VERSION ""

NS_ :

BS_:

BU_: IHU

BO_ 3221225472 VECTOR__INDEPENDENT_SIG_MSG: 0 Vector__XXX
 SG_ Diag_ICM_REQ : 0|64@0+ (1,0) [0|0] "" Vector__XXX
 SG_ Diag_ICM_RES : 0|64@0+ (1,0) [0|0] "" Vector__XXX

BO_ 2015 DIAG_OBD_REQ_Broadcast: 8 Vector__XXX
 SG_ DIAG_OBD_REQ_Broadcast : 7|64@0+ (1,0) [0|0] ""  IHU

BO_ 0 New_Message_75: 8 Vector__XXX
 SG_ New_Signal_498 : 20|8@1+ (1,0) [0|0] "" Vector__XXX

BO_ 1536 NMm_Others: 8 Vector__XXX
 SG_ Nwmcommand : 0|1@0+ (1,0) [0|1] ""  IHU

BO_ 1928 Diag_DMC_REQ: 8 Vector__XXX
 SG_ Diag_DMC_REQ : 7|64@0+ (1,0) [0|0] ""  IHU

BO_ 1764 Calibration_Signals_REQ_ICM_7: 8 Vector__XXX
 SG_ Calibration_Signals_REQ_ICM_7 : 7|64@0+ (1,0) [0|0] ""  IHU

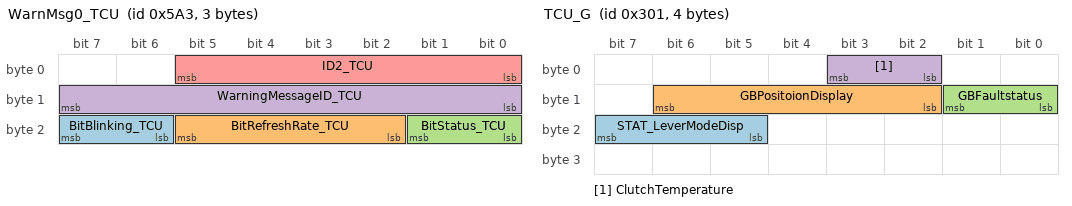
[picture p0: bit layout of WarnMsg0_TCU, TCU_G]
BO_ 1443 WarnMsg0_TCU: 3 Vector__XXX
 SG_ BitBlinking_TCU : 23|2@0+ (1,0) [0|3] ""  IHU
 SG_ BitRefreshRate_TCU : 21|4@0+ (1,0) [0|14] "second"  IHU
 SG_ BitStatus_TCU : 17|2@0+ (1,0) [0|3] ""  IHU
 SG_ WarningMessageID_TCU : 15|8@0+ (1,0) [0|255] ""  IHU
 SG_ ID2_TCU : 5|6@0+ (1,0) [0|63] ""  IHU

BO_ 769 TCU_G: 4 Vector__XXX
 SG_ STAT_LeverModeDisp : 23|3@0+ (1,0) [0|7] ""  IHU
 SG_ GBPositoionDisplay : 14|5@0+ (1,0) [0|31] ""  IHU
 SG_ GBFaultstatus : 9|2@0+ (1,0) [0|3] ""  IHU
 SG_ ClutchTemperature : 3|2@0+ (1,0) [0|3] ""  IHU

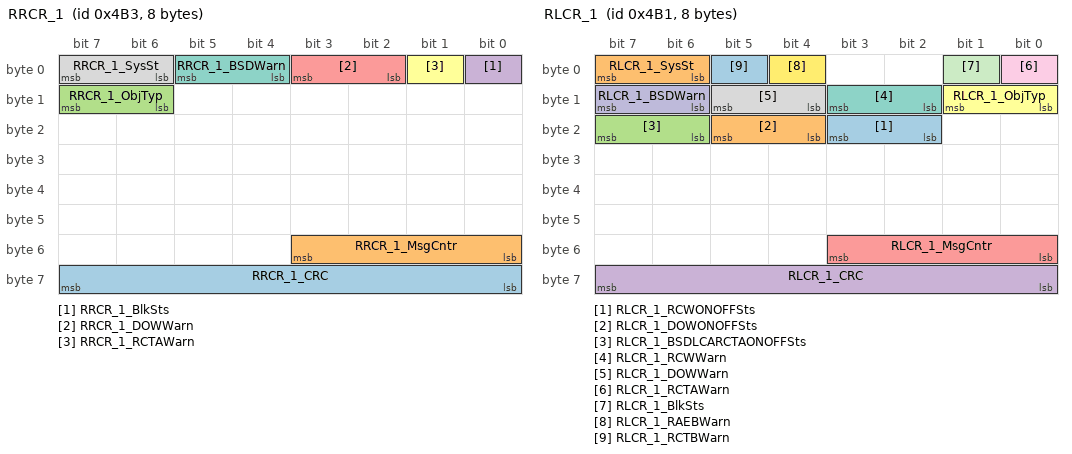
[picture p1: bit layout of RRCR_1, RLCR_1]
BO_ 1203 RRCR_1: 8 Vector__XXX
 SG_ RRCR_1_CRC : 63|8@0+ (1,0) [0|255] ""  IHU
 SG_ RRCR_1_MsgCntr : 51|4@0+ (1,0) [0|15] ""  IHU
 SG_ RRCR_1_ObjTyp : 15|2@0+ (1,0) [0|3] ""  IHU
 SG_ RRCR_1_BlkSts : 0|1@0+ (1,0) [0|1] ""  IHU
 SG_ RRCR_1_DOWWarn : 3|2@0+ (1,0) [0|3] ""  IHU
 SG_ RRCR_1_RCTAWarn : 1|1@0+ (1,0) [0|1] ""  IHU
 SG_ RRCR_1_BSDWarn : 5|2@0+ (1,0) [0|3] ""  IHU
 SG_ RRCR_1_SysSt : 7|2@0+ (1,0) [0|3] ""  IHU

BO_ 1201 RLCR_1: 8 Vector__XXX
 SG_ RLCR_1_RCWONOFFSts : 19|2@0+ (1,0) [0|3] ""  IHU
 SG_ RLCR_1_DOWONOFFSts : 21|2@0+ (1,0) [0|3] ""  IHU
 SG_ RLCR_1_BSDLCARCTAONOFFSts : 23|2@0+ (1,0) [0|3] ""  IHU
 SG_ RLCR_1_CRC : 63|8@0+ (1,0) [0|255] ""  IHU
 SG_ RLCR_1_MsgCntr : 51|4@0+ (1,0) [0|15] ""  IHU
 SG_ RLCR_1_ObjTyp : 9|2@0+ (1,0) [0|3] ""  IHU
 SG_ RLCR_1_RCWWarn : 11|2@0+ (1,0) [0|3] ""  IHU
 SG_ RLCR_1_DOWWarn : 13|2@0+ (1,0) [0|3] ""  IHU
 SG_ RLCR_1_RCTAWarn : 0|1@0+ (1,0) [0|1] ""  IHU
 SG_ RLCR_1_BSDWarn : 15|2@0+ (1,0) [0|3] ""  IHU
 SG_ RLCR_1_BlkSts : 1|1@0+ (1,0) [0|1] ""  IHU
 SG_ RLCR_1_RAEBWarn : 4|1@0+ (1,0) [0|1] ""  IHU
 SG_ RLCR_1_RCTBWarn : 5|1@0+ (1,0) [0|1] ""  IHU
 SG_ RLCR_1_SysSt : 7|2@0+ (1,0) [0|3] ""  IHU

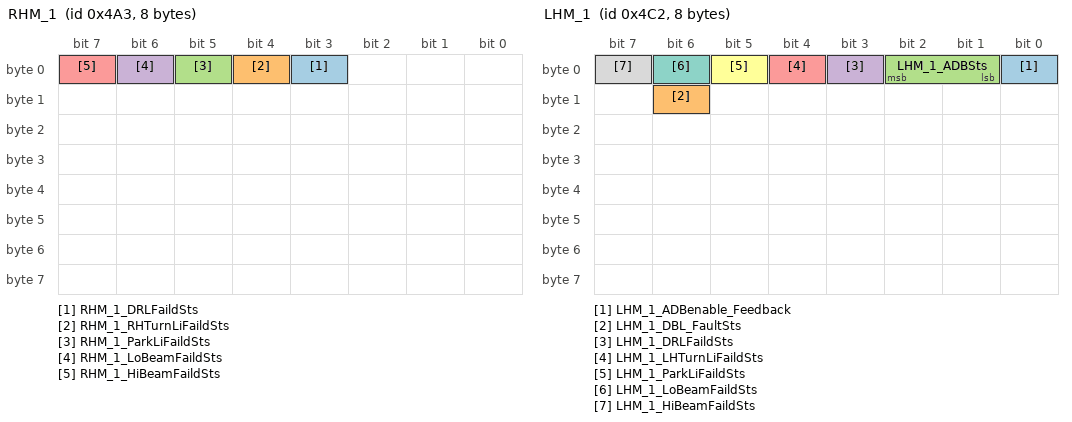
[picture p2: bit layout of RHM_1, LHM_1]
BO_ 1187 RHM_1: 8 Vector__XXX
 SG_ RHM_1_DRLFaildSts : 3|1@0+ (1,0) [0|1] ""  IHU
 SG_ RHM_1_RHTurnLiFaildSts : 4|1@0+ (1,0) [0|1] ""  IHU
 SG_ RHM_1_ParkLiFaildSts : 5|1@0+ (1,0) [0|1] ""  IHU
 SG_ RHM_1_LoBeamFaildSts : 6|1@0+ (1,0) [0|1] ""  IHU
 SG_ RHM_1_HiBeamFaildSts : 7|1@0+ (1,0) [0|1] ""  IHU

BO_ 1208 PPMI_1: 8 Vector__XXX
 SG_ PPMISt : 15|3@0+ (1,0) [0|7] ""  IHU
 SG_ PPMICounter : 6|1@0+ (1,0) [0|1] ""  IHU

BO_ 1218 LHM_1: 8 Vector__XXX
 SG_ LHM_1_ADBenable_Feedback : 0|1@0+ (1,0) [0|1] ""  IHU
 SG_ LHM_1_DBL_FaultSts : 14|1@0+ (1,0) [0|1] ""  IHU
 SG_ LHM_1_ADBSts : 2|2@0+ (1,0) [0|3] ""  IHU
 SG_ LHM_1_DRLFaildSts : 3|1@0+ (1,0) [0|1] ""  IHU
 SG_ LHM_1_LHTurnLiFaildSts : 4|1@0+ (1,0) [0|1] ""  IHU
 SG_ LHM_1_ParkLiFaildSts : 5|1@0+ (1,0) [0|1] ""  IHU
 SG_ LHM_1_LoBeamFaildSts : 6|1@0+ (1,0) [0|1] ""  IHU
 SG_ LHM_1_HiBeamFaildSts : 7|1@0+ (1,0) [0|1] ""  IHU

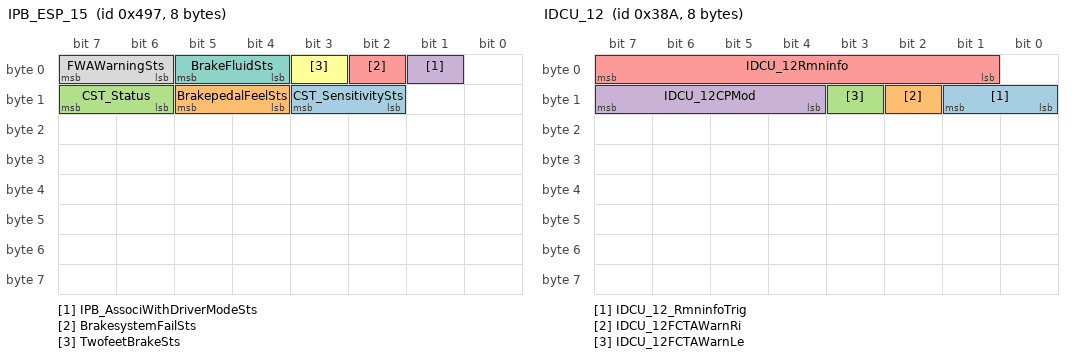
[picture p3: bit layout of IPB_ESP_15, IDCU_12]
BO_ 1175 IPB_ESP_15: 8 Vector__XXX
 SG_ CST_SensitivitySts : 11|2@0+ (1,0) [0|3] ""  IHU
 SG_ BrakepedalFeelSts : 13|2@0+ (1,0) [0|3] ""  IHU
 SG_ CST_Status : 15|2@0+ (1,0) [0|3] ""  IHU
 SG_ IPB_AssociWithDriverModeSts : 1|1@0+ (1,0) [0|1] ""  IHU
 SG_ BrakesystemFailSts : 2|1@0+ (1,0) [0|1] ""  IHU
 SG_ TwofeetBrakeSts : 3|1@0+ (1,0) [0|1] ""  IHU
 SG_ BrakeFluidSts : 5|2@0+ (1,0) [0|3] ""  IHU
 SG_ FWAWarningSts : 7|2@0+ (1,0) [0|3] ""  IHU

BO_ 1506 IHU_ICM_Interaction: 8 Vector__XXX
 SG_ IHU_ICM_InteractiveDisplayInfo : 7|64@0+ (1,0) [0|0] ""  IHU

BO_ 906 IDCU_12: 8 Vector__XXX
 SG_ IDCU_12_RmninfoTrig : 9|2@0+ (1,0) [0|3] ""  IHU
 SG_ IDCU_12FCTAWarnRi : 10|1@0+ (1,0) [0|1] ""  IHU
 SG_ IDCU_12FCTAWarnLe : 11|1@0+ (1,0) [0|1] ""  IHU
 SG_ IDCU_12CPMod : 15|4@0+ (1,0) [0|15] ""  IHU
 SG_ IDCU_12Rmninfo : 7|7@0+ (1,0) [0|127] ""  IHU

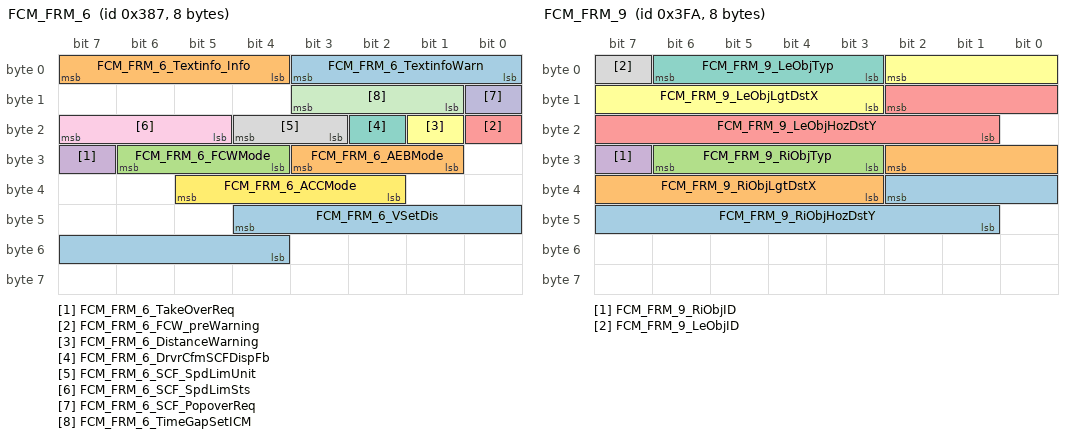
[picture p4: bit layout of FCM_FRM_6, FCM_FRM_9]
BO_ 903 FCM_FRM_6: 8 Vector__XXX
 SG_ FCM_FRM_6_VSetDis : 44|9@0+ (0.5,0) [0|255.5] "KPH"  IHU
 SG_ FCM_FRM_6_AEBMode : 27|3@0+ (1,0) [0|4] ""  IHU
 SG_ FCM_FRM_6_FCWMode : 30|3@0+ (1,0) [0|4] ""  IHU
 SG_ FCM_FRM_6_TakeOverReq : 31|1@0+ (1,0) [0|1] ""  IHU
 SG_ FCM_FRM_6_FCW_preWarning : 16|1@0+ (1,0) [0|1] ""  IHU
 SG_ FCM_FRM_6_DistanceWarning : 17|1@0+ (1,0) [0|1] ""  IHU
 SG_ FCM_FRM_6_DrvrCfmSCFDispFb : 18|1@0+ (1,0) [0|1] ""  IHU
 SG_ FCM_FRM_6_SCF_SpdLimUnit : 20|2@0+ (1,0) [0|3] ""  IHU
 SG_ FCM_FRM_6_SCF_SpdLimSts : 23|3@0+ (1,0) [0|7] ""  IHU
 SG_ FCM_FRM_6_SCF_PopoverReq : 8|1@0+ (1,0) [0|1] ""  IHU
 SG_ FCM_FRM_6_TimeGapSetICM : 11|3@0+ (1,0) [0|7] ""  IHU
 SG_ FCM_FRM_6_ACCMode : 37|4@0+ (1,0) [0|15] ""  IHU
 SG_ FCM_FRM_6_TextinfoWarn : 3|4@0+ (1,0) [0|15] ""  IHU
 SG_ FCM_FRM_6_Textinfo_Info : 7|4@0+ (1,0) [0|15] ""  IHU

BO_ 1020 FCM_10: 8 Vector__XXX
 SG_ FCM_10_EgoLeftLineHeatgAg : 44|9@0+ (0.004,-1.02) [-1.02|1.02] "Rad"  IHU
 SG_ FCM_10_ELKIntvMod : 47|3@0+ (1,0) [0|7] ""  IHU
 SG_ FCM_10_WarnModSts : 33|2@0+ (1,0) [0|3] ""  IHU
 SG_ FCM_10_SLAONOFFSts : 35|2@0+ (1,0) [0|3] ""  IHU
 SG_ FCM_10_TJAICAExitTextInfoSts : 37|2@0+ (1,0) [0|3] ""  IHU
 SG_ FCM_10_LDPTJAELKTakeoverReq : 39|2@0+ (1,0) [0|3] ""  IHU
 SG_ FCM_10_TJAICAEnaRcmend : 24|1@0+ (1,0) [0|1] ""  IHU
 SG_ FCM_10_TJAICATextinfo : 27|3@0+ (1,0) [0|7] ""  IHU
 SG_ FCM_10_TSINoParkWarn : 28|1@0+ (1,0) [0|1] ""  IHU
 SG_ FCM_10_ELKSysSts : 31|3@0+ (1,0) [0|7] ""  IHU
 SG_ FCM_10_LDWSysSts : 18|3@0+ (1,0) [0|7] ""  IHU
 SG_ FCM_10_LDPSysSts : 21|3@0+ (1,0) [0|7] ""  IHU
 SG_ FCM_10_TLITrfcLi : 23|2@0+ (1,0) [0|3] ""  IHU
 SG_ FCM_10_TSISgnLongStayDisp : 11|4@0+ (1,0) [0|15] ""  IHU
 SG_ FCM_10_TSISgnForb : 15|4@0+ (1,0) [0|15] ""  IHU
 SG_ FCM_10_TSISgnGiWay : 3|4@0+ (1,0) [0|15] ""  IHU
 SG_ FCM_10_TLISysSts : 5|2@0+ (1,0) [0|3] ""  IHU
 SG_ FCM_10_TSISysSts : 7|2@0+ (1,0) [0|3] ""  IHU

BO_ 1018 FCM_FRM_9: 8 Vector__XXX
 SG_ FCM_FRM_9_RiObjHozDstY : 34|10@0+ (0.1,-50) [-50|50] "m"  IHU
 SG_ FCM_FRM_9_RiObjLgtDstX : 26|8@0+ (0.5,0) [0|127] "m"  IHU
 SG_ FCM_FRM_9_RiObjTyp : 30|4@0+ (1,0) [0|15] ""  IHU
 SG_ FCM_FRM_9_RiObjID : 31|1@0+ (1,0) [0|1] ""  IHU
 SG_ FCM_FRM_9_LeObjHozDstY : 10|10@0+ (0.1,-50) [-50|50] "m"  IHU
 SG_ FCM_FRM_9_LeObjLgtDstX : 2|8@0+ (0.5,0) [0|127] "m"  IHU
 SG_ FCM_FRM_9_LeObjTyp : 6|4@0+ (1,0) [0|15] ""  IHU
 SG_ FCM_FRM_9_LeObjID : 7|1@0+ (1,0) [0|1] ""  IHU

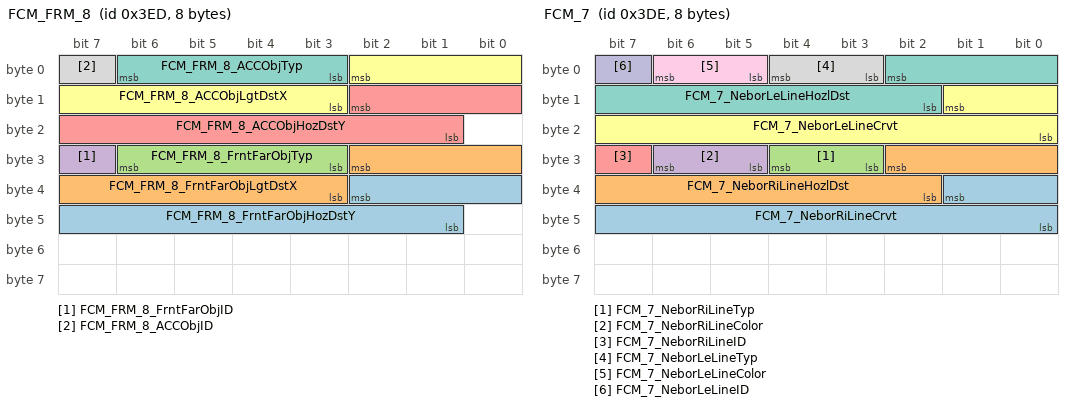
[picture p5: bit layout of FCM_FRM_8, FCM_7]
BO_ 1005 FCM_FRM_8: 8 Vector__XXX
 SG_ FCM_FRM_8_FrntFarObjHozDstY : 34|10@0+ (0.1,-50) [-50|50] "m"  IHU
 SG_ FCM_FRM_8_FrntFarObjLgtDstX : 26|8@0+ (0.5,0) [0|127] "m"  IHU
 SG_ FCM_FRM_8_FrntFarObjTyp : 30|4@0+ (1,0) [0|15] ""  IHU
 SG_ FCM_FRM_8_FrntFarObjID : 31|1@0+ (1,0) [0|1] ""  IHU
 SG_ FCM_FRM_8_ACCObjHozDstY : 10|10@0+ (0.1,-50) [-50|50] "m"  IHU
 SG_ FCM_FRM_8_ACCObjLgtDstX : 2|8@0+ (0.5,0) [0|127] "m"  IHU
 SG_ FCM_FRM_8_ACCObjTyp : 6|4@0+ (1,0) [0|15] ""  IHU
 SG_ FCM_FRM_8_ACCObjID : 7|1@0+ (1,0) [0|1] ""  IHU

BO_ 990 FCM_7: 8 Vector__XXX
 SG_ FCM_7_NeborRiLineCrvt : 33|10@0+ (6E-005,-0.0156) [-0.0156|0.0156] "1/m"  IHU
 SG_ FCM_7_NeborRiLineHozlDst : 26|9@0+ (0.1,-25) [-25|25] "m"  IHU
 SG_ FCM_7_NeborRiLineTyp : 28|2@0+ (1,0) [0|3] ""  IHU
 SG_ FCM_7_NeborRiLineColor : 30|2@0+ (1,0) [0|3] ""  IHU
 SG_ FCM_7_NeborRiLineID : 31|1@0+ (1,0) [0|1] ""  IHU
 SG_ FCM_7_NeborLeLineCrvt : 9|10@0+ (6E-005,-0.0156) [-0.0156|0.0156] "1/m"  IHU
 SG_ FCM_7_NeborLeLineHozlDst : 2|9@0+ (0.1,-25) [-25|25] "m"  IHU
 SG_ FCM_7_NeborLeLineTyp : 4|2@0+ (1,0) [0|3] ""  IHU
 SG_ FCM_7_NeborLeLineColor : 6|2@0+ (1,0) [0|3] ""  IHU
 SG_ FCM_7_NeborLeLineID : 7|1@0+ (1,0) [0|1] ""  IHU

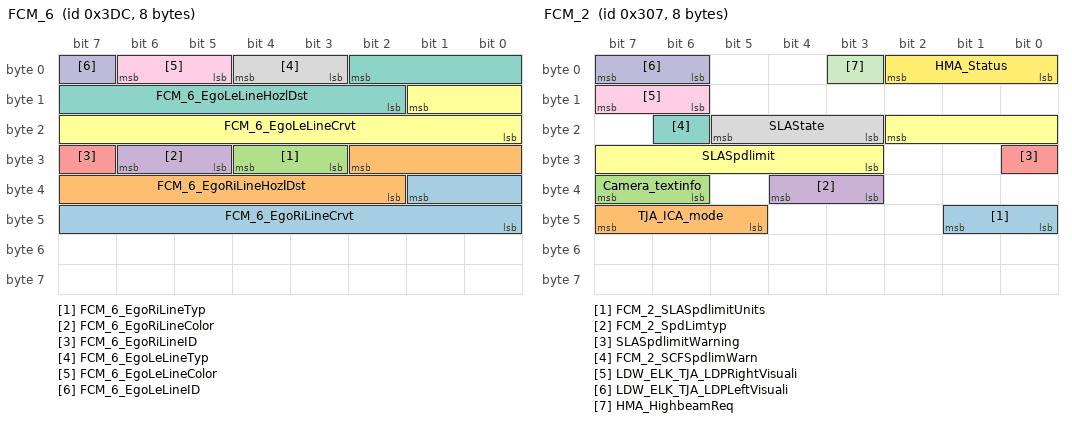
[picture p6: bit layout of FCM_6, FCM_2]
BO_ 988 FCM_6: 8 Vector__XXX
 SG_ FCM_6_EgoRiLineCrvt : 33|10@0+ (6E-005,-0.0156) [-0.0156|0.0156] "1/m"  IHU
 SG_ FCM_6_EgoRiLineHozlDst : 26|9@0+ (0.1,-25) [-25|25] "m"  IHU
 SG_ FCM_6_EgoRiLineTyp : 28|2@0+ (1,0) [0|3] ""  IHU
 SG_ FCM_6_EgoRiLineColor : 30|2@0+ (1,0) [0|3] ""  IHU
 SG_ FCM_6_EgoRiLineID : 31|1@0+ (1,0) [0|1] ""  IHU
 SG_ FCM_6_EgoLeLineCrvt : 9|10@0+ (6E-005,-0.0156) [-0.0156|0.0156] "1/m"  IHU
 SG_ FCM_6_EgoLeLineHozlDst : 2|9@0+ (0.1,-25) [-25|25] "m"  IHU
 SG_ FCM_6_EgoLeLineTyp : 4|2@0+ (1,0) [0|3] ""  IHU
 SG_ FCM_6_EgoLeLineColor : 6|2@0+ (1,0) [0|3] ""  IHU
 SG_ FCM_6_EgoLeLineID : 7|1@0+ (1,0) [0|1] ""  IHU

BO_ 775 FCM_2: 8 Vector__XXX
 SG_ FCM_2_SLASpdlimitUnits : 41|2@0+ (1,0) [0|3] ""  IHU
 SG_ TJA_ICA_mode : 47|3@0+ (1,0) [0|4] ""  IHU
 SG_ Camera_textinfo : 39|2@0+ (1,0) [0|3] ""  IHU
 SG_ FCM_2_SpdLimtyp : 36|2@0+ (1,0) [0|3] ""  IHU
 SG_ SLASpdlimitWarning : 24|1@0+ (1,0) [0|1] ""  IHU
 SG_ SLASpdlimit : 18|8@0+ (1,0) [0|255] ""  IHU
 SG_ FCM_2_SCFSpdlimWarn : 22|1@0+ (1,0) [0|1] ""  IHU
 SG_ SLAState : 21|3@0+ (1,0) [0|7] ""  IHU
 SG_ LDW_ELK_TJA_LDPRightVisuali : 15|2@0+ (1,0) [0|3] ""  IHU
 SG_ LDW_ELK_TJA_LDPLeftVisuali : 7|2@0+ (1,0) [0|3] ""  IHU
 SG_ HMA_HighbeamReq : 3|1@0+ (1,0) [0|1] ""  IHU
 SG_ HMA_Status : 2|3@0+ (1,0) [0|7] ""  IHU

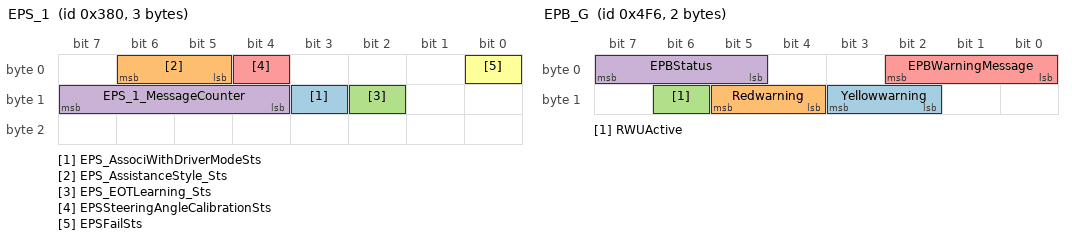
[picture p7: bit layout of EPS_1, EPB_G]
BO_ 896 EPS_1: 3 Vector__XXX
 SG_ EPS_AssociWithDriverModeSts : 11|1@0+ (1,0) [0|1] ""  IHU
 SG_ EPS_AssistanceStyle_Sts : 6|2@0+ (1,0) [0|3] ""  IHU
 SG_ EPS_EOTLearning_Sts : 10|1@0+ (1,0) [0|1] ""  IHU
 SG_ EPS_1_MessageCounter : 15|4@0+ (1,0) [0|15] ""  IHU
 SG_ EPSSteeringAngleCalibrationSts : 4|1@0+ (1,0) [0|1] ""  IHU
 SG_ EPSFailSts : 0|1@0+ (1,0) [0|1] ""  IHU

BO_ 1270 EPB_G: 2 Vector__XXX
 SG_ Yellowwarning : 11|2@0+ (1,0) [0|3] ""  IHU
 SG_ Redwarning : 13|2@0+ (1,0) [0|3] ""  IHU
 SG_ RWUActive : 14|1@0+ (1,0) [0|1] ""  IHU
 SG_ EPBStatus : 7|3@0+ (1,0) [0|7] ""  IHU
 SG_ EPBWarningMessage : 2|3@0+ (1,0) [0|7] ""  IHU

BO_ 640 EMS_1_G: 8 Vector__XXX
 SG_ EngineSts : 58|1@0+ (1,0) [0|1] ""  IHU
 SG_ GearReduceIndication : 57|1@0+ (1,0) [0|1] ""  IHU
 SG_ GearRaiseIndication : 56|1@0+ (1,0) [0|1] ""  IHU
 SG_ TargetGearPosition : 49|3@0+ (1,0) [0|7] ""  IHU
 SG_ SSMStatus : 52|3@0+ (1,0) [0|7] ""  IHU
 SG_ EPCSts : 53|1@0+ (1,0) [0|1] ""  IHU
 SG_ EngineSpeedValidData : 54|1@0+ (1,0) [0|1] ""  IHU
 SG_ FuelRollingCounterValidData : 55|1@0+ (1,0) [0|1] ""  IHU
 SG_ ISS_Sts_GS : 44|5@0+ (1,0) [0|31] ""  IHU
 SG_ EngineSpeed : 39|11@0+ (4,0) [0|8000] "rpm"  IHU
 SG_ FuelRollingCounter : 31|8@0+ (7.88519E-005,0) [0|0.020028382] "ltr"  IHU
 SG_ EngineCoolantTemperture : 23|8@0+ (0.75,-48) [-48|142.5] "¡æ"  IHU
 SG_ CruiseControlStsForDisplay : 9|2@0+ (1,0) [0|3] ""  IHU
 SG_ ECSControlSts : 10|1@0+ (1,0) [0|1] ""  IHU
 SG_ EngineCoolantTempertureFailSts : 11|1@0+ (1,0) [0|1] ""  IHU
 SG_ MILSts : 13|2@0+ (1,0) [0|3] ""  IHU
 SG_ IEMSts : 1|1@0+ (1,0) [0|1] ""  IHU
 SG_ GPFWarning : 3|2@0+ (1,0) [0|3] ""  IHU

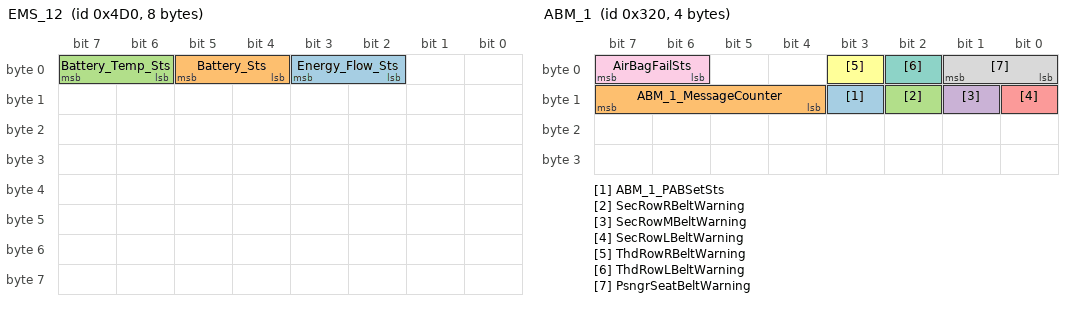
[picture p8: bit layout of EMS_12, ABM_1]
BO_ 1232 EMS_12: 8 Vector__XXX
 SG_ Energy_Flow_Sts : 3|2@0+ (1,0) [0|3] ""  IHU
 SG_ Battery_Sts : 5|2@0+ (1,0) [0|3] ""  IHU
 SG_ Battery_Temp_Sts : 7|2@0+ (1,0) [0|3] ""  IHU

BO_ 1146 EGS_2: 4 Vector__XXX
 SG_ AllWarningInfo : 5|3@0+ (1,0) [0|7] ""  IHU

BO_ 1158 AWD_2: 8 Vector__XXX
 SG_ AWDoutserviceDispRq : 7|2@0+ (1,0) [0|3] ""  IHU

BO_ 1095 AFS_1: 8 Vector__XXX
 SG_ AFS_FaultSts : 6|1@0+ (1,0) [0|1] ""  IHU

BO_ 704 ABS_ESP_G: 7 Vector__XXX
 SG_ ABS_ESP_Checksum : 55|8@0+ (1,0) [0|255] ""  IHU
 SG_ CDPFailSts : 46|1@0+ (1,0) [0|1] ""  IHU
 SG_ AVHFailSts : 45|1@0+ (1,0) [0|1] ""  IHU
 SG_ AVHSts : 44|2@0+ (1,0) [0|3] ""  IHU
 SG_ HDCFailSts : 42|1@0+ (1,0) [0|1] ""  IHU
 SG_ HDCCtrlSts : 41|2@0+ (1,0) [0|3] ""  IHU
 SG_ DiagnosticSessionSts : 47|1@0+ (1,0) [0|1] ""  IHU
 SG_ ABS_ESP_MessageCounter : 35|4@0+ (1,0) [0|15] ""  IHU
 SG_ VehicleSpeedVSOSigValidData : 31|1@0+ (1,0) [0|1] ""  IHU
 SG_ VehicleSpeedVSOSig : 12|13@0+ (0.0625,0) [0|511.875] "km/h"  IHU
 SG_ CDPActive : 13|1@0+ (1,0) [0|1] ""  IHU
 SG_ ESPSwitchStatus : 14|1@0+ (1,0) [0|1] ""  IHU
 SG_ HHCFailSts : 15|1@0+ (1,0) [0|1] ""  IHU
 SG_ VDCActive : 0|1@0+ (1,0) [0|1] ""  IHU
 SG_ TCSActive : 1|1@0+ (1,0) [0|1] ""  IHU
 SG_ VDCFailSts : 2|1@0+ (1,0) [0|1] ""  IHU
 SG_ TCSFailSts : 3|1@0+ (1,0) [0|1] ""  IHU
 SG_ EBDFailSts : 4|1@0+ (1,0) [0|1] ""  IHU
 SG_ ABSFailSts : 5|1@0+ (1,0) [0|1] ""  IHU
 SG_ AVHWarningMessage : 7|1@0+ (1,0) [0|1] ""  IHU

BO_ 745 ABS_ESP_1: 8 Vector__XXX
 SG_ AEBdecAvailable : 50|1@0+ (1,0) [0|1] ""  IHU
 SG_ AEBdecActive : 31|1@0+ (1,0) [0|1] ""  IHU

BO_ 800 ABM_1: 4 Vector__XXX
 SG_ ABM_1_PABSetSts : 11|1@0+ (1,0) [0|1] ""  IHU
 SG_ ABM_1_MessageCounter : 15|4@0+ (1,0) [0|15] ""  IHU
 SG_ SecRowRBeltWarning : 10|1@0+ (1,0) [0|1] ""  IHU
 SG_ SecRowMBeltWarning : 9|1@0+ (1,0) [0|1] ""  IHU
 SG_ SecRowLBeltWarning : 8|1@0+ (1,0) [0|1] ""  IHU
 SG_ ThdRowRBeltWarning : 3|1@0+ (1,0) [0|1] ""  IHU
 SG_ ThdRowLBeltWarning : 2|1@0+ (1,0) [0|1] ""  IHU
 SG_ PsngrSeatBeltWarning : 1|2@0+ (1,0) [0|3] ""  IHU
 SG_ AirBagFailSts : 7|2@0+ (1,0) [0|3] ""  IHU

BO_ 1944 Diag_DMC_RES: 8 IHU
 SG_ Diag_DMC_RES : 7|64@0+ (1,0) [0|0] "" Vector__XXX

BO_ 1765 Calibration_Signals_RES_ICM_8: 8 IHU
 SG_ Calibration_Signals_RES_ICM_8 : 7|64@0+ (1,0) [0|0] "" Vector__XXX

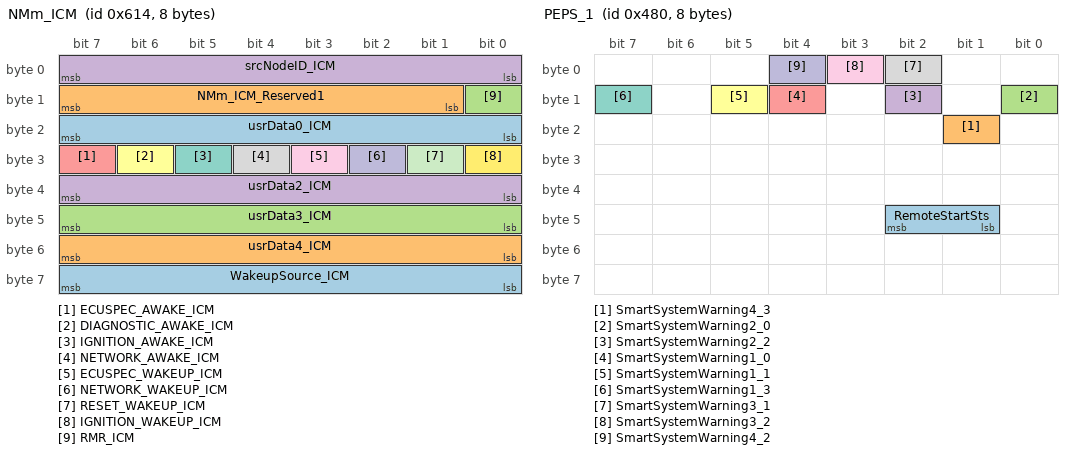
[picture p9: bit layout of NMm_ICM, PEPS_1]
BO_ 1556 NMm_ICM: 8 IHU
 SG_ WakeupSource_ICM : 63|8@0+ (1,0) [0|255] "" Vector__XXX
 SG_ usrData4_ICM : 55|8@0+ (1,0) [0|255] "" Vector__XXX
 SG_ usrData3_ICM : 47|8@0+ (1,0) [0|255] "" Vector__XXX
 SG_ usrData2_ICM : 39|8@0+ (1,0) [0|255] "" Vector__XXX
 SG_ ECUSPEC_AWAKE_ICM : 31|1@0+ (1,0) [0|1] "" Vector__XXX
 SG_ DIAGNOSTIC_AWAKE_ICM : 30|1@0+ (1,0) [0|1] "" Vector__XXX
 SG_ IGNITION_AWAKE_ICM : 29|1@0+ (1,0) [0|1] "" Vector__XXX
 SG_ NETWORK_AWAKE_ICM : 28|1@0+ (1,0) [0|1] "" Vector__XXX
 SG_ ECUSPEC_WAKEUP_ICM : 27|1@0+ (1,0) [0|1] "" Vector__XXX
 SG_ NETWORK_WAKEUP_ICM : 26|1@0+ (1,0) [0|1] "" Vector__XXX
 SG_ RESET_WAKEUP_ICM : 25|1@0+ (1,0) [0|1] "" Vector__XXX
 SG_ IGNITION_WAKEUP_ICM : 24|1@0+ (1,0) [0|1] "" Vector__XXX
 SG_ usrData0_ICM : 23|8@0+ (1,0) [0|255] "" Vector__XXX
 SG_ NMm_ICM_Reserved1 : 15|7@0+ (1,0) [0|127] "" Vector__XXX
 SG_ RMR_ICM : 8|1@0+ (1,0) [0|1] "" Vector__XXX
 SG_ srcNodeID_ICM : 7|8@0+ (1,0) [0|255] "" Vector__XXX

BO_ 1152 PEPS_1: 8 Vector__XXX
 SG_ RemoteStartSts : 42|2@0+ (1,0) [0|3] ""  IHU
 SG_ SmartSystemWarning4_3 : 17|1@0+ (1,0) [0|1] ""  IHU
 SG_ SmartSystemWarning2_0 : 8|1@0+ (1,0) [0|1] ""  IHU
 SG_ SmartSystemWarning2_2 : 10|1@0+ (1,0) [0|1] ""  IHU
 SG_ SmartSystemWarning1_0 : 12|1@0+ (1,0) [0|1] ""  IHU
 SG_ SmartSystemWarning1_1 : 13|1@0+ (1,0) [0|1] ""  IHU
 SG_ SmartSystemWarning1_3 : 15|1@0+ (1,0) [0|1] ""  IHU
 SG_ SmartSystemWarning3_1 : 2|1@0+ (1,0) [0|1] ""  IHU
 SG_ SmartSystemWarning3_2 : 3|1@0+ (1,0) [0|1] ""  IHU
 SG_ SmartSystemWarning4_2 : 4|1@0+ (1,0) [0|1] ""  IHU

BO_ 1219 PAS_1: 8 Vector__XXX
 SG_ PAS_1_DriverDoorSIllSts : 0|1@0+ (1,0) [0|1] ""  IHU

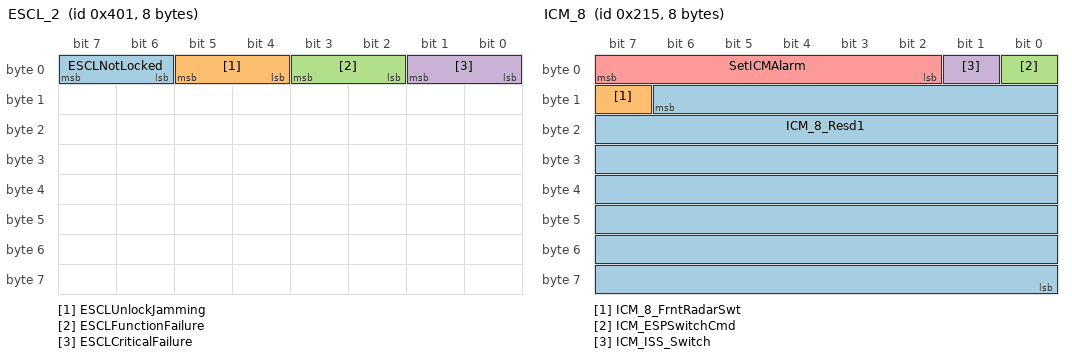
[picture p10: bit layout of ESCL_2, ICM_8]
BO_ 1025 ESCL_2: 8 Vector__XXX
 SG_ ESCLNotLocked : 7|2@0+ (1,0) [0|1] ""  IHU
 SG_ ESCLUnlockJamming : 5|2@0+ (1,0) [0|1] ""  IHU
 SG_ ESCLFunctionFailure : 3|2@0+ (1,0) [0|1] ""  IHU
 SG_ ESCLCriticalFailure : 1|2@0+ (1,0) [0|1] ""  IHU

BO_ 533 ICM_8: 8 IHU
 SG_ ICM_8_Resd1 : 14|55@0+ (1,0) [0|0] "" Vector__XXX
 SG_ ICM_8_FrntRadarSwt : 15|1@0+ (1,0) [0|1] "" Vector__XXX
 SG_ ICM_ESPSwitchCmd : 0|1@0+ (1,0) [0|1] "" Vector__XXX
 SG_ ICM_ISS_Switch : 1|1@0+ (1,0) [0|1] "" Vector__XXX
 SG_ SetICMAlarm : 7|6@0+ (1,0) [0|63] "" Vector__XXX

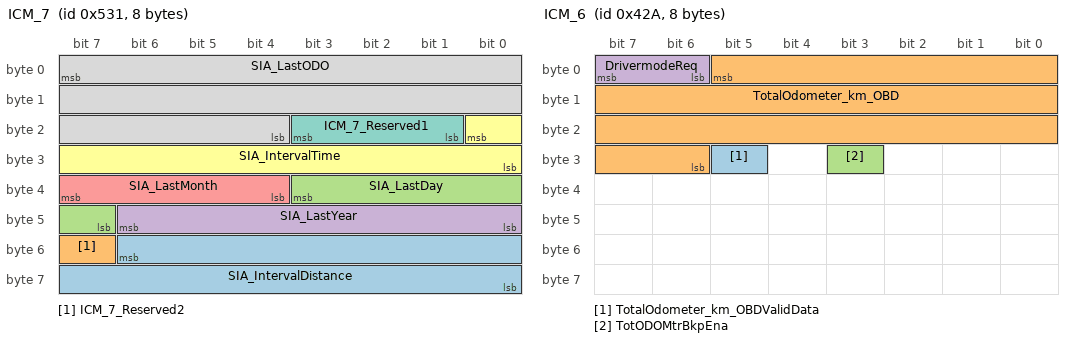
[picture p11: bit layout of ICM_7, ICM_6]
BO_ 1329 ICM_7: 8 IHU
 SG_ SIA_IntervalDistance : 54|15@0+ (1,0) [0|16383] "km" Vector__XXX
 SG_ ICM_7_Reserved2 : 55|1@0+ (1,0) [0|0] "" Vector__XXX
 SG_ SIA_LastDay : 35|5@0+ (1,0) [0|31] "day" Vector__XXX
 SG_ SIA_LastYear : 46|7@0+ (1,2000) [2000|2101] "year" Vector__XXX
 SG_ SIA_LastMonth : 39|4@0+ (1,0) [0|12] "month" Vector__XXX
 SG_ SIA_IntervalTime : 16|9@0+ (1,0) [0|365] "day" Vector__XXX
 SG_ ICM_7_Reserved1 : 19|3@0+ (1,0) [0|0] "" Vector__XXX
 SG_ SIA_LastODO : 7|20@0+ (1,0) [0|999999] "km" Vector__XXX

BO_ 1066 ICM_6: 8 IHU
 SG_ TotalOdometer_km_OBDValidData : 29|1@0+ (1,0) [0|1] "" Vector__XXX
 SG_ TotalOdometer_km_OBD : 5|24@0+ (0.1,0) [0|999999.9] "km" Vector__XXX
 SG_ TotODOMtrBkpEna : 27|1@0+ (1,0) [0|1] "" Vector__XXX
 SG_ DrivermodeReq : 7|2@0+ (1,0) [0|3] "" Vector__XXX

BO_ 647 ICM_5: 8 IHU
 SG_ ICM_5_Checksum : 63|8@0+ (1,0) [0|255] "" Vector__XXX
 SG_ ICM_5_MessageCounter : 51|4@0+ (1,0) [0|15] "" Vector__XXX
 SG_ ICM_DVDAudibleAlarmStyle : 34|2@0+ (1,0) [0|3] "" Vector__XXX
 SG_ ICM_DVDAudibleAlarm : 38|4@0+ (1,0) [0|15] "" Vector__XXX
 SG_ BrakeFluidWarning : 32|1@0+ (1,0) [0|1] "" Vector__XXX
 SG_ ICM_5_Reserved_2 : 47|10@0+ (1,0) [0|0] "" Vector__XXX
 SG_ ACC_Kilometre_Mile : 39|1@0+ (1,0) [0|1] "" Vector__XXX
 SG_ DriverSeatBeltSwitchQbit : 24|1@0+ (1,0) [0|1] "" Vector__XXX
 SG_ ICM_5_DriverSeatBeltSwitch : 25|1@0+ (1,0) [0|1] "" Vector__XXX
 SG_ CTP_DriveModeSet : 30|1@0+ (1,0) [0|1] "" Vector__XXX
 SG_ ICM_5_AlrmVolCtrl : 29|2@0+ (1,0) [0|3] "" Vector__XXX
 SG_ ICM_5_BackLiBriAdjmt : 27|2@0+ (1,0) [0|3] "" Vector__XXX
 SG_ AverageFuelConsumption50 : 23|9@0+ (0.1,0) [0|50] "L/100km" Vector__XXX
 SG_ ICM_5_FuelLevel : 15|8@0+ (1,0) [0|100] "%" Vector__XXX
 SG_ FuelValidData : 0|1@0+ (1,0) [0|1] "" Vector__XXX
 SG_ FuelOutOfRange : 1|1@0+ (1,0) [0|1] "" Vector__XXX
 SG_ FuelShortPower : 2|1@0+ (1,0) [0|1] "" Vector__XXX
 SG_ FuelShortGround : 3|1@0+ (1,0) [0|1] "" Vector__XXX
 SG_ HandBrakeSystemStsValidData : 4|1@0+ (1,0) [0|1] "" Vector__XXX
 SG_ HandBrakeSystemSts : 7|3@0+ (1,0) [0|7] "" Vector__XXX

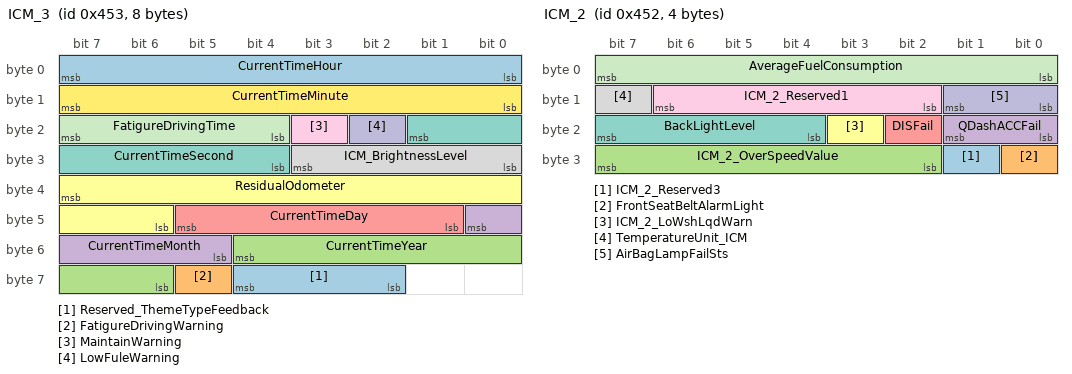
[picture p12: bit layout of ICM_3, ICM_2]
BO_ 1107 ICM_3: 8 IHU
 SG_ Reserved_ThemeTypeFeedback : 60|3@0+ (1,0) [0|0] "" Vector__XXX
 SG_ FatigureDrivingWarning : 61|1@0+ (1,0) [0|1] "" Vector__XXX
 SG_ CurrentTimeYear : 52|7@0+ (1,2000) [2000|2127] "" Vector__XXX
 SG_ CurrentTimeMonth : 40|4@0+ (1,0) [1|12] "" Vector__XXX
 SG_ CurrentTimeDay : 45|5@0+ (1,0) [1|31] "" Vector__XXX
 SG_ ResidualOdometer : 39|10@0+ (1,0) [0|999] "km" Vector__XXX
 SG_ CurrentTimeSecond : 17|6@0+ (1,0) [0|59] "" Vector__XXX
 SG_ ICM_BrightnessLevel : 27|4@0+ (1,0) [0|15] "" Vector__XXX
 SG_ MaintainWarning : 19|1@0+ (1,0) [0|1] "" Vector__XXX
 SG_ LowFuleWarning : 18|1@0+ (1,0) [0|1] "" Vector__XXX
 SG_ FatigureDrivingTime : 23|4@0+ (1,0) [0|15] "" Vector__XXX
 SG_ CurrentTimeMinute : 15|8@0+ (1,0) [0|59] "" Vector__XXX
 SG_ CurrentTimeHour : 7|8@0+ (1,0) [0|23] "" Vector__XXX

BO_ 1106 ICM_2: 4 IHU
 SG_ ICM_2_Reserved3 : 25|1@0+ (1,0) [0|0] "" Vector__XXX
 SG_ FrontSeatBeltAlarmLight : 24|1@0+ (1,0) [0|1] "" Vector__XXX
 SG_ ICM_2_OverSpeedValue : 31|6@0+ (1,0) [0|63] "" Vector__XXX
 SG_ QDashACCFail : 17|2@0+ (1,0) [0|3] "" Vector__XXX
 SG_ DISFail : 18|1@0+ (1,0) [0|1] "" Vector__XXX
 SG_ ICM_2_LoWshLqdWarn : 19|1@0+ (1,0) [0|1] "" Vector__XXX
 SG_ BackLightLevel : 23|4@0+ (1,0) [0|15] "" Vector__XXX
 SG_ TemperatureUnit_ICM : 15|1@0+ (1,0) [0|1] "" Vector__XXX
 SG_ ICM_2_Reserved1 : 14|5@0+ (1,0) [0|0] "" Vector__XXX
 SG_ AirBagLampFailSts : 9|2@0+ (1,0) [0|3] "" Vector__XXX
 SG_ AverageFuelConsumption : 7|8@0+ (0.1,0) [0|25.4] "L/100km" Vector__XXX

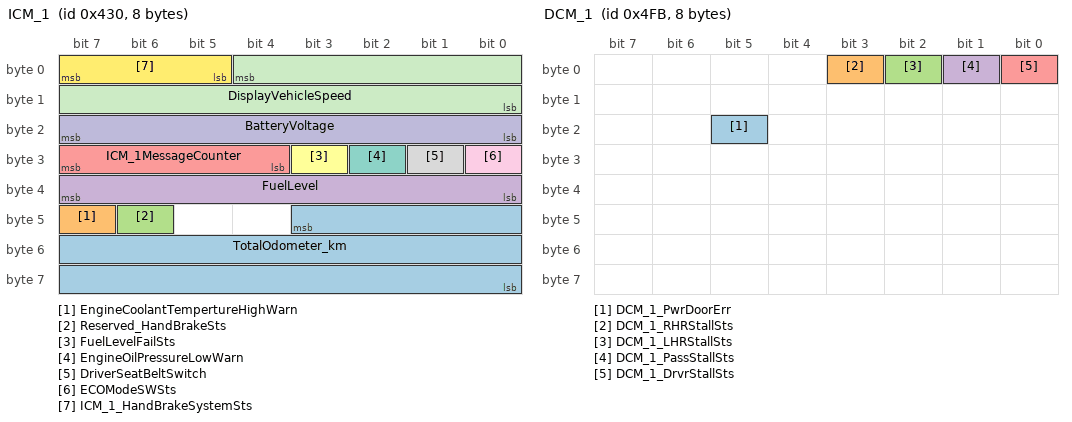
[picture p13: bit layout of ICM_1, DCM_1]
BO_ 1072 ICM_1: 8 IHU
 SG_ TotalOdometer_km : 43|20@0+ (1,0) [0|999999] "km" Vector__XXX
 SG_ EngineCoolantTempertureHighWarn : 47|1@0+ (1,0) [0|1] "" Vector__XXX
 SG_ Reserved_HandBrakeSts : 46|1@0+ (1,0) [0|1] "" Vector__XXX
 SG_ FuelLevel : 39|8@0+ (1,0) [0|100] "%" Vector__XXX
 SG_ ICM_1MessageCounter : 31|4@0+ (1,0) [0|15] "" Vector__XXX
 SG_ FuelLevelFailSts : 27|1@0+ (1,0) [0|1] "" Vector__XXX
 SG_ EngineOilPressureLowWarn : 26|1@0+ (1,0) [0|1] "" Vector__XXX
 SG_ DriverSeatBeltSwitch : 25|1@0+ (1,0) [0|1] "" Vector__XXX
 SG_ ECOModeSWSts : 24|1@0+ (1,0) [0|1] "" Vector__XXX
 SG_ BatteryVoltage : 23|8@0+ (0.1,0) [0|25.4] "V" Vector__XXX
 SG_ DisplayVehicleSpeed : 4|13@0+ (0.0625,0) [0|511.875] "km/h" Vector__XXX
 SG_ ICM_1_HandBrakeSystemSts : 7|3@0+ (1,0) [0|7] "" Vector__XXX

BO_ 1275 DCM_1: 8 Vector__XXX
 SG_ DCM_1_PwrDoorErr : 21|1@0+ (1,0) [0|1] ""  IHU
 SG_ DCM_1_RHRStallSts : 3|1@0+ (1,0) [0|1] ""  IHU
 SG_ DCM_1_LHRStallSts : 2|1@0+ (1,0) [0|1] ""  IHU
 SG_ DCM_1_PassStallSts : 1|1@0+ (1,0) [0|1] ""  IHU
 SG_ DCM_1_DrvrStallSts : 0|1@0+ (1,0) [0|1] ""  IHU

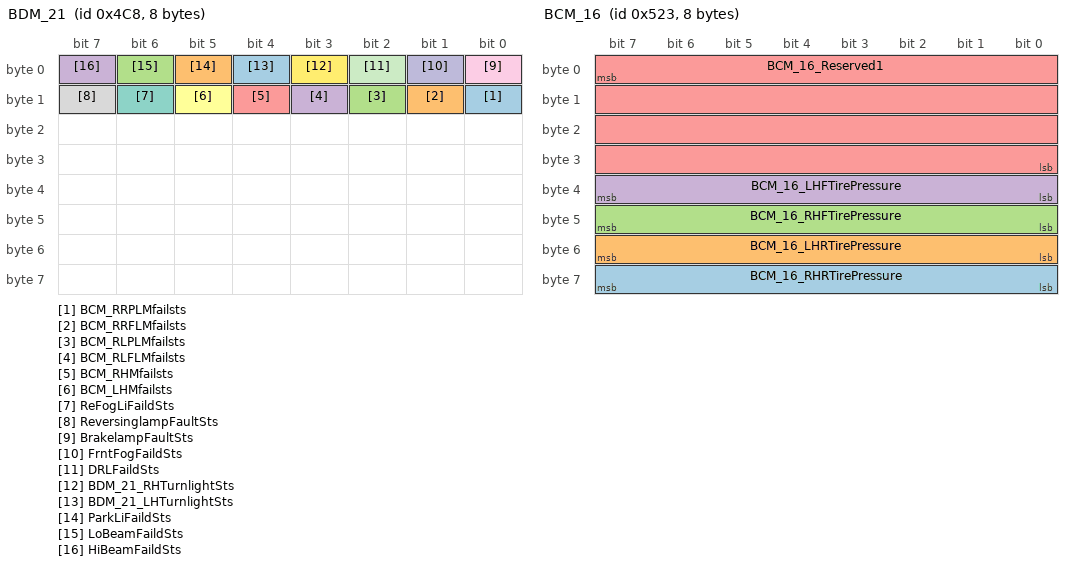
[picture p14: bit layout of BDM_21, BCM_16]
BO_ 1224 BDM_21: 8 Vector__XXX
 SG_ BCM_RRPLMfailsts : 8|1@0+ (1,0) [0|1] ""  IHU
 SG_ BCM_RRFLMfailsts : 9|1@0+ (1,0) [0|1] ""  IHU
 SG_ BCM_RLPLMfailsts : 10|1@0+ (1,0) [0|1] ""  IHU
 SG_ BCM_RLFLMfailsts : 11|1@0+ (1,0) [0|1] ""  IHU
 SG_ BCM_RHMfailsts : 12|1@0+ (1,0) [0|1] ""  IHU
 SG_ BCM_LHMfailsts : 13|1@0+ (1,0) [0|1] ""  IHU
 SG_ ReFogLiFaildSts : 14|1@0+ (1,0) [0|1] ""  IHU
 SG_ ReversinglampFaultSts : 15|1@0+ (1,0) [0|1] ""  IHU
 SG_ BrakelampFaultSts : 0|1@0+ (1,0) [0|1] ""  IHU
 SG_ FrntFogFaildSts : 1|1@0+ (1,0) [0|1] ""  IHU
 SG_ DRLFaildSts : 2|1@0+ (1,0) [0|1] ""  IHU
 SG_ BDM_21_RHTurnlightSts : 3|1@0+ (1,0) [0|1] ""  IHU
 SG_ BDM_21_LHTurnlightSts : 4|1@0+ (1,0) [0|1] ""  IHU
 SG_ ParkLiFaildSts : 5|1@0+ (1,0) [0|1] ""  IHU
 SG_ LoBeamFaildSts : 6|1@0+ (1,0) [0|1] ""  IHU
 SG_ HiBeamFaildSts : 7|1@0+ (1,0) [0|1] ""  IHU

BO_ 1315 BCM_16: 8 Vector__XXX
 SG_ BCM_16_RHRTirePressure : 63|8@0+ (1.373,0) [0|350] "kPa"  IHU
 SG_ BCM_16_LHRTirePressure : 55|8@0+ (1.373,0) [0|350] "kPa"  IHU
 SG_ BCM_16_RHFTirePressure : 47|8@0+ (1.373,0) [0|350] "kPa"  IHU
 SG_ BCM_16_LHFTirePressure : 39|8@0+ (1.373,0) [0|350] "kPa"  IHU
 SG_ BCM_16_Reserved1 : 7|32@0+ (1,0) [0|0] ""  IHU

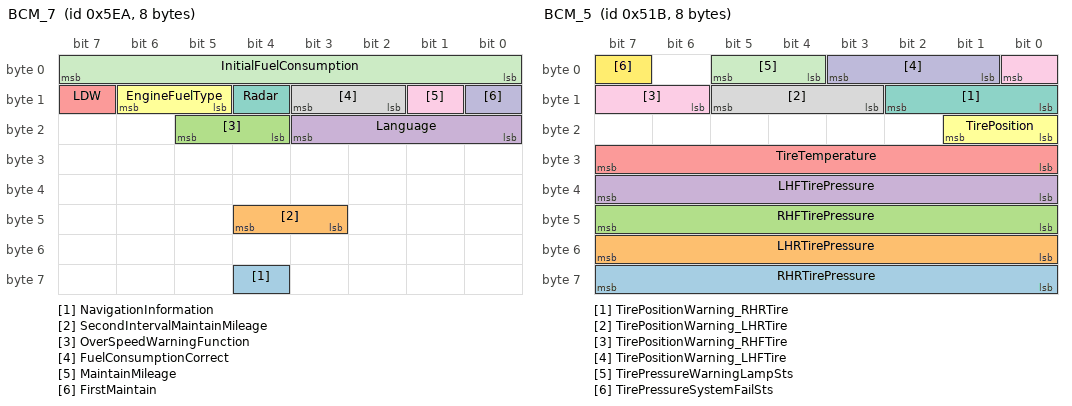
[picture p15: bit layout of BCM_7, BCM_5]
BO_ 1514 BCM_7: 8 Vector__XXX
 SG_ NavigationInformation : 60|1@0+ (1,0) [0|1] ""  IHU
 SG_ SecondIntervalMaintainMileage : 44|2@0+ (1,0) [0|3] ""  IHU
 SG_ OverSpeedWarningFunction : 21|2@0+ (1,0) [0|3] ""  IHU
 SG_ Language : 19|4@0+ (1,0) [0|15] ""  IHU
 SG_ LDW : 15|1@0+ (1,0) [0|1] ""  IHU
 SG_ EngineFuelType : 14|2@0+ (1,0) [0|3] ""  IHU
 SG_ Radar : 12|1@0+ (1,0) [0|1] ""  IHU
 SG_ FuelConsumptionCorrect : 11|2@0+ (1,0) [0|3] ""  IHU
 SG_ MaintainMileage : 9|1@0+ (1,0) [0|1] ""  IHU
 SG_ FirstMaintain : 8|1@0+ (1,0) [0|1] ""  IHU
 SG_ InitialFuelConsumption : 7|8@0+ (0.1,0) [0|25.5] ""  IHU

BO_ 1307 BCM_5: 8 Vector__XXX
 SG_ RHRTirePressure : 63|8@0+ (0.0177,0) [0|4.5] "bar"  IHU
 SG_ LHRTirePressure : 55|8@0+ (0.0177,0) [0|4.5] "bar"  IHU
 SG_ RHFTirePressure : 47|8@0+ (0.0177,0) [0|4.5] "bar"  IHU
 SG_ LHFTirePressure : 39|8@0+ (0.0177,0) [0|4.5] "bar"  IHU
 SG_ TireTemperature : 31|8@0+ (0.65,-40) [-40|125] "¡æ"  IHU
 SG_ TirePosition : 17|2@0+ (1,0) [0|3] ""  IHU
 SG_ TirePositionWarning_RHRTire : 10|3@0+ (1,0) [0|7] ""  IHU
 SG_ TirePositionWarning_LHRTire : 13|3@0+ (1,0) [0|7] ""  IHU
 SG_ TirePositionWarning_RHFTire : 0|3@0+ (1,0) [0|7] ""  IHU
 SG_ TirePositionWarning_LHFTire : 3|3@0+ (1,0) [0|7] ""  IHU
 SG_ TirePressureWarningLampSts : 5|2@0+ (1,0) [0|3] ""  IHU
 SG_ TirePressureSystemFailSts : 7|1@0+ (1,0) [0|1] ""  IHU

BO_ 914 BCM_4: 8 Vector__XXX
 SG_ DRLModeSts : 58|1@0+ (1,0) [0|0] ""  IHU
 SG_ HeadlampDelayLightSts : 57|1@0+ (1,0) [0|1] ""  IHU
 SG_ AutolockSts : 56|1@0+ (1,0) [0|1] ""  IHU
 SG_ AutoFoldSts : 63|1@0+ (1,0) [0|1] ""  IHU
 SG_ HeadlampHeightFeedbackSts : 52|3@0+ (1,0) [0|7] ""  IHU
 SG_ RemoteLockFeedbackSts : 54|2@0+ (1,0) [0|3] ""  IHU
 SG_ BCM_4_DriverDoorLockSts : 31|1@0+ (1,0) [0|1] ""  IHU
 SG_ DrvrDoorUnlckOnlySts : 10|1@0+ (1,0) [0|1] ""  IHU
 SG_ FGHeat_Req_CmdFeedback : 7|1@0+ (1,0) [0|1] ""  IHU
 SG_ RearFoglightFaultSts : 61|1@0+ (1,0) [0|1] ""  IHU
 SG_ BCM_4_ChildSafetySts : 60|2@0+ (1,0) [0|3] ""  IHU
 SG_ WiperSensitivitySWSts : 44|3@0+ (1,0) [0|7] ""  IHU
 SG_ RainSensorFailSts : 41|1@0+ (1,0) [0|1] ""  IHU
 SG_ ReversinglampFaultSts : 40|1@0+ (1,0) [0|1] ""  IHU
 SG_ BCM_4_FrontFogLightSts : 37|1@0+ (1,0) [0|1] ""  IHU
 SG_ BrakelampFaultSts : 36|1@0+ (1,0) [0|1] ""  IHU
 SG_ BCM_4_ReverseGearSts : 35|1@0+ (1,0) [0|1] ""  IHU
 SG_ BCM_4_RearFogLightSts : 34|1@0+ (1,0) [0|1] ""  IHU
 SG_ BCM_4_TrunkSts : 30|1@0+ (1,0) [0|1] ""  IHU
 SG_ BCM_4_LHRdoorSts : 29|1@0+ (1,0) [0|1] ""  IHU
 SG_ BCM_4_RHRDoorSts : 28|1@0+ (1,0) [0|1] ""  IHU
 SG_ BCM_4_HoodSts : 26|1@0+ (1,0) [0|1] ""  IHU
 SG_ BCM_4_PsngrDoorSts : 25|1@0+ (1,0) [0|1] ""  IHU
 SG_ BCM_4_DriverDoorSts : 24|1@0+ (1,0) [0|1] ""  IHU
 SG_ FollowMeTimeSts : 23|4@0+ (1,0) [0|15] ""  IHU
 SG_ RVSMode : 19|1@0+ (1,0) [0|1] ""  IHU
 SG_ BCM_4_DirectionIndLeft : 17|1@0+ (1,0) [0|1] ""  IHU
 SG_ BCM_4_DirectionIndRight : 16|1@0+ (1,0) [0|1] ""  IHU
 SG_ BCM_4_DRLSts : 15|1@0+ (1,0) [0|1] ""  IHU
 SG_ BCM_4_HighBeamSts : 12|1@0+ (1,0) [0|1] ""  IHU
 SG_ BCM_4_ParkLightSts : 11|1@0+ (1,0) [0|1] ""  IHU
 SG_ BCM_4_LHTurnlightSts : 9|1@0+ (1,0) [0|1] ""  IHU
 SG_ BCM_4_RHTurnlightSts : 8|1@0+ (1,0) [0|1] ""  IHU
 SG_ BCM_4_KeySts : 6|2@0+ (1,0) [0|3] ""  IHU
 SG_ LightDetected : 4|1@0+ (1,0) [0|1] ""  IHU
 SG_ KeyRemindWarning : 3|1@0+ (1,0) [0|1] ""  IHU
 SG_ BCM_4_ArmingSts : 1|2@0+ (1,0) [0|3] ""  IHU

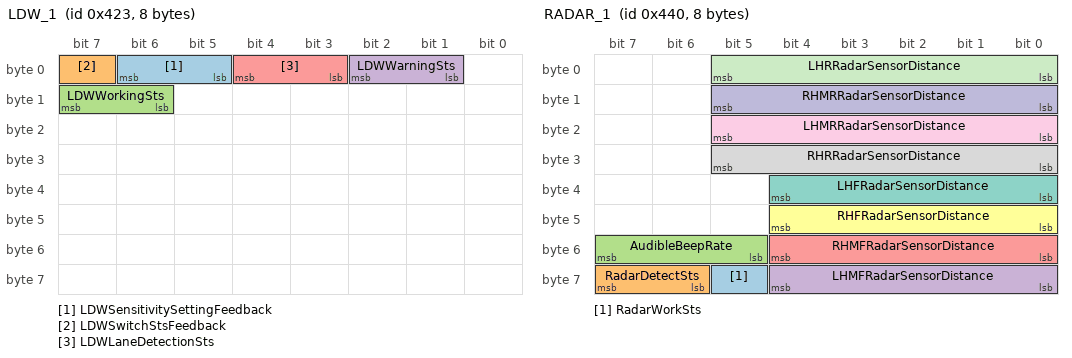
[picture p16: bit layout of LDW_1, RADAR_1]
BO_ 1059 LDW_1: 8 Vector__XXX
 SG_ LDWSensitivitySettingFeedback : 6|2@0+ (1,0) [0|3] ""  IHU
 SG_ LDWSwitchStsFeedback : 7|1@0+ (1,0) [0|1] ""  IHU
 SG_ LDWWorkingSts : 15|2@0+ (1,0) [0|3] ""  IHU
 SG_ LDWWarningSts : 2|2@0+ (1,0) [0|3] ""  IHU
 SG_ LDWLaneDetectionSts : 4|2@0+ (1,0) [0|3] ""  IHU

BO_ 1088 RADAR_1: 8 Vector__XXX
 SG_ RadarWorkSts : 61|1@0+ (1,0) [0|1] ""  IHU
 SG_ RadarDetectSts : 63|2@0+ (1,0) [0|3] ""  IHU
 SG_ AudibleBeepRate : 55|3@0+ (1,0) [0|7] ""  IHU
 SG_ LHMFRadarSensorDistance : 60|5@0+ (5,25) [25|160] "cm"  IHU
 SG_ RHMFRadarSensorDistance : 52|5@0+ (5,25) [25|160] "cm"  IHU
 SG_ RHFRadarSensorDistance : 44|5@0+ (5,25) [25|160] "cm"  IHU
 SG_ LHFRadarSensorDistance : 36|5@0+ (5,25) [25|160] "cm"  IHU
 SG_ RHRRadarSensorDistance : 29|6@0+ (5,25) [25|180] "cm"  IHU
 SG_ LHMRRadarSensorDistance : 21|6@0+ (5,25) [25|180] "cm"  IHU
 SG_ RHMRRadarSensorDistance : 13|6@0+ (5,25) [25|180] "cm"  IHU
 SG_ LHRRadarSensorDistance : 5|6@0+ (5,25) [25|180] "cm"  IHU

CM_ BO_ 3221225472 "This is a message for not used signals, created by Vector CANdb++ DBC OLE DB Provider.";
CM_ BO_ 1928 "Source network message is \"NoMsgSendType, /\".
If no messages are received on source network, no messages are sent on the destination network.";
CM_ BO_ 1764 "Source network message is \"NoMsgSendType, /\".
If no messages are received on source network, no messages are sent on the destination network.";
CM_ BO_ 1443 "Source network message is \"NoMsgSendType, /\".
If no messages are received on source network, no messages are sent on the destination network.";
CM_ SG_ 1443 BitBlinking_TCU "This parameter defines the blinking frequency of a telltale";
CM_ SG_ 1443 BitRefreshRate_TCU "The value refresh rate defines the cycle time (1-14s) of the specific warning message (defined in value warning message ID)";
CM_ SG_ 1443 BitStatus_TCU "The status defines if a message is set or reset";
CM_ SG_ 1443 WarningMessageID_TCU "The value (0-254) defines the warning message ID (see warning message catalog) with this value the global ID for the warning which should be outputted is
defined";
CM_ SG_ 1443 ID2_TCU "Defines that the message is a warning message only if 32h is received a warning message should be generated";
CM_ BO_ 769 "Source network message is \"Cyclic, 100ms\".
If no messages are received on source network, no messages are sent on the destination network.";
CM_ SG_ 769 STAT_LeverModeDisp "Shows the physical position of the gearbox - the drive mode that is active in the MAM (TCU). This value is different from the physical lever position, if the gearbox has failures or engine is off. 
????EGS?????¦Ë???";
CM_ SG_ 769 GBPositoionDisplay "?????M1??£¬????5£¬???????????£¬??01101??????????????????
Low???CVT?§³?for PHEV!mao!TCU only has 0x0!dun!0x1!dun!0x2!dun!0x3!dun!0x4";
CM_ SG_ 769 GBFaultstatus "Activation gearbox error Lamp, only for ICM including LCD to light LED and LCD. This signal should be sent with ??AGErrorLamp?? simultaneously
For 6DCT,only has 00/01.
For CVT/AMT/AT, only has 00/01/10.";
CM_ BO_ 1203 "Source network message is \"Cyclic, 100ms\".
If no messages are received on source network, no messages are sent on the destination network.";
CM_ SG_ 1203 RRCR_1_CRC "CRC (SAE J1850 CRC-8)
Note: Details Please refer to specification??EE Standard Specification for CAN FD Network Implementation??section 2.3.2";
CM_ SG_ 1203 RRCR_1_MsgCntr "Rolling message counter(the maximum value of Alive counter is 15)
Note: Details Please refer to specification??EE Standard Specification for CAN FD Network Implementation??section 2.3.1";
CM_ SG_ 1203 RRCR_1_ObjTyp "Objective type
-00 (Ukwn)!mao! invalid??Unused objects, such as people??";
CM_ SG_ 1203 RRCR_1_BlkSts "Blockage Status(only for VEONEER)";
CM_ SG_ 1203 RRCR_1_DOWWarn "Door open warning";
CM_ SG_ 1203 RRCR_1_RCTAWarn "RCTA Warning";
CM_ SG_ 1203 RRCR_1_BSDWarn "Blind spot detection system Warning";
CM_ SG_ 1203 RRCR_1_SysSt "System State (only for VEONEER)";
CM_ BO_ 1201 "Source network message is \"Cyclic, 100ms\".
If no messages are received on source network, no messages are sent on the destination network.";
CM_ SG_ 1201 RLCR_1_CRC "CRC (SAE J1850 CRC-8)
Note: Details Please refer to specification??EE Standard Specification for CAN FD Network Implementation??section 2.3.2";
CM_ SG_ 1201 RLCR_1_MsgCntr "Rolling message counter(the maximum value of Alive counter is 15)
Note: Details Please refer to specification??EE Standard Specification for CAN FD Network Implementation??section 2.3.1";
CM_ SG_ 1201 RLCR_1_ObjTyp "Objective type
-00 (Ukwn)!mao! invalid??Unused objects, such as people??";
CM_ SG_ 1201 RLCR_1_RCWWarn "Rear Collision Warning Warning";
CM_ SG_ 1201 RLCR_1_DOWWarn "Door open warning Warning";
CM_ SG_ 1201 RLCR_1_RCTAWarn "RCTA Warning";
CM_ SG_ 1201 RLCR_1_BSDWarn "Blind spot detection system Warning";
CM_ SG_ 1201 RLCR_1_BlkSts "Blockage Status(only for VEONEER)";
CM_ SG_ 1201 RLCR_1_RAEBWarn "RAEB Warning";
CM_ SG_ 1201 RLCR_1_RCTBWarn "RCTA Warning";
CM_ SG_ 1201 RLCR_1_SysSt "System self-test State(only for VEONEER)";
CM_ BO_ 1187 "Source network message is \"Cyclic, 100ms\".
If no messages are received on source network, no messages are sent on the destination network.";
CM_ SG_ 1187 RHM_1_DRLFaildSts "RHM DRL Faild Status";
CM_ SG_ 1187 RHM_1_RHTurnLiFaildSts "RHM Right Hand Turn Light Faild Status";
CM_ SG_ 1187 RHM_1_ParkLiFaildSts "RHM Park Light Faild Status";
CM_ SG_ 1187 RHM_1_LoBeamFaildSts "RHM low Beam Faild Status";
CM_ SG_ 1187 RHM_1_HiBeamFaildSts "RHM High Beam Faild Status";
CM_ SG_ 1208 PPMICounter "????¦Ä??
????????";
CM_ BO_ 1218 "Source network message is \"Cyclic, 100ms\".
If no messages are received on source network, no messages are sent on the destination network.";
CM_ SG_ 1218 LHM_1_DBL_FaultSts "DBL ??????";
CM_ SG_ 1218 LHM_1_DRLFaildSts "LHM  DRL Faild Status";
CM_ SG_ 1218 LHM_1_LHTurnLiFaildSts "LHM Left Hand Turn Light Faild Status";
CM_ SG_ 1218 LHM_1_ParkLiFaildSts "LHM Park Light Faild Status";
CM_ SG_ 1218 LHM_1_LoBeamFaildSts "LHM low Beam Faild Status";
CM_ SG_ 1218 LHM_1_HiBeamFaildSts "LHM High Beam Faild Status";
CM_ BO_ 1175 "Source network message is \"Cyclic, 100ms\".
If no messages are received on source network, no messages are sent on the destination network.";
CM_ BO_ 1506 "Source network message is \"NoMsgSendTypes\".
If no messages are received on source network, no messages are sent on the destination network.";
CM_ SG_ 1506 IHU_ICM_InteractiveDisplayInfo "Refer to ??V1 Platform RRM and ICM Interactive Display Communication Specification??";
CM_ SG_ 906 IDCU_12_RmninfoTrig "HMI reminder information trigger";
CM_ SG_ 906 IDCU_12FCTAWarnRi "FCTA Warning Right";
CM_ SG_ 906 IDCU_12FCTAWarnLe "FCTA Warning Left";
CM_ SG_ 906 IDCU_12CPMod "Chery Pilot Mode
???????!dou!?????
???????????????
??????CP???????????????
??????CP??????????????
???????????????
??????NOC???????????????
??????NOC??????????????
CP??????????????????????!dou!?????????????????
NOC??????????????????????!dou!?????????????????
?????????????!dou!??????????????
???????????
???";
CM_ SG_ 906 IDCU_12Rmninfo "HMI reminder information";
CM_ BO_ 903 "Source network message is \"Cyclic, 50ms\".
If no messages are received on source network, no messages are sent on the destination network.";
CM_ SG_ 903 FCM_FRM_6_VSetDis "setted target speed";
CM_ SG_ 903 FCM_FRM_6_AEBMode "AEB Mode";
CM_ SG_ 903 FCM_FRM_6_FCWMode "FCW Mode";
CM_ SG_ 903 FCM_FRM_6_TakeOverReq "Take Over Request";
CM_ SG_ 903 FCM_FRM_6_FCW_preWarning "FCW_preWarning";
CM_ SG_ 903 FCM_FRM_6_DistanceWarning "Distance Warning";
CM_ SG_ 903 FCM_FRM_6_DrvrCfmSCFDispFb "Driver confirmation SCF interface displays request feedback";
CM_ SG_ 903 FCM_FRM_6_SCF_SpdLimUnit "SCF Speed limit unit";
CM_ SG_ 903 FCM_FRM_6_SCF_SpdLimSts "SCF Speed limit Status";
CM_ SG_ 903 FCM_FRM_6_SCF_PopoverReq "SCF popover request";
CM_ SG_ 903 FCM_FRM_6_TimeGapSetICM "Time Gap Set on the ICM";
CM_ SG_ 903 FCM_FRM_6_ACCMode "ACC Mode";
CM_ SG_ 903 FCM_FRM_6_TextinfoWarn "Text Information warning";
CM_ SG_ 903 FCM_FRM_6_Textinfo_Info "Text Information";
CM_ BO_ 1020 "Source network message is \"Cyclic, 50ms\".
If no messages are received on source network, no messages are sent on the destination network.";
CM_ SG_ 1020 FCM_10_EgoLeftLineHeatgAg "ICM display the Angle between vehicle and lane line";
CM_ SG_ 1020 FCM_10_ELKIntvMod "ELK Intervention Mode";
CM_ SG_ 1020 FCM_10_WarnModSts "Warning Mode status";
CM_ SG_ 1020 FCM_10_SLAONOFFSts "SLA ON/OFF status";
CM_ SG_ 1020 FCM_10_TJAICAExitTextInfoSts "TJAICA Exit Text Information status";
CM_ SG_ 1020 FCM_10_LDPTJAELKTakeoverReq "Take over request to driver";
CM_ SG_ 1020 FCM_10_TJAICAEnaRcmend "Enable TJA/ICA is recommended";
CM_ SG_ 1020 FCM_10_TJAICATextinfo "TJA_ICA_Text information";
CM_ SG_ 1020 FCM_10_TSINoParkWarn "TSI No Park Warning";
CM_ SG_ 1020 FCM_10_ELKSysSts "ELK System Status";
CM_ SG_ 1020 FCM_10_LDWSysSts "LDW System Status";
CM_ SG_ 1020 FCM_10_LDPSysSts "LDP System Status";
CM_ SG_ 1020 FCM_10_TLITrfcLi "TLI Traffic Light";
CM_ SG_ 1020 FCM_10_TSISgnLongStayDisp "TSI Sign Long Stay Display";
CM_ SG_ 1020 FCM_10_TSISgnForb "TSI Sign for forbid";
CM_ SG_ 1020 FCM_10_TSISgnGiWay "TSI Sign for give way";
CM_ SG_ 1020 FCM_10_TLISysSts "TLI system Status";
CM_ SG_ 1020 FCM_10_TSISysSts "TSI System Status";
CM_ BO_ 1018 "Source network message is \"Cyclic, 50ms\".
If no messages are received on source network, no messages are sent on the destination network.";
CM_ SG_ 1018 FCM_FRM_9_RiObjHozDstY "Right Object horizontal distance Y";
CM_ SG_ 1018 FCM_FRM_9_RiObjLgtDstX "Right Object longitudinal distance X";
CM_ SG_ 1018 FCM_FRM_9_RiObjTyp "Right Object Type";
CM_ SG_ 1018 FCM_FRM_9_RiObjID "Right Object ID";
CM_ SG_ 1018 FCM_FRM_9_LeObjHozDstY "Left  Object horizontal distance Y";
CM_ SG_ 1018 FCM_FRM_9_LeObjLgtDstX "Left Object longitudinal distance X";
CM_ SG_ 1018 FCM_FRM_9_LeObjTyp "Left  Object Type";
CM_ SG_ 1018 FCM_FRM_9_LeObjID "Left  Object ID";
CM_ BO_ 1005 "Source network message is \"Cyclic, 50ms\".
If no messages are received on source network, no messages are sent on the destination network.";
CM_ SG_ 1005 FCM_FRM_8_FrntFarObjHozDstY "Front Far Object horizontal distance Y";
CM_ SG_ 1005 FCM_FRM_8_FrntFarObjLgtDstX "Front Far Object longitudinal distance X";
CM_ SG_ 1005 FCM_FRM_8_FrntFarObjTyp "Front Far Object Type";
CM_ SG_ 1005 FCM_FRM_8_FrntFarObjID "Front Far Object ID";
CM_ SG_ 1005 FCM_FRM_8_ACCObjHozDstY "ACC Object horizontal distance Y";
CM_ SG_ 1005 FCM_FRM_8_ACCObjLgtDstX "ACC Object longitudinal distance X";
CM_ SG_ 1005 FCM_FRM_8_ACCObjTyp "ACC Object Type";
CM_ SG_ 1005 FCM_FRM_8_ACCObjID "ACC Object ID";
CM_ BO_ 990 "Source network message is \"Cyclic, 50ms\".
If no messages are received on source network, no messages are sent on the destination network.";
CM_ SG_ 990 FCM_7_NeborRiLineCrvt "Curvature of the Neighbor Right  Line";
CM_ SG_ 990 FCM_7_NeborRiLineHozlDst "Horizontal distance of Neighbor Right Line";
CM_ SG_ 990 FCM_7_NeborRiLineTyp "The type of Neighbor Right Line";
CM_ SG_ 990 FCM_7_NeborRiLineColor "Neighbor Right Line Color";
CM_ SG_ 990 FCM_7_NeborRiLineID "Neighbor Right Line ID";
CM_ SG_ 990 FCM_7_NeborLeLineCrvt "Curvature of the Neighbor Left Line";
CM_ SG_ 990 FCM_7_NeborLeLineHozlDst "Horizontal distance of Neighbor Left Line";
CM_ SG_ 990 FCM_7_NeborLeLineTyp "The type of Neighbor Left Line";
CM_ SG_ 990 FCM_7_NeborLeLineColor "Neighbor Left Line Color";
CM_ SG_ 990 FCM_7_NeborLeLineID "Neighbor Left Line ID";
CM_ BO_ 988 "Source network message is \"Cyclic, 50ms\".
If no messages are received on source network, no messages are sent on the destination network.";
CM_ SG_ 988 FCM_6_EgoRiLineCrvt "Curvature of the Ego Car Right lane line";
CM_ SG_ 988 FCM_6_EgoRiLineHozlDst "Horizontal distance between the Ego car and the Right lane line";
CM_ SG_ 988 FCM_6_EgoRiLineTyp "The type of Ego car Right lane line";
CM_ SG_ 988 FCM_6_EgoRiLineColor "Ego Car Right lane line color";
CM_ SG_ 988 FCM_6_EgoRiLineID "Ego Car Right Line ID";
CM_ SG_ 988 FCM_6_EgoLeLineCrvt "Curvature of the Ego Car left lane line";
CM_ SG_ 988 FCM_6_EgoLeLineHozlDst "Horizontal distance between the Ego car and the left lane line";
CM_ SG_ 988 FCM_6_EgoLeLineTyp "The type of Ego car left lane line";
CM_ SG_ 988 FCM_6_EgoLeLineColor "Ego Car left lane line color";
CM_ SG_ 988 FCM_6_EgoLeLineID "Ego Car Left Line ID";
CM_ BO_ 775 "Source network message is \"Cyclic, 20ms\".
If no messages are received on source network, no messages are sent on the destination network.";
CM_ SG_ 775 FCM_2_SLASpdlimitUnits "SLA Speed limit Units";
CM_ SG_ 775 FCM_2_SpdLimtyp "speed limit type";
CM_ SG_ 775 FCM_2_SCFSpdlimWarn "SCF Speed limit Warning";
CM_ SG_ 775 LDW_ELK_TJA_LDPRightVisuali "LDW_ELK_TJA_LDP Right Visualization";
CM_ SG_ 775 LDW_ELK_TJA_LDPLeftVisuali "LDW_ELK_TJA_LDP Left Visualization";
CM_ BO_ 896 "Source network message is \"Cyclic, 100ms\".
If no messages are received on source network, no messages are sent on the destination network.";
CM_ SG_ 896 EPS_EOTLearning_Sts "Indicates the status of EPS EOT(end of travel) learning, displayed on the DMC(ICM)";
CM_ SG_ 896 EPS_1_MessageCounter "Rolling message counter(the maximum value of Alive counter is 15)
Note: Details Please refer to specification??Standard Specification for CAN Data Link Layer_v1.1??section 2.3.1";
CM_ BO_ 1270 "Source network message is \"Cyclic, 100ms\".
If no messages are received on source network, no messages are sent on the destination network.";
CM_ SG_ 1270 Yellowwarning "??P??";
CM_ SG_ 1270 Redwarning "??P??";
CM_ SG_ 1270 RWUActive "???????£º??????CDPActive=1_active??RWUActive=1_active£¬???????????";
CM_ SG_ 1270 EPBStatus "????????????
???????§ß???
?????????????????
?????????§ß??????
¦Ä???!mao!??????????¦Ä???
ErrorApplied!mao!
??EPBError????????????§ß???,????????EPB(apply)???????101?????????????
??EPBError????????§ß???,??101?????????????";
CM_ SG_ 1270 EPBWarningMessage "??????????????????????¡¢????????¡¢??????
001!mao!????????????¦Ä?????????
010!mao!????????¦Ä???????????
011!mao!????????????";
CM_ BO_ 640 "Source network message is \"Cyclic, 100ms\".
If no messages are received on source network, no messages are sent on the destination network.";
CM_ SG_ 640 EngineSts "PHEV??£¬???????????????????";
CM_ SG_ 640 TargetGearPosition "??????MT?£¬?????????";
CM_ SG_ 640 SSMStatus "??????????????????
0-Reset Start/Stop not active(any engine condition possible)
??????
1-StandbyS/S active, engine off(waiting for initial keybutton start)
?????!dou!?????????ÂC??
2- StoppedS/S active, engine standstill
3- Starter RestartSS/ active starter engine is turning 
??????????????????
4 - Engine RestartS/S active, engine runs up
?????????????????????????!dou!??????????????????!dou!??????§Ö?0!dou!???????????!dou!??????????????????????????!dou!????????????!dou!???????????????????
5 - OperationS/S active, engine is running
6 - Auto StoppingS/S active, engine is turning but no fuel injection anymore
????ISS????!dou!??????000";
CM_ SG_ 640 FuelRollingCounter "????????????";
CM_ SG_ 640 GPFWarning "This signal indicates the status of GPF warning which need ICM to  inform driver. 
0x1: Green light, may display \"GPF is full. Need  highspeed road drive to clean GPF??
0x2: Yellow light, may display\"GPF is overlimited. Need to contact 4s to check and repair GPF\"";
CM_ BO_ 1232 "Source network message is \"Cyclic, 100ms\".
If no messages are received on source network, no messages are sent on the destination network.";
CM_ SG_ 1232 Energy_Flow_Sts "00:????????????;
01:????????????´‘
10:??????????????´‘
11!mao!?????????";
CM_ SG_ 1232 Battery_Sts "00:????????????????
01:???????
10:?????";
CM_ SG_ 1232 Battery_Temp_Sts "00:48V???????????
01:48V???????????????????????65!du!)
10:???¦Ì??¦Ì?48V???????¦Ä???";
CM_ SG_ 1146 AllWarningInfo "EGS??????????
T1C???!dou!EGS??????0x0!dun!0x1!dun!0x4!dou!??????";
CM_ BO_ 1158 "Source network message is \"Cyclic, 100ms\".
If no messages are received on source network, no messages are sent on the destination network.";
CM_ SG_ 1158 AWDoutserviceDispRq "0x0: ???????????
0x1: ?????????????!dou!???????
0x2: ?????????¨´???!dou!?????????
0x3: ???¦Ë";
CM_ BO_ 1095 "Source network message is \"Cyclic, 100ms\".
If no messages are received on source network, no messages are sent on the destination network.";
CM_ SG_ 1095 AFS_FaultSts "AFS ??????";
CM_ BO_ 704 "Source network message is \"Cyclic, 100ms\".
If no messages are received on source network, no messages are sent on the destination network.";
CM_ SG_ 704 ABS_ESP_Checksum "((Byte0+Byte1+ Byte2+Byte3+Byte4+Byte5) AND 0xFF) XOR 0xFF
Note: Details Please refer to specification??Standard Specification for CAN Data Link Layer_v1.1??section 2.3.3";
CM_ SG_ 704 CDPFailSts "???????????£¬CDP?§¹";
CM_ SG_ 704 AVHSts "????Auto Hold??AVH??????????????
Off!mao!AVH??????
Standy!mao!AVH?????!dou!??????¦Ä????
Active!mao!AVH???????";
CM_ SG_ 704 HDCFailSts "After IGN OFF, this signal should be set to 0 for avoiding ICM HDC warning.";
CM_ SG_ 704 ABS_ESP_MessageCounter "Rolling message counter(the maximum value of Alive counter is 15)
Note: Details Please refer to specification??Standard Specification for CAN Data Link Layer_v1.1??section 2.3.1";
CM_ SG_ 704 CDPActive "???????£º??????CDPActive=1_active??RWUActive=1_active£¬???????????";
CM_ SG_ 704 ESPSwitchStatus "??1?? means VDC and Engine Traction Control System (PTC) Function and Brake Traction Control System (BTC) Function disabled and Ignit ESP lamp.
0x0!mao!ESP???????
0x1!mao!ESP??????";
CM_ SG_ 704 HHCFailSts "After IGN OFF, this signal should be set to 0 for avoiding ICM ESP warning.";
CM_ SG_ 704 VDCFailSts "After IGN OFF, this signal should be set to 0 for avoiding ICM ESP warning.";
CM_ SG_ 704 TCSFailSts "After IGN OFF, this signal should be set to 0 for avoiding ICM ESP warning.";
CM_ SG_ 704 AVHWarningMessage "????AVH???????Autohold?????£¬¦Ä?????????/?????¦Ä????£¬????????????
??????????????????AVH";
CM_ BO_ 745 "Source network message is \"Cyclic, 10ms\".
If no messages are received on source network, no messages are sent on the destination network.";
CM_ SG_ 745 AEBdecActive "AEB  braking function";
CM_ BO_ 800 "Source network message is \"Cyclic, 500ms\".
If no messages are received on source network, no messages are sent on the destination network.";
CM_ SG_ 800 ABM_1_MessageCounter "Rolling message counter(the maximum value of Alive counter is 15)
Note: Details Please refer to specification??Standard Specification for CAN Data Link Layer_v1.1??section 2.3.1";
CM_ SG_ 800 SecRowRBeltWarning "???¦Ë???£º
???????????????
0x0:¦Ä????/?????????
0x1:????¦Ä?
?????¦Ë???!mao!
0x0:??????????
0x1;?????¦Ä???";
CM_ SG_ 800 SecRowMBeltWarning "???¦Ë???£º
??????§µ????????
0x0:¦Ä????/?????????
0x1:????¦Ä?
?????¦Ë???!mao!
0x0:??????????
0x1;?????¦Ä???";
CM_ SG_ 800 SecRowLBeltWarning "???¦Ë???£º
??????????????
0x0:¦Ä????/?????????
0x1:????¦Ä?
?????¦Ë???!mao!
0x0:??????????
0x1;?????¦Ä???";
CM_ SG_ 800 ThdRowRBeltWarning "???¦Ë???£º
???????????????
0x0:¦Ä????/?????????
0x1:????¦Ä?
?????¦Ë???!mao!
0x0:??????????
0x1;?????¦Ä???";
CM_ SG_ 800 ThdRowLBeltWarning "???¦Ë???£º
??????????????
0x0:¦Ä????/?????????
0x1:????¦Ä?
?????¦Ë???!mao!
0x0:??????????
0x1;?????¦Ä???";
CM_ SG_ 800 PsngrSeatBeltWarning "?????§Ú???????????????ABM????????£¬??????§Ú?????????ABM??????Startup???
???????SBR?§Ø?";
CM_ SG_ 1556 WakeupSource_ICM "Wakeup Source
Note: Details Please refer to specification??BD CAN ICM Network Management Specification ??section10.2 and ??BD CAN DMC Network Management Specification ??section10.2";
CM_ SG_ 1556 ECUSPEC_AWAKE_ICM "ECU keeps the network awake for ECU-define reasons for which communication is needed";
CM_ SG_ 1556 DIAGNOSTIC_AWAKE_ICM "ECU needs communication for diagnostic purpose and keeps network awake.";
CM_ SG_ 1556 IGNITION_AWAKE_ICM "ECU can?t release communication because ignition (KL15) is turn on, or KLR is turned on";
CM_ SG_ 1556 NETWORK_AWAKE_ICM "ECU keeps the network awake due to the CAN message received from the network";
CM_ SG_ 1556 ECUSPEC_WAKEUP_ICM "ECU was in ??power off??, ??Bus Sleep??, ??Pre-pare Bus Sleep?? or ??Ready Sleep?? mode or ??awake?? and re-started by ECU specific reason (e.g. pressed Button, timer, etc.)";
CM_ SG_ 1556 NETWORK_WAKEUP_ICM "ECU was in ??Power off??, ??Bus Sleep??, ??Pre-pare Bus Sleep?? or ??Ready Sleep?? Mode and then re-started by a network communication.";
CM_ SG_ 1556 RESET_WAKEUP_ICM "If ECU was already awake, in ??Prepare Bus Sleep?? or ??Ready Sleep?? mode and re-started by an internal or an external reset.";
CM_ SG_ 1556 IGNITION_WAKEUP_ICM "ECU was ??power off?? or ??Bus sleep?? mode and started by ignition switch";
CM_ SG_ 1556 RMR_ICM "If set to 1 to force the network management of all other nodes on the bus into the re-peat message state.";
CM_ SG_ 1556 srcNodeID_ICM "The srcNodeID of ICM is 0x20";
CM_ SG_ 1152 RemoteStartSts "????????";
CM_ SG_ 1152 SmartSystemWarning1_1 "BCM itself also should receive this message besides gateway function for dealing";
CM_ SG_ 1152 SmartSystemWarning1_3 "BCM itself also should receive this message besides gateway function for dealing.";
CM_ SG_ 1152 SmartSystemWarning3_2 "Detect whether shift is in P/N when starting";
CM_ SG_ 1152 SmartSystemWarning4_2 "Detect whether pressing brake or clutch to start engine";
CM_ SG_ 1219 PAS_1_DriverDoorSIllSts "Robe the clip";
CM_ SG_ 1025 ESCLNotLocked "The status defines if a message is set or reset";
CM_ SG_ 1025 ESCLUnlockJamming "The value (0-254) defines the warning message ID (see warning message cataloge) with this value the global ID for the warning which should be outputted is
defined";
CM_ SG_ 1025 ESCLCriticalFailure "Defines that the message is a warning message only if 32h is received a warning message should be generated
??????0x32?????????§¹?????????";
CM_ BO_ 533 "??????¦²???3?¦Å????? ???????Not Active.";
CM_ SG_ 533 SetICMAlarm "ICM Alarm??ADAS????????";
CM_ SG_ 1329 SIA_IntervalDistance "current interval distance
?????????????";
CM_ SG_ 1329 SIA_LastDay "Represents the last SIA day. Invalid =0
??¦Á??????????";
CM_ SG_ 1329 SIA_LastYear "Represents the  last SIA year. Invalid = 2101 to 2127
??¦Á??????????";
CM_ SG_ 1329 SIA_LastMonth "Represents the  last SIA month. 0, 13 to 15 = Invalid
??¦Á??????????";
CM_ SG_ 1329 SIA_IntervalTime "current interval time
?????????????";
CM_ SG_ 1329 SIA_LastODO "last SIA ODO value
??¦Á???????????";
CM_ SG_ 1066 TotalOdometer_km_OBD "GB18285-2018????OBD????????????????????????";
CM_ SG_ 1066 TotODOMtrBkpEna "??????????";
CM_ SG_ 1066 DrivermodeReq "?????????";
CM_ SG_ 647 ICM_5_Checksum "((Byte0+Byte1+Byte2+Byte3+Byte4+Byte5+Byte6) AND 0xFF) XOR 0xFF
Note: Details Please refer to specification??Standard Specification for CAN Data Link Layer_v1.1??section 2.3.3";
CM_ SG_ 647 ICM_5_MessageCounter "Rolling message counter(the maximum value of Alive counter is 15)
Note: Details Please refer to specification??Standard Specification for CAN Data Link Layer_v1.1??section 2.3.1";
CM_ SG_ 647 ICM_DVDAudibleAlarmStyle "???????????£º
0x0:?????
0x1:???¦Â???
0x2!mao!???????
12.3????????????!dou!??????????DVD???????";
CM_ SG_ 647 ICM_DVDAudibleAlarm "12.3????????????£¬??????????DVD???????
0x0:?????";
CM_ SG_ 647 BrakeFluidWarning "??????????????";
CM_ SG_ 647 ICM_5_AlrmVolCtrl "Alarm volume control????????????
??????????????????????!dou!???????Up????Down?!dou!???????????????????????!dou!??????????????????0x0 Not active??
0x0 ??????
0x1 ???????????
0x2 ???????????";
CM_ SG_ 647 ICM_5_BackLiBriAdjmt "Backlight brightness adjustment ???????????
?????????????????????!dou!???????Up????Down?!dou!???????????????????????!dou!??????????????????0x0 Not active??
0x0 ??????
0x1 ???????????
0x2 ???????????";
CM_ SG_ 647 AverageFuelConsumption50 "??????";
CM_ SG_ 647 ICM_5_FuelLevel "???£º???????EMS??";
CM_ SG_ 647 FuelValidData "???£º???????EMS??";
CM_ SG_ 647 FuelOutOfRange "???£º???????EMS??";
CM_ SG_ 647 FuelShortPower "???£º???????EMS??";
CM_ SG_ 647 FuelShortGround "???£º???????EMS??";
CM_ SG_ 647 HandBrakeSystemSts "???????
????????????
???????§ß???
?????????????????
?????????§ß??????
¦Ä???!mao!??????????¦Ä???
ErrorApplied!mao!
??EPBError????????????§ß???,????????EPB(apply)???????101?????????????
??EPBError????????§ß???,??101?????????????
??§Ö??????000??001????????EPB?????????§³?";
CM_ SG_ 1107 FatigureDrivingWarning "?????????";
CM_ SG_ 1107 CurrentTimeYear "??";
CM_ SG_ 1107 CurrentTimeMonth "??";
CM_ SG_ 1107 CurrentTimeDay "??";
CM_ SG_ 1107 ResidualOdometer "???????";
CM_ SG_ 1107 CurrentTimeSecond "ICM??????????????
DVD??
????????!dou!??0 (Not active)??
????????0 (Startup)?????15????????!dou!???????????(????????????????????)??";
CM_ SG_ 1107 ICM_BrightnessLevel "ICMBrightnessLevel????ICMBackLightLevel??????????????????????£¬??????";
CM_ SG_ 1107 MaintainWarning "??????????";
CM_ SG_ 1107 LowFuleWarning "????????????????????DVD?????£¬DVD??????????????¦Ë????????£¬????????????????§Ö?????
??????¦Ë???????§¹!dou!??????0??";
CM_ SG_ 1107 FatigureDrivingTime "????????£¬???????????????¨¢?
???????????????!dou!????1 hours??????????§¹???????!dou!????????????????§¹?
??¦Ä???????!dou!?????????§¹???
????????!dou!??1 hours??
???RRM???¨´????!dou!???????????????????????????ICM????????";
CM_ SG_ 1107 CurrentTimeMinute "ICM??????????????
DVD??????????y??
????????!dou!??0 (Not active)??????????0 (Startup)?????15????????!dou!???????????(????????????????????)??";
CM_ SG_ 1107 CurrentTimeHour "ICM???????????????
DVD??????????y??
????????!dou!??0 (Not active)??????????0 (Startup)?????15????????!dou!???????????(????????????????????)??";
CM_ SG_ 1106 FrontSeatBeltAlarmLight "Front Seat Belt Alarm Light
???????????????
0x0!mao!??????????????????
0x1!mao!?????????????????";
CM_ SG_ 1106 QDashACCFail "Error in the ACC message detected by the HMI, like timeout or alivecounter error.
The error should distinguish reversible and irreversible errors.
???????????????????????????????????????????????????§Ø???????????????????????????????????????????????????????????!dou!????????????????;";
CM_ SG_ 1106 DISFail "Error in the display or display control unit.
TFT?????§Ú????PIN??!dou!?????????????PIN???????????????????????????!dou!??????????????????????????????PIN???????§Ø????;";
CM_ SG_ 1106 ICM_2_LoWshLqdWarn "Washing liquid level alarm signal£¬If the washing liquid level sensor fails, the signal is 0
????¦Ë???????!dou!??????¦Ë???????§¹!dou!??????0";
CM_ SG_ 1106 TemperatureUnit_ICM "????¦Ë?§Ý?
???????????Startup????????!deg!";
CM_ SG_ 1106 AirBagLampFailSts "When the value set
to??00b??,it means that the
ICM airbaglamp has no fail
whether ICM lamp is ON
or OFF.
When the value is 01, means the LED lamp is fail because it??s always off.
When the value is 10, means the LED lamp is fail because it??s always on.";
CM_ SG_ 1106 AverageFuelConsumption "??????";
CM_ SG_ 1072 FuelLevel "Unfilter signal";
CM_ SG_ 1072 ICM_1MessageCounter "Rolling message counter(the maximum value of Alive counter is 15)
Note: Details Please refer to specification??Standard Specification for CAN Data Link Layer_v1.1??section 2.3.1";
CM_ SG_ 1072 FuelLevelFailSts "????¡¤??¡¤£¬??¡¤£¬????20S??????????Fail Present";
CM_ SG_ 1072 ECOModeSWSts "?????1????\"ECO\"£¬0????\"Sport\"
MT????ECO????";
CM_ SG_ 1072 BatteryVoltage "????????????????";
CM_ SG_ 1072 DisplayVehicleSpeed "???????????£¬???????????";
CM_ SG_ 1072 ICM_1_HandBrakeSystemSts "???????
????????????
???????§ß???
?????????????????
?????????§ß??????
¦Ä???!mao!??????????¦Ä???
ErrorApplied!mao!
??EPBError????????????§ß???,????????EPB(apply)???????101?????????????
??EPBError????????§ß???,??101?????????????
??§Ö??????000??001????????EPB?????????§³?";
CM_ SG_ 1275 DCM_1_PwrDoorErr "Power Door Error";
CM_ SG_ 1275 DCM_1_RHRStallSts "?????????????";
CM_ SG_ 1275 DCM_1_LHRStallSts "?????????????";
CM_ SG_ 1275 DCM_1_PassStallSts "??????????????";
CM_ SG_ 1275 DCM_1_DrvrStallSts "???????????????";
CM_ SG_ 1224 BCM_RRPLMfailsts "RRPLM Faild Status";
CM_ SG_ 1224 BCM_RRFLMfailsts "RRFLM Faild Status";
CM_ SG_ 1224 BCM_RLPLMfailsts "RLPLM Faild Status";
CM_ SG_ 1224 BCM_RLFLMfailsts "RLFLM Faild Status";
CM_ SG_ 1224 BCM_RHMfailsts "RHM Faild Status";
CM_ SG_ 1224 BCM_LHMfailsts "LHM Faild Status";
CM_ SG_ 1224 ReFogLiFaildSts "Rear frog  light  Faild Status";
CM_ SG_ 1224 ReversinglampFaultSts "Reversing lamp Faild Status";
CM_ SG_ 1224 BrakelampFaultSts "Brake lamp Faild Status";
CM_ SG_ 1224 FrntFogFaildSts "Front frog  light  Faild Status";
CM_ SG_ 1224 DRLFaildSts "Daytime running light Faild Status";
CM_ SG_ 1224 BDM_21_RHTurnlightSts "Right Hand Turn light Status";
CM_ SG_ 1224 BDM_21_LHTurnlightSts "Left Hand Turn light Status";
CM_ SG_ 1224 ParkLiFaildSts "Park Light Faild Status";
CM_ SG_ 1224 LoBeamFaildSts "Low Beam Faild Status";
CM_ SG_ 1224 HiBeamFaildSts "High Beam Faild Status";
CM_ SG_ 1307 TireTemperature "?????????£¬??TyrePosition?????¨¢?";
CM_ SG_ 1307 TirePosition "???????¦Ë???£¬??TyreTemperature?????????";
CM_ SG_ 1307 TirePositionWarning_RHRTire "???¦Ë?????????£¬????????¡¢???¡¢???¡¢?????";
CM_ SG_ 1307 TirePositionWarning_LHRTire "???¦Ë?????????£¬????????¡¢???¡¢???¡¢?????";
CM_ SG_ 1307 TirePositionWarning_RHFTire "?????¦Ë?????????£¬????????¡¢???¡¢???¡¢?????";
CM_ SG_ 1307 TirePositionWarning_LHFTire "?????¦Ë?????????£¬????????¡¢???¡¢???¡¢?????";
CM_ SG_ 1307 TirePressureWarningLampSts "??????????£¬?????¡¢?????????????¡¢?????????????????";
CM_ SG_ 914 RearFoglightFaultSts "0x0 shows RearFoglight  is in normal working status ,
0x1 shows RearFoglight is in fault state";
CM_ SG_ 914 WiperSensitivitySWSts "????RSM£¬BCM??000
¦Ä?????????????????000??";
CM_ SG_ 914 RainSensorFailSts "ICM???????
????RSM!dou!BCM??0";
CM_ SG_ 914 ReversinglampFaultSts "0x0 shows Reversinglamp  is in normal working status ,
0x1 shows Reversinglamp is in  fault state";
CM_ SG_ 914 BrakelampFaultSts "0x0 shows Brakelamp  is in normal working status ,
0x1 shows Brakelamp is in a fault state,";
CM_ SG_ 914 FollowMeTimeSts "Not active=0000£¬??????¦Ä????????£¬????????????????????";
CM_ SG_ 914 LightDetected "0X0: ??
0x1: ??
?????LIN??????!mao!
????LIN???S_AUTO_LAMP??????????????????CAN??????????
?????LIN??????
BCM?????????????????????CAN??????????
?????????????§Ø????????????????0";
CM_ SG_ 914 BCM_4_ArmingSts "???????/?????????????
??????0x1,??????0x2
??????/??????? 0x1??0x2??????????0x0";
CM_ SG_ 1059 LDWWorkingSts "????????LDW?????????
00:LDW??????,?????????
01:LDW???????,??????
10:LDW???????,??????";
CM_ SG_ 1059 LDWWarningSts "LDW??????
01:?????????
10:?????????";
CM_ SG_ 1059 LDWLaneDetectionSts "LDW?????????";
CM_ SG_ 1088 RadarWorkSts "???????????
1!dun!Active!mao!????PAS???????????!dou!???????????!dou!?????1??
2!dun!Not Active!mao!???????????PAS??????!dou!??0(Not Active)??";
CM_ SG_ 1088 RadarDetectSts "????????
????01!dou!RRM????????????????????
????10!dou!RRM??????????????????";
CM_ SG_ 1088 AudibleBeepRate "???????
1!dun!??????????????????Startup
2!dun!??????????!mao!??????????
3!dun!?????????RadarWorkSts??????";
CM_ SG_ 1088 LHMFRadarSensorDistance "??????????
??????!mao!????Sensor err
???????????????!mao!????0x1E

???????!mao!????=(D)*5+25
???????!mao!????0x1E
???????(??4 ??)!mao!????0x1E
0x1C~0x1D!mao!??§¹????";
CM_ SG_ 1088 RHMFRadarSensorDistance "??????????
??????!mao!????Sensor err
???????????????!mao!????0x1E

???????!mao!????=(D)*5+25
???????!mao!????0x1E
???????(??4 ??)!mao!????0x1E
0x1C~0x1D!mao!??§¹????";
CM_ SG_ 1088 RHFRadarSensorDistance "????????
??????!mao!????Sensor err
???????????????!mao!????0x1E

???????!mao!????=(D)*5+25
???????!mao!????0x1E
???????(??4 ??)!mao!????0x1E
0x1C~0x1D!mao!??§¹????";
CM_ SG_ 1088 LHFRadarSensorDistance "????????
??????!mao!????Sensor err
???????????????!mao!????0x1E

???????!mao!????=(D)*5+25
???????!mao!????0x1E
???????(??4 ??)!mao!????0x1E
0x1C~0x1D!mao!??§¹????";
CM_ SG_ 1088 RHRRadarSensorDistance "????????
??????!mao!????Sensor err
???????????????!mao!????0x3E

???????!mao!????=(D)*5+25
???????!mao!????0x3E
0x20~0x3D!mao!??§¹????\"";
CM_ SG_ 1088 LHMRRadarSensorDistance "???§Ü??????
??????!mao!????Sensor err
???????????????!mao!????0x3E

???????!mao!????=(D)*5+25
???????!mao!????0x3E 
0x20~0x3D!mao!??§¹????";
CM_ SG_ 1088 RHMRRadarSensorDistance "???§Ü??????
??????!mao!????Sensor err
???????????????!mao!????0x3E

???????!mao!????=(D)*5+25
???????!mao!????0x3E 
0x20~0x3D!mao!??§¹????";
CM_ SG_ 1088 LHRRadarSensorDistance "????????
??????!mao!????Sensor err
???????????????!mao!????0x3E

???????!mao!????=(D)*5+25
???????!mao!????0x3E
0x20~0x3D!mao!??§¹????";
BA_DEF_  "BusType" STRING ;
BA_DEF_  "NmAsrCanMsgCycleTime" INT 1000 1000;
BA_DEF_  "NmAsrRepeatMessageTime" INT 3000 3000;
BA_DEF_  "NmAsrWaitBusSleepTime" INT 1500 1500;
BA_DEF_  "NmAsrTimeoutTime" INT 2500 2500;
BA_DEF_  "NmAsrBaseAddress" HEX 0 2047;
BA_DEF_  "NmAsrMessageCount" INT 128 128;
BA_DEF_  "NmType" STRING ;
BA_DEF_  "ILTxTimeout" INT 0 65535;
BA_DEF_  "Manufacturer" STRING ;
BA_DEF_ SG_  "GenSigTimeoutValue" INT 0 2147483647;
BA_DEF_ SG_  "GenSigStartValue" INT 0 2147483647;
BA_DEF_ SG_  "GenSigInactiveValue" INT 0 2147483647;
BA_DEF_ BO_  "TpTxIndex" INT 0 255;
BA_DEF_ BO_  "DiagUudtResponse" ENUM  "False","True";
BA_DEF_ BO_  "DiagResponse" ENUM  "No","Yes";
BA_DEF_ BO_  "DiagRequest" ENUM  "No","Yes";
BA_DEF_ BO_  "DiagState" ENUM  "No","Yes";
BA_DEF_ BO_  "NmAsrMessage" ENUM  "No","Yes";
BA_DEF_ BO_  "GenMsgFastOnStart" INT 0 65535;
BA_DEF_ BO_  "GenMsgCycleTimeFast" INT 0 65535;
BA_DEF_ BO_  "GenMsgNrOfRepetition" INT 0 65535;
BA_DEF_ BO_  "GenMsgStartDelayTime" INT 0 65535;
BA_DEF_ BO_  "GenMsgCycleTime" INT 0 65535;
BA_DEF_ BO_  "GenMsgDelayTime" INT 0 65535;
BA_DEF_ SG_  "GenSigSendType" ENUM  "Cyclic","OnWrite","OnWriteWithRepetition","OnChange","OnChangeWithRepetition","IfActive","IfActiveWithRepetition","NoSigSendType","OnChangeAndIfActive","OnChangeAndIfActiveWithRepetition";
BA_DEF_ BO_  "GenMsgSendType" ENUM  "Cyclic","NotUsed","NotUsed","NotUsed","NotUsed","NotUsed","NotUsed","IfActive","NoMsgSendType";
BA_DEF_ BO_  "GenMsgILSupport" ENUM  "No","Yes";
BA_DEF_ BU_  "NmStationAddress" HEX 0 255;
BA_DEF_ BU_  "NmAsrCanMsgReducedTime" INT 500 818;
BA_DEF_ BU_  "NmAsrCanMsgCycleOffset" INT 0 635;
BA_DEF_ BU_  "NmAsrNodeIdentifier" HEX 0 255;
BA_DEF_ BU_  "NmAsrNode" ENUM  "No","Yes";
BA_DEF_ BU_  "ILUsed" ENUM  "No","Yes";
BA_DEF_REL_ BU_SG_REL_  "GenSigTimeoutTime" INT 0 65535;
BA_DEF_DEF_  "BusType" "";
BA_DEF_DEF_  "NmAsrCanMsgCycleTime" 1000;
BA_DEF_DEF_  "NmAsrRepeatMessageTime" 3000;
BA_DEF_DEF_  "NmAsrWaitBusSleepTime" 1500;
BA_DEF_DEF_  "NmAsrTimeoutTime" 2500;
BA_DEF_DEF_  "NmAsrBaseAddress" 1536;
BA_DEF_DEF_  "NmAsrMessageCount" 128;
BA_DEF_DEF_  "NmType" "NmAsr";
BA_DEF_DEF_  "ILTxTimeout" 0;
BA_DEF_DEF_  "Manufacturer" "Vector";
BA_DEF_DEF_  "GenSigTimeoutValue" 0;
BA_DEF_DEF_  "GenSigStartValue" 0;
BA_DEF_DEF_  "GenSigInactiveValue" 0;
BA_DEF_DEF_  "TpTxIndex" 0;
BA_DEF_DEF_  "DiagUudtResponse" "False";
BA_DEF_DEF_  "DiagResponse" "No";
BA_DEF_DEF_  "DiagRequest" "No";
BA_DEF_DEF_  "DiagState" "No";
BA_DEF_DEF_  "NmAsrMessage" "No";
BA_DEF_DEF_  "GenMsgFastOnStart" 0;
BA_DEF_DEF_  "GenMsgCycleTimeFast" 0;
BA_DEF_DEF_  "GenMsgNrOfRepetition" 3;
BA_DEF_DEF_  "GenMsgStartDelayTime" 0;
BA_DEF_DEF_  "GenMsgCycleTime" 0;
BA_DEF_DEF_  "GenMsgDelayTime" 0;
BA_DEF_DEF_  "GenSigSendType" "NoSigSendType";
BA_DEF_DEF_  "GenMsgSendType" "NoMsgSendType";
BA_DEF_DEF_  "GenMsgILSupport" "No";
BA_DEF_DEF_  "NmStationAddress" 255;
BA_DEF_DEF_  "NmAsrCanMsgReducedTime" 575;
BA_DEF_DEF_  "NmAsrCanMsgCycleOffset" 0;
BA_DEF_DEF_  "NmAsrNodeIdentifier" 255;
BA_DEF_DEF_  "NmAsrNode" "No";
BA_DEF_DEF_  "ILUsed" "No";
BA_DEF_DEF_REL_ "GenSigTimeoutTime" 0;
BA_ "BusType" "CAN";
BA_ "NmStationAddress" BU_ IHU 20;
BA_ "NmAsrNodeIdentifier" BU_ IHU 20;
BA_ "NmAsrNode" BU_ IHU 1;
BA_ "ILUsed" BU_ IHU 1;
BA_ "DiagState" BO_ 2015 1;
BA_ "GenMsgNrOfRepetition" BO_ 2015 0;
BA_ "GenMsgNrOfRepetition" BO_ 1536 0;
BA_ "GenMsgCycleTime" BO_ 1536 1000;
BA_ "NmAsrMessage" BO_ 1536 1;
BA_ "GenMsgSendType" BO_ 1536 0;
BA_ "DiagRequest" BO_ 1928 1;
BA_ "GenMsgNrOfRepetition" BO_ 1928 0;
BA_ "GenMsgNrOfRepetition" BO_ 1764 0;
BA_ "GenMsgILSupport" BO_ 1443 1;
BA_ "GenMsgNrOfRepetition" BO_ 1443 0;
BA_ "GenMsgDelayTime" BO_ 1443 5;
BA_ "GenMsgILSupport" BO_ 769 1;
BA_ "GenMsgSendType" BO_ 769 0;
BA_ "GenMsgNrOfRepetition" BO_ 769 0;
BA_ "GenMsgCycleTime" BO_ 769 100;
BA_ "GenMsgILSupport" BO_ 1203 1;
BA_ "GenMsgSendType" BO_ 1203 0;
BA_ "GenMsgNrOfRepetition" BO_ 1203 0;
BA_ "GenMsgCycleTime" BO_ 1203 100;
BA_ "GenMsgILSupport" BO_ 1201 1;
BA_ "GenMsgSendType" BO_ 1201 0;
BA_ "GenMsgNrOfRepetition" BO_ 1201 0;
BA_ "GenMsgCycleTime" BO_ 1201 100;
BA_ "GenMsgILSupport" BO_ 1187 1;
BA_ "GenMsgSendType" BO_ 1187 0;
BA_ "GenMsgNrOfRepetition" BO_ 1187 0;
BA_ "GenMsgCycleTime" BO_ 1187 100;
BA_ "GenMsgILSupport" BO_ 1208 1;
BA_ "GenMsgSendType" BO_ 1208 0;
BA_ "GenMsgNrOfRepetition" BO_ 1208 0;
BA_ "GenMsgCycleTime" BO_ 1208 100;
BA_ "GenMsgILSupport" BO_ 1218 1;
BA_ "GenMsgSendType" BO_ 1218 0;
BA_ "GenMsgNrOfRepetition" BO_ 1218 0;
BA_ "GenMsgCycleTime" BO_ 1218 100;
BA_ "GenMsgILSupport" BO_ 1175 1;
BA_ "GenMsgSendType" BO_ 1175 0;
BA_ "GenMsgNrOfRepetition" BO_ 1175 0;
BA_ "GenMsgCycleTime" BO_ 1175 100;
BA_ "GenMsgILSupport" BO_ 1506 1;
BA_ "GenMsgNrOfRepetition" BO_ 1506 0;
BA_ "GenMsgILSupport" BO_ 906 1;
BA_ "GenMsgSendType" BO_ 906 0;
BA_ "GenMsgNrOfRepetition" BO_ 906 0;
BA_ "GenMsgCycleTime" BO_ 906 100;
BA_ "GenMsgILSupport" BO_ 903 1;
BA_ "GenMsgSendType" BO_ 903 0;
BA_ "GenMsgNrOfRepetition" BO_ 903 0;
BA_ "GenMsgCycleTime" BO_ 903 50;
BA_ "GenMsgILSupport" BO_ 1020 1;
BA_ "GenMsgSendType" BO_ 1020 0;
BA_ "GenMsgNrOfRepetition" BO_ 1020 0;
BA_ "GenMsgCycleTime" BO_ 1020 50;
BA_ "GenMsgILSupport" BO_ 1018 1;
BA_ "GenMsgSendType" BO_ 1018 0;
BA_ "GenMsgNrOfRepetition" BO_ 1018 0;
BA_ "GenMsgCycleTime" BO_ 1018 50;
BA_ "GenMsgILSupport" BO_ 1005 1;
BA_ "GenMsgSendType" BO_ 1005 0;
BA_ "GenMsgNrOfRepetition" BO_ 1005 0;
BA_ "GenMsgCycleTime" BO_ 1005 50;
BA_ "GenMsgILSupport" BO_ 990 1;
BA_ "GenMsgSendType" BO_ 990 0;
BA_ "GenMsgNrOfRepetition" BO_ 990 0;
BA_ "GenMsgCycleTime" BO_ 990 50;
BA_ "GenMsgILSupport" BO_ 988 1;
BA_ "GenMsgSendType" BO_ 988 0;
BA_ "GenMsgNrOfRepetition" BO_ 988 0;
BA_ "GenMsgCycleTime" BO_ 988 50;
BA_ "GenMsgILSupport" BO_ 775 1;
BA_ "GenMsgSendType" BO_ 775 0;
BA_ "GenMsgNrOfRepetition" BO_ 775 0;
BA_ "GenMsgCycleTime" BO_ 775 50;
BA_ "GenMsgILSupport" BO_ 896 1;
BA_ "GenMsgSendType" BO_ 896 0;
BA_ "GenMsgNrOfRepetition" BO_ 896 0;
BA_ "GenMsgCycleTime" BO_ 896 100;
BA_ "GenMsgILSupport" BO_ 1270 1;
BA_ "GenMsgSendType" BO_ 1270 0;
BA_ "GenMsgNrOfRepetition" BO_ 1270 0;
BA_ "GenMsgCycleTime" BO_ 1270 100;
BA_ "GenMsgILSupport" BO_ 640 1;
BA_ "GenMsgSendType" BO_ 640 0;
BA_ "GenMsgNrOfRepetition" BO_ 640 0;
BA_ "GenMsgCycleTime" BO_ 640 100;
BA_ "GenMsgILSupport" BO_ 1232 1;
BA_ "GenMsgSendType" BO_ 1232 0;
BA_ "GenMsgNrOfRepetition" BO_ 1232 0;
BA_ "GenMsgCycleTime" BO_ 1232 100;
BA_ "GenMsgILSupport" BO_ 1146 1;
BA_ "GenMsgSendType" BO_ 1146 0;
BA_ "GenMsgNrOfRepetition" BO_ 1146 0;
BA_ "GenMsgCycleTime" BO_ 1146 100;
BA_ "GenMsgILSupport" BO_ 1158 1;
BA_ "GenMsgSendType" BO_ 1158 0;
BA_ "GenMsgNrOfRepetition" BO_ 1158 0;
BA_ "GenMsgCycleTime" BO_ 1158 100;
BA_ "GenMsgILSupport" BO_ 1095 1;
BA_ "GenMsgSendType" BO_ 1095 0;
BA_ "GenMsgNrOfRepetition" BO_ 1095 0;
BA_ "GenMsgCycleTime" BO_ 1095 100;
BA_ "GenMsgILSupport" BO_ 704 1;
BA_ "GenMsgSendType" BO_ 704 0;
BA_ "GenMsgNrOfRepetition" BO_ 704 0;
BA_ "GenMsgCycleTime" BO_ 704 100;
BA_ "GenMsgILSupport" BO_ 745 1;
BA_ "GenMsgSendType" BO_ 745 0;
BA_ "GenMsgNrOfRepetition" BO_ 745 0;
BA_ "GenMsgCycleTime" BO_ 745 10;
BA_ "GenMsgILSupport" BO_ 800 1;
BA_ "GenMsgSendType" BO_ 800 0;
BA_ "GenMsgNrOfRepetition" BO_ 800 6;
BA_ "GenMsgDelayTime" BO_ 800 5;
BA_ "GenMsgCycleTimeFast" BO_ 800 20;
BA_ "GenMsgCycleTime" BO_ 800 500;
BA_ "DiagResponse" BO_ 1944 1;
BA_ "GenMsgNrOfRepetition" BO_ 1944 0;
BA_ "DiagResponse" BO_ 1765 1;
BA_ "GenMsgNrOfRepetition" BO_ 1765 0;
BA_ "NmAsrMessage" BO_ 1556 1;
BA_ "GenMsgSendType" BO_ 1556 0;
BA_ "GenMsgNrOfRepetition" BO_ 1556 0;
BA_ "GenMsgCycleTime" BO_ 1556 1000;
BA_ "GenMsgILSupport" BO_ 1152 1;
BA_ "GenMsgSendType" BO_ 1152 0;
BA_ "GenMsgNrOfRepetition" BO_ 1152 0;
BA_ "GenMsgCycleTime" BO_ 1152 50;
BA_ "GenMsgILSupport" BO_ 1219 1;
BA_ "GenMsgSendType" BO_ 1219 0;
BA_ "GenMsgNrOfRepetition" BO_ 1219 0;
BA_ "GenMsgCycleTime" BO_ 1219 100;
BA_ "GenMsgILSupport" BO_ 1025 1;
BA_ "GenMsgSendType" BO_ 1025 0;
BA_ "GenMsgNrOfRepetition" BO_ 1025 0;
BA_ "GenMsgCycleTime" BO_ 1025 100;
BA_ "GenMsgILSupport" BO_ 533 1;
BA_ "GenMsgDelayTime" BO_ 533 5;
BA_ "GenMsgCycleTimeFast" BO_ 533 100;
BA_ "GenMsgCycleTime" BO_ 533 100;
BA_ "GenMsgILSupport" BO_ 1329 1;
BA_ "GenMsgSendType" BO_ 1329 0;
BA_ "GenMsgNrOfRepetition" BO_ 1329 0;
BA_ "GenMsgCycleTime" BO_ 1329 500;
BA_ "GenMsgILSupport" BO_ 1066 1;
BA_ "GenMsgSendType" BO_ 1066 0;
BA_ "GenMsgNrOfRepetition" BO_ 1066 0;
BA_ "GenMsgCycleTime" BO_ 1066 100;
BA_ "GenMsgILSupport" BO_ 647 1;
BA_ "GenMsgSendType" BO_ 647 0;
BA_ "GenMsgNrOfRepetition" BO_ 647 0;
BA_ "GenMsgCycleTime" BO_ 647 20;
BA_ "GenMsgILSupport" BO_ 1107 1;
BA_ "GenMsgSendType" BO_ 1107 0;
BA_ "GenMsgNrOfRepetition" BO_ 1107 0;
BA_ "GenMsgCycleTime" BO_ 1107 500;
BA_ "GenMsgILSupport" BO_ 1106 1;
BA_ "GenMsgSendType" BO_ 1106 0;
BA_ "GenMsgNrOfRepetition" BO_ 1106 0;
BA_ "GenMsgCycleTime" BO_ 1106 100;
BA_ "GenMsgILSupport" BO_ 1072 1;
BA_ "GenMsgSendType" BO_ 1072 0;
BA_ "GenMsgNrOfRepetition" BO_ 1072 0;
BA_ "GenMsgCycleTime" BO_ 1072 20;
BA_ "GenMsgILSupport" BO_ 1275 1;
BA_ "GenMsgSendType" BO_ 1275 0;
BA_ "GenMsgNrOfRepetition" BO_ 1275 0;
BA_ "GenMsgCycleTime" BO_ 1275 100;
BA_ "GenMsgILSupport" BO_ 1224 1;
BA_ "GenMsgSendType" BO_ 1224 0;
BA_ "GenMsgNrOfRepetition" BO_ 1224 0;
BA_ "GenMsgCycleTime" BO_ 1224 100;
BA_ "GenMsgILSupport" BO_ 1315 1;
BA_ "GenMsgSendType" BO_ 1315 0;
BA_ "GenMsgNrOfRepetition" BO_ 1315 0;
BA_ "GenMsgCycleTime" BO_ 1315 500;
BA_ "GenMsgILSupport" BO_ 1514 1;
BA_ "GenMsgNrOfRepetition" BO_ 1514 0;
BA_ "GenMsgCycleTimeFast" BO_ 1514 1000;
BA_ "GenMsgILSupport" BO_ 1307 1;
BA_ "GenMsgSendType" BO_ 1307 0;
BA_ "GenMsgNrOfRepetition" BO_ 1307 0;
BA_ "GenMsgCycleTime" BO_ 1307 500;
BA_ "GenMsgILSupport" BO_ 914 1;
BA_ "GenMsgSendType" BO_ 914 0;
BA_ "GenMsgNrOfRepetition" BO_ 914 0;
BA_ "GenMsgCycleTime" BO_ 914 20;
BA_ "GenMsgILSupport" BO_ 1059 1;
BA_ "GenMsgSendType" BO_ 1059 0;
BA_ "GenMsgNrOfRepetition" BO_ 1059 0;
BA_ "GenMsgCycleTime" BO_ 1059 100;
BA_ "GenMsgILSupport" BO_ 1088 1;
BA_ "GenMsgSendType" BO_ 1088 0;
BA_ "GenMsgNrOfRepetition" BO_ 1088 0;
BA_ "GenMsgCycleTime" BO_ 1088 100;
BA_ "GenSigSendType" SG_ 3221225472 Diag_ICM_REQ 1;
BA_ "GenSigSendType" SG_ 3221225472 Diag_ICM_RES 1;
BA_ "GenSigSendType" SG_ 2015 DIAG_OBD_REQ_Broadcast 1;
BA_ "GenSigSendType" SG_ 1536 Nwmcommand 0;
BA_ "GenSigSendType" SG_ 1928 Diag_DMC_REQ 1;
BA_ "GenSigSendType" SG_ 1764 Calibration_Signals_REQ_ICM_7 1;
BA_ "GenSigSendType" SG_ 1443 BitStatus_TCU 1;
BA_ "GenSigSendType" SG_ 769 STAT_LeverModeDisp 0;
BA_ "GenSigSendType" SG_ 769 GBPositoionDisplay 0;
BA_ "GenSigSendType" SG_ 769 GBFaultstatus 0;
BA_ "GenSigSendType" SG_ 769 ClutchTemperature 0;
BA_ "GenSigSendType" SG_ 1203 RRCR_1_CRC 0;
BA_ "GenSigSendType" SG_ 1203 RRCR_1_MsgCntr 0;
BA_ "GenSigSendType" SG_ 1203 RRCR_1_ObjTyp 0;
BA_ "GenSigSendType" SG_ 1203 RRCR_1_BlkSts 0;
BA_ "GenSigSendType" SG_ 1203 RRCR_1_DOWWarn 0;
BA_ "GenSigSendType" SG_ 1203 RRCR_1_RCTAWarn 0;
BA_ "GenSigSendType" SG_ 1203 RRCR_1_BSDWarn 0;
BA_ "GenSigSendType" SG_ 1203 RRCR_1_SysSt 0;
BA_ "GenSigSendType" SG_ 1201 RLCR_1_RCWONOFFSts 0;
BA_ "GenSigSendType" SG_ 1201 RLCR_1_DOWONOFFSts 0;
BA_ "GenSigSendType" SG_ 1201 RLCR_1_BSDLCARCTAONOFFSts 0;
BA_ "GenSigSendType" SG_ 1201 RLCR_1_CRC 0;
BA_ "GenSigSendType" SG_ 1201 RLCR_1_MsgCntr 0;
BA_ "GenSigSendType" SG_ 1201 RLCR_1_ObjTyp 0;
BA_ "GenSigSendType" SG_ 1201 RLCR_1_RCWWarn 0;
BA_ "GenSigSendType" SG_ 1201 RLCR_1_DOWWarn 0;
BA_ "GenSigSendType" SG_ 1201 RLCR_1_RCTAWarn 0;
BA_ "GenSigSendType" SG_ 1201 RLCR_1_BSDWarn 0;
BA_ "GenSigSendType" SG_ 1201 RLCR_1_BlkSts 0;
BA_ "GenSigSendType" SG_ 1201 RLCR_1_RAEBWarn 0;
BA_ "GenSigSendType" SG_ 1201 RLCR_1_RCTBWarn 0;
BA_ "GenSigSendType" SG_ 1201 RLCR_1_SysSt 0;
BA_ "GenSigSendType" SG_ 1187 RHM_1_DRLFaildSts 0;
BA_ "GenSigSendType" SG_ 1187 RHM_1_RHTurnLiFaildSts 0;
BA_ "GenSigSendType" SG_ 1187 RHM_1_ParkLiFaildSts 0;
BA_ "GenSigSendType" SG_ 1187 RHM_1_LoBeamFaildSts 0;
BA_ "GenSigSendType" SG_ 1187 RHM_1_HiBeamFaildSts 0;
BA_ "GenSigSendType" SG_ 1208 PPMISt 0;
BA_ "GenSigStartValue" SG_ 1208 PPMISt 1;
BA_ "GenSigSendType" SG_ 1208 PPMICounter 0;
BA_ "GenSigSendType" SG_ 1218 LHM_1_ADBenable_Feedback 0;
BA_ "GenSigSendType" SG_ 1218 LHM_1_DBL_FaultSts 0;
BA_ "GenSigSendType" SG_ 1218 LHM_1_ADBSts 0;
BA_ "GenSigSendType" SG_ 1218 LHM_1_DRLFaildSts 0;
BA_ "GenSigSendType" SG_ 1218 LHM_1_LHTurnLiFaildSts 0;
BA_ "GenSigSendType" SG_ 1218 LHM_1_ParkLiFaildSts 0;
BA_ "GenSigSendType" SG_ 1218 LHM_1_LoBeamFaildSts 0;
BA_ "GenSigSendType" SG_ 1218 LHM_1_HiBeamFaildSts 0;
BA_ "GenSigStartValue" SG_ 1175 CST_SensitivitySts 2;
BA_ "GenSigSendType" SG_ 1175 CST_SensitivitySts 0;
BA_ "GenSigSendType" SG_ 1175 BrakepedalFeelSts 0;
BA_ "GenSigSendType" SG_ 1175 CST_Status 0;
BA_ "GenSigStartValue" SG_ 1175 CST_Status 1;
BA_ "GenSigSendType" SG_ 1175 IPB_AssociWithDriverModeSts 0;
BA_ "GenSigSendType" SG_ 1175 BrakesystemFailSts 0;
BA_ "GenSigSendType" SG_ 1175 TwofeetBrakeSts 0;
BA_ "GenSigSendType" SG_ 1175 BrakeFluidSts 0;
BA_ "GenSigSendType" SG_ 1175 FWAWarningSts 0;
BA_ "GenSigSendType" SG_ 906 IDCU_12_RmninfoTrig 0;
BA_ "GenSigSendType" SG_ 906 IDCU_12FCTAWarnRi 0;
BA_ "GenSigSendType" SG_ 906 IDCU_12FCTAWarnLe 0;
BA_ "GenSigSendType" SG_ 906 IDCU_12CPMod 0;
BA_ "GenSigSendType" SG_ 906 IDCU_12Rmninfo 0;
BA_ "GenSigSendType" SG_ 903 FCM_FRM_6_VSetDis 0;
BA_ "GenSigSendType" SG_ 903 FCM_FRM_6_AEBMode 0;
BA_ "GenSigStartValue" SG_ 903 FCM_FRM_6_AEBMode 2;
BA_ "GenSigSendType" SG_ 903 FCM_FRM_6_FCWMode 0;
BA_ "GenSigStartValue" SG_ 903 FCM_FRM_6_FCWMode 1;
BA_ "GenSigSendType" SG_ 903 FCM_FRM_6_TakeOverReq 0;
BA_ "GenSigSendType" SG_ 903 FCM_FRM_6_FCW_preWarning 0;
BA_ "GenSigSendType" SG_ 903 FCM_FRM_6_DistanceWarning 0;
BA_ "GenSigSendType" SG_ 903 FCM_FRM_6_DrvrCfmSCFDispFb 0;
BA_ "GenSigSendType" SG_ 903 FCM_FRM_6_SCF_SpdLimUnit 0;
BA_ "GenSigSendType" SG_ 903 FCM_FRM_6_SCF_SpdLimSts 0;
BA_ "GenSigSendType" SG_ 903 FCM_FRM_6_SCF_PopoverReq 0;
BA_ "GenSigSendType" SG_ 903 FCM_FRM_6_TimeGapSetICM 0;
BA_ "GenSigSendType" SG_ 903 FCM_FRM_6_ACCMode 0;
BA_ "GenSigSendType" SG_ 903 FCM_FRM_6_TextinfoWarn 0;
BA_ "GenSigSendType" SG_ 903 FCM_FRM_6_Textinfo_Info 0;
BA_ "GenSigSendType" SG_ 1020 FCM_10_EgoLeftLineHeatgAg 0;
BA_ "GenSigStartValue" SG_ 1020 FCM_10_EgoLeftLineHeatgAg 255;
BA_ "GenSigSendType" SG_ 1020 FCM_10_ELKIntvMod 0;
BA_ "GenSigSendType" SG_ 1020 FCM_10_WarnModSts 0;
BA_ "GenSigStartValue" SG_ 1020 FCM_10_WarnModSts 3;
BA_ "GenSigSendType" SG_ 1020 FCM_10_SLAONOFFSts 0;
BA_ "GenSigStartValue" SG_ 1020 FCM_10_SLAONOFFSts 1;
BA_ "GenSigSendType" SG_ 1020 FCM_10_TJAICAExitTextInfoSts 0;
BA_ "GenSigStartValue" SG_ 1020 FCM_10_TJAICAExitTextInfoSts 1;
BA_ "GenSigSendType" SG_ 1020 FCM_10_LDPTJAELKTakeoverReq 0;
BA_ "GenSigSendType" SG_ 1020 FCM_10_TJAICAEnaRcmend 0;
BA_ "GenSigSendType" SG_ 1020 FCM_10_TJAICATextinfo 0;
BA_ "GenSigSendType" SG_ 1020 FCM_10_TSINoParkWarn 0;
BA_ "GenSigSendType" SG_ 1020 FCM_10_ELKSysSts 0;
BA_ "GenSigSendType" SG_ 1020 FCM_10_LDWSysSts 0;
BA_ "GenSigSendType" SG_ 1020 FCM_10_LDPSysSts 0;
BA_ "GenSigSendType" SG_ 1020 FCM_10_TLITrfcLi 0;
BA_ "GenSigSendType" SG_ 1020 FCM_10_TSISgnLongStayDisp 0;
BA_ "GenSigSendType" SG_ 1020 FCM_10_TSISgnForb 0;
BA_ "GenSigSendType" SG_ 1020 FCM_10_TSISgnGiWay 0;
BA_ "GenSigSendType" SG_ 1020 FCM_10_TLISysSts 0;
BA_ "GenSigSendType" SG_ 1020 FCM_10_TSISysSts 0;
BA_ "GenSigSendType" SG_ 1018 FCM_FRM_9_RiObjHozDstY 0;
BA_ "GenSigStartValue" SG_ 1018 FCM_FRM_9_RiObjHozDstY 500;
BA_ "GenSigSendType" SG_ 1018 FCM_FRM_9_RiObjLgtDstX 0;
BA_ "GenSigSendType" SG_ 1018 FCM_FRM_9_RiObjTyp 0;
BA_ "GenSigSendType" SG_ 1018 FCM_FRM_9_RiObjID 0;
BA_ "GenSigSendType" SG_ 1018 FCM_FRM_9_LeObjHozDstY 0;
BA_ "GenSigStartValue" SG_ 1018 FCM_FRM_9_LeObjHozDstY 500;
BA_ "GenSigSendType" SG_ 1018 FCM_FRM_9_LeObjLgtDstX 0;
BA_ "GenSigSendType" SG_ 1018 FCM_FRM_9_LeObjTyp 0;
BA_ "GenSigSendType" SG_ 1018 FCM_FRM_9_LeObjID 0;
BA_ "GenSigSendType" SG_ 1005 FCM_FRM_8_FrntFarObjHozDstY 0;
BA_ "GenSigStartValue" SG_ 1005 FCM_FRM_8_FrntFarObjHozDstY 500;
BA_ "GenSigSendType" SG_ 1005 FCM_FRM_8_FrntFarObjLgtDstX 0;
BA_ "GenSigSendType" SG_ 1005 FCM_FRM_8_FrntFarObjTyp 0;
BA_ "GenSigSendType" SG_ 1005 FCM_FRM_8_FrntFarObjID 0;
BA_ "GenSigSendType" SG_ 1005 FCM_FRM_8_ACCObjHozDstY 0;
BA_ "GenSigStartValue" SG_ 1005 FCM_FRM_8_ACCObjHozDstY 500;
BA_ "GenSigSendType" SG_ 1005 FCM_FRM_8_ACCObjLgtDstX 0;
BA_ "GenSigSendType" SG_ 1005 FCM_FRM_8_ACCObjTyp 0;
BA_ "GenSigSendType" SG_ 1005 FCM_FRM_8_ACCObjID 0;
BA_ "GenSigSendType" SG_ 990 FCM_7_NeborRiLineCrvt 0;
BA_ "GenSigStartValue" SG_ 990 FCM_7_NeborRiLineCrvt 260;
BA_ "GenSigSendType" SG_ 990 FCM_7_NeborRiLineHozlDst 0;
BA_ "GenSigStartValue" SG_ 990 FCM_7_NeborRiLineHozlDst 250;
BA_ "GenSigSendType" SG_ 990 FCM_7_NeborRiLineTyp 0;
BA_ "GenSigSendType" SG_ 990 FCM_7_NeborRiLineColor 0;
BA_ "GenSigSendType" SG_ 990 FCM_7_NeborRiLineID 0;
BA_ "GenSigSendType" SG_ 990 FCM_7_NeborLeLineCrvt 0;
BA_ "GenSigStartValue" SG_ 990 FCM_7_NeborLeLineCrvt 260;
BA_ "GenSigSendType" SG_ 990 FCM_7_NeborLeLineHozlDst 0;
BA_ "GenSigStartValue" SG_ 990 FCM_7_NeborLeLineHozlDst 250;
BA_ "GenSigSendType" SG_ 990 FCM_7_NeborLeLineTyp 0;
BA_ "GenSigSendType" SG_ 990 FCM_7_NeborLeLineColor 0;
BA_ "GenSigSendType" SG_ 990 FCM_7_NeborLeLineID 0;
BA_ "GenSigSendType" SG_ 988 FCM_6_EgoRiLineCrvt 0;
BA_ "GenSigStartValue" SG_ 988 FCM_6_EgoRiLineCrvt 260;
BA_ "GenSigSendType" SG_ 988 FCM_6_EgoRiLineHozlDst 0;
BA_ "GenSigStartValue" SG_ 988 FCM_6_EgoRiLineHozlDst 250;
BA_ "GenSigSendType" SG_ 988 FCM_6_EgoRiLineTyp 0;
BA_ "GenSigSendType" SG_ 988 FCM_6_EgoRiLineColor 0;
BA_ "GenSigSendType" SG_ 988 FCM_6_EgoRiLineID 0;
BA_ "GenSigSendType" SG_ 988 FCM_6_EgoLeLineCrvt 0;
BA_ "GenSigStartValue" SG_ 988 FCM_6_EgoLeLineCrvt 260;
BA_ "GenSigSendType" SG_ 988 FCM_6_EgoLeLineHozlDst 0;
BA_ "GenSigStartValue" SG_ 988 FCM_6_EgoLeLineHozlDst 250;
BA_ "GenSigSendType" SG_ 988 FCM_6_EgoLeLineTyp 0;
BA_ "GenSigSendType" SG_ 988 FCM_6_EgoLeLineColor 0;
BA_ "GenSigSendType" SG_ 988 FCM_6_EgoLeLineID 0;
BA_ "GenSigSendType" SG_ 775 FCM_2_SLASpdlimitUnits 0;
BA_ "GenSigSendType" SG_ 775 TJA_ICA_mode 0;
BA_ "GenSigSendType" SG_ 775 Camera_textinfo 0;
BA_ "GenSigSendType" SG_ 775 FCM_2_SpdLimtyp 0;
BA_ "GenSigSendType" SG_ 775 SLASpdlimitWarning 0;
BA_ "GenSigSendType" SG_ 775 SLASpdlimit 0;
BA_ "GenSigSendType" SG_ 775 FCM_2_SCFSpdlimWarn 0;
BA_ "GenSigSendType" SG_ 775 SLAState 0;
BA_ "GenSigStartValue" SG_ 775 SLAState 1;
BA_ "GenSigSendType" SG_ 775 LDW_ELK_TJA_LDPRightVisuali 0;
BA_ "GenSigSendType" SG_ 775 LDW_ELK_TJA_LDPLeftVisuali 0;
BA_ "GenSigSendType" SG_ 775 HMA_HighbeamReq 0;
BA_ "GenSigSendType" SG_ 775 HMA_Status 0;
BA_ "GenSigStartValue" SG_ 775 HMA_Status 1;
BA_ "GenSigSendType" SG_ 896 EPS_AssociWithDriverModeSts 0;
BA_ "GenSigSendType" SG_ 896 EPS_AssistanceStyle_Sts 0;
BA_ "GenSigSendType" SG_ 896 EPS_EOTLearning_Sts 0;
BA_ "GenSigSendType" SG_ 896 EPS_1_MessageCounter 0;
BA_ "GenSigSendType" SG_ 896 EPSSteeringAngleCalibrationSts 0;
BA_ "GenSigSendType" SG_ 896 EPSFailSts 0;
BA_ "GenSigSendType" SG_ 1270 Yellowwarning 0;
BA_ "GenSigSendType" SG_ 1270 Redwarning 0;
BA_ "GenSigSendType" SG_ 1270 RWUActive 0;
BA_ "GenSigSendType" SG_ 1270 EPBStatus 0;
BA_ "GenSigSendType" SG_ 1270 EPBWarningMessage 0;
BA_ "GenSigSendType" SG_ 640 EngineSts 0;
BA_ "GenSigSendType" SG_ 640 GearReduceIndication 0;
BA_ "GenSigSendType" SG_ 640 GearRaiseIndication 0;
BA_ "GenSigSendType" SG_ 640 TargetGearPosition 0;
BA_ "GenSigSendType" SG_ 640 SSMStatus 0;
BA_ "GenSigSendType" SG_ 640 EPCSts 0;
BA_ "GenSigStartValue" SG_ 640 EPCSts 1;
BA_ "GenSigSendType" SG_ 640 EngineSpeedValidData 0;
BA_ "GenSigSendType" SG_ 640 FuelRollingCounterValidData 0;
BA_ "GenSigSendType" SG_ 640 ISS_Sts_GS 0;
BA_ "GenSigSendType" SG_ 640 EngineSpeed 0;
BA_ "GenSigSendType" SG_ 640 FuelRollingCounter 0;
BA_ "GenSigStartValue" SG_ 640 FuelRollingCounter 255;
BA_ "GenSigSendType" SG_ 640 EngineCoolantTemperture 0;
BA_ "GenSigStartValue" SG_ 640 EngineCoolantTemperture 91;
BA_ "GenSigSendType" SG_ 640 CruiseControlStsForDisplay 0;
BA_ "GenSigSendType" SG_ 640 ECSControlSts 0;
BA_ "GenSigSendType" SG_ 640 EngineCoolantTempertureFailSts 0;
BA_ "GenSigSendType" SG_ 640 MILSts 0;
BA_ "GenSigStartValue" SG_ 640 MILSts 2;
BA_ "GenSigSendType" SG_ 640 IEMSts 0;
BA_ "GenSigStartValue" SG_ 640 IEMSts 1;
BA_ "GenSigSendType" SG_ 640 GPFWarning 0;
BA_ "GenSigSendType" SG_ 1232 Energy_Flow_Sts 0;
BA_ "GenSigSendType" SG_ 1232 Battery_Sts 0;
BA_ "GenSigSendType" SG_ 1232 Battery_Temp_Sts 0;
BA_ "GenSigSendType" SG_ 1146 AllWarningInfo 0;
BA_ "GenSigSendType" SG_ 1158 AWDoutserviceDispRq 0;
BA_ "GenSigSendType" SG_ 1095 AFS_FaultSts 0;
BA_ "GenSigSendType" SG_ 704 ABS_ESP_Checksum 0;
BA_ "GenSigSendType" SG_ 704 CDPFailSts 0;
BA_ "GenSigSendType" SG_ 704 AVHFailSts 0;
BA_ "GenSigSendType" SG_ 704 AVHSts 0;
BA_ "GenSigSendType" SG_ 704 HDCFailSts 0;
BA_ "GenSigSendType" SG_ 704 HDCCtrlSts 0;
BA_ "GenSigSendType" SG_ 704 DiagnosticSessionSts 0;
BA_ "GenSigSendType" SG_ 704 ABS_ESP_MessageCounter 0;
BA_ "GenSigSendType" SG_ 704 VehicleSpeedVSOSigValidData 0;
BA_ "GenSigStartValue" SG_ 704 VehicleSpeedVSOSigValidData 1;
BA_ "GenSigSendType" SG_ 704 VehicleSpeedVSOSig 0;
BA_ "GenSigSendType" SG_ 704 CDPActive 0;
BA_ "GenSigSendType" SG_ 704 ESPSwitchStatus 0;
BA_ "GenSigSendType" SG_ 704 HHCFailSts 0;
BA_ "GenSigSendType" SG_ 704 VDCActive 0;
BA_ "GenSigSendType" SG_ 704 TCSActive 0;
BA_ "GenSigSendType" SG_ 704 VDCFailSts 0;
BA_ "GenSigSendType" SG_ 704 TCSFailSts 0;
BA_ "GenSigSendType" SG_ 704 EBDFailSts 0;
BA_ "GenSigSendType" SG_ 704 ABSFailSts 0;
BA_ "GenSigSendType" SG_ 704 AVHWarningMessage 0;
BA_ "GenSigSendType" SG_ 745 AEBdecAvailable 0;
BA_ "GenSigSendType" SG_ 745 AEBdecActive 0;
BA_ "GenSigSendType" SG_ 800 ABM_1_PABSetSts 0;
BA_ "GenSigSendType" SG_ 800 ABM_1_MessageCounter 0;
BA_ "GenSigSendType" SG_ 800 SecRowRBeltWarning 0;
BA_ "GenSigSendType" SG_ 800 SecRowMBeltWarning 0;
BA_ "GenSigSendType" SG_ 800 SecRowLBeltWarning 0;
BA_ "GenSigSendType" SG_ 800 ThdRowRBeltWarning 0;
BA_ "GenSigSendType" SG_ 800 ThdRowLBeltWarning 0;
BA_ "GenSigSendType" SG_ 800 PsngrSeatBeltWarning 0;
BA_ "GenSigSendType" SG_ 800 AirBagFailSts 0;
BA_ "GenSigStartValue" SG_ 800 AirBagFailSts 3;
BA_ "GenSigSendType" SG_ 1944 Diag_DMC_RES 1;
BA_ "GenSigSendType" SG_ 1765 Calibration_Signals_RES_ICM_8 1;
BA_ "GenSigSendType" SG_ 1556 WakeupSource_ICM 0;
BA_ "GenSigSendType" SG_ 1556 usrData4_ICM 0;
BA_ "GenSigSendType" SG_ 1556 usrData3_ICM 0;
BA_ "GenSigSendType" SG_ 1556 usrData2_ICM 0;
BA_ "GenSigSendType" SG_ 1556 ECUSPEC_AWAKE_ICM 0;
BA_ "GenSigSendType" SG_ 1556 DIAGNOSTIC_AWAKE_ICM 0;
BA_ "GenSigSendType" SG_ 1556 IGNITION_AWAKE_ICM 0;
BA_ "GenSigSendType" SG_ 1556 NETWORK_AWAKE_ICM 0;
BA_ "GenSigSendType" SG_ 1556 ECUSPEC_WAKEUP_ICM 0;
BA_ "GenSigSendType" SG_ 1556 NETWORK_WAKEUP_ICM 0;
BA_ "GenSigSendType" SG_ 1556 RESET_WAKEUP_ICM 0;
BA_ "GenSigSendType" SG_ 1556 IGNITION_WAKEUP_ICM 0;
BA_ "GenSigSendType" SG_ 1556 usrData0_ICM 0;
BA_ "GenSigSendType" SG_ 1556 NMm_ICM_Reserved1 0;
BA_ "GenSigSendType" SG_ 1556 RMR_ICM 0;
BA_ "GenSigSendType" SG_ 1556 srcNodeID_ICM 0;
BA_ "GenSigStartValue" SG_ 1556 srcNodeID_ICM 20;
BA_ "GenSigSendType" SG_ 1152 RemoteStartSts 0;
BA_ "GenSigSendType" SG_ 1152 SmartSystemWarning4_3 0;
BA_ "GenSigSendType" SG_ 1152 SmartSystemWarning2_0 0;
BA_ "GenSigSendType" SG_ 1152 SmartSystemWarning2_2 0;
BA_ "GenSigSendType" SG_ 1152 SmartSystemWarning1_0 0;
BA_ "GenSigSendType" SG_ 1152 SmartSystemWarning1_1 0;
BA_ "GenSigSendType" SG_ 1152 SmartSystemWarning1_3 0;
BA_ "GenSigSendType" SG_ 1152 SmartSystemWarning3_1 0;
BA_ "GenSigSendType" SG_ 1152 SmartSystemWarning3_2 0;
BA_ "GenSigSendType" SG_ 1152 SmartSystemWarning4_2 0;
BA_ "GenSigSendType" SG_ 1219 PAS_1_DriverDoorSIllSts 0;
BA_ "GenSigSendType" SG_ 1025 ESCLNotLocked 0;
BA_ "GenSigSendType" SG_ 1025 ESCLUnlockJamming 0;
BA_ "GenSigSendType" SG_ 1025 ESCLFunctionFailure 0;
BA_ "GenSigSendType" SG_ 1025 ESCLCriticalFailure 0;
BA_ "GenSigSendType" SG_ 533 ICM_8_Resd1 0;
BA_ "GenSigSendType" SG_ 533 ICM_8_FrntRadarSwt 2;
BA_ "GenSigSendType" SG_ 533 ICM_ESPSwitchCmd 2;
BA_ "GenSigSendType" SG_ 533 ICM_ISS_Switch 2;
BA_ "GenSigSendType" SG_ 533 SetICMAlarm 2;
BA_ "GenSigSendType" SG_ 1329 SIA_IntervalDistance 0;
BA_ "GenSigSendType" SG_ 1329 ICM_7_Reserved2 0;
BA_ "GenSigSendType" SG_ 1329 SIA_LastDay 0;
BA_ "GenSigStartValue" SG_ 1329 SIA_LastDay 1;
BA_ "GenSigSendType" SG_ 1329 SIA_LastYear 0;
BA_ "GenSigStartValue" SG_ 1329 SIA_LastYear 19;
BA_ "GenSigSendType" SG_ 1329 SIA_LastMonth 0;
BA_ "GenSigStartValue" SG_ 1329 SIA_LastMonth 1;
BA_ "GenSigSendType" SG_ 1329 SIA_IntervalTime 0;
BA_ "GenSigSendType" SG_ 1329 ICM_7_Reserved1 0;
BA_ "GenSigSendType" SG_ 1329 SIA_LastODO 0;
BA_ "GenSigSendType" SG_ 1066 TotalOdometer_km_OBDValidData 0;
BA_ "GenSigSendType" SG_ 1066 TotalOdometer_km_OBD 0;
BA_ "GenSigSendType" SG_ 1066 TotODOMtrBkpEna 0;
BA_ "GenSigSendType" SG_ 1066 DrivermodeReq 0;
BA_ "GenSigSendType" SG_ 647 ICM_5_Checksum 0;
BA_ "GenSigSendType" SG_ 647 ICM_5_MessageCounter 0;
BA_ "GenSigSendType" SG_ 647 ICM_DVDAudibleAlarmStyle 0;
BA_ "GenSigSendType" SG_ 647 ICM_DVDAudibleAlarm 0;
BA_ "GenSigSendType" SG_ 647 BrakeFluidWarning 0;
BA_ "GenSigSendType" SG_ 647 ICM_5_Reserved_2 0;
BA_ "GenSigSendType" SG_ 647 ACC_Kilometre_Mile 0;
BA_ "GenSigSendType" SG_ 647 DriverSeatBeltSwitchQbit 0;
BA_ "GenSigSendType" SG_ 647 ICM_5_DriverSeatBeltSwitch 0;
BA_ "GenSigSendType" SG_ 647 CTP_DriveModeSet 0;
BA_ "GenSigSendType" SG_ 647 ICM_5_AlrmVolCtrl 4;
BA_ "GenSigSendType" SG_ 647 ICM_5_BackLiBriAdjmt 4;
BA_ "GenSigSendType" SG_ 647 AverageFuelConsumption50 0;
BA_ "GenSigSendType" SG_ 647 ICM_5_FuelLevel 0;
BA_ "GenSigSendType" SG_ 647 FuelValidData 0;
BA_ "GenSigSendType" SG_ 647 FuelOutOfRange 0;
BA_ "GenSigSendType" SG_ 647 FuelShortPower 0;
BA_ "GenSigSendType" SG_ 647 FuelShortGround 0;
BA_ "GenSigSendType" SG_ 647 HandBrakeSystemStsValidData 0;
BA_ "GenSigSendType" SG_ 647 HandBrakeSystemSts 0;
BA_ "GenSigSendType" SG_ 1107 Reserved_ThemeTypeFeedback 0;
BA_ "GenSigSendType" SG_ 1107 FatigureDrivingWarning 0;
BA_ "GenSigSendType" SG_ 1107 CurrentTimeYear 0;
BA_ "GenSigSendType" SG_ 1107 CurrentTimeMonth 0;
BA_ "GenSigStartValue" SG_ 1107 CurrentTimeMonth 1;
BA_ "GenSigSendType" SG_ 1107 CurrentTimeDay 0;
BA_ "GenSigStartValue" SG_ 1107 CurrentTimeDay 1;
BA_ "GenSigSendType" SG_ 1107 ResidualOdometer 0;
BA_ "GenSigStartValue" SG_ 1107 ResidualOdometer 1023;
BA_ "GenSigSendType" SG_ 1107 CurrentTimeSecond 0;
BA_ "GenSigSendType" SG_ 1107 ICM_BrightnessLevel 0;
BA_ "GenSigSendType" SG_ 1107 MaintainWarning 0;
BA_ "GenSigSendType" SG_ 1107 LowFuleWarning 0;
BA_ "GenSigSendType" SG_ 1107 FatigureDrivingTime 0;
BA_ "GenSigStartValue" SG_ 1107 FatigureDrivingTime 1;
BA_ "GenSigSendType" SG_ 1107 CurrentTimeMinute 0;
BA_ "GenSigSendType" SG_ 1107 CurrentTimeHour 0;
BA_ "GenSigSendType" SG_ 1106 ICM_2_Reserved3 0;
BA_ "GenSigSendType" SG_ 1106 FrontSeatBeltAlarmLight 0;
BA_ "GenSigSendType" SG_ 1106 ICM_2_OverSpeedValue 0;
BA_ "GenSigSendType" SG_ 1106 QDashACCFail 0;
BA_ "GenSigSendType" SG_ 1106 DISFail 0;
BA_ "GenSigSendType" SG_ 1106 ICM_2_LoWshLqdWarn 0;
BA_ "GenSigSendType" SG_ 1106 BackLightLevel 0;
BA_ "GenSigSendType" SG_ 1106 TemperatureUnit_ICM 0;
BA_ "GenSigSendType" SG_ 1106 ICM_2_Reserved1 0;
BA_ "GenSigSendType" SG_ 1106 AirBagLampFailSts 0;
BA_ "GenSigSendType" SG_ 1106 AverageFuelConsumption 0;
BA_ "GenSigSendType" SG_ 1072 TotalOdometer_km 0;
BA_ "GenSigSendType" SG_ 1072 EngineCoolantTempertureHighWarn 0;
BA_ "GenSigSendType" SG_ 1072 Reserved_HandBrakeSts 0;
BA_ "GenSigSendType" SG_ 1072 FuelLevel 0;
BA_ "GenSigSendType" SG_ 1072 ICM_1MessageCounter 0;
BA_ "GenSigSendType" SG_ 1072 FuelLevelFailSts 0;
BA_ "GenSigSendType" SG_ 1072 EngineOilPressureLowWarn 0;
BA_ "GenSigSendType" SG_ 1072 DriverSeatBeltSwitch 0;
BA_ "GenSigSendType" SG_ 1072 ECOModeSWSts 0;
BA_ "GenSigSendType" SG_ 1072 BatteryVoltage 0;
BA_ "GenSigSendType" SG_ 1072 DisplayVehicleSpeed 0;
BA_ "GenSigSendType" SG_ 1072 ICM_1_HandBrakeSystemSts 0;
BA_ "GenSigSendType" SG_ 1275 DCM_1_PwrDoorErr 0;
BA_ "GenSigSendType" SG_ 1275 DCM_1_RHRStallSts 0;
BA_ "GenSigSendType" SG_ 1275 DCM_1_LHRStallSts 0;
BA_ "GenSigSendType" SG_ 1275 DCM_1_PassStallSts 0;
BA_ "GenSigSendType" SG_ 1275 DCM_1_DrvrStallSts 0;
BA_ "GenSigStartValue" SG_ 1275 DCM_1_DrvrStallSts 1;
BA_ "GenSigSendType" SG_ 1224 BCM_RRPLMfailsts 0;
BA_ "GenSigSendType" SG_ 1224 BCM_RRFLMfailsts 0;
BA_ "GenSigSendType" SG_ 1224 BCM_RLPLMfailsts 0;
BA_ "GenSigSendType" SG_ 1224 BCM_RLFLMfailsts 0;
BA_ "GenSigSendType" SG_ 1224 BCM_RHMfailsts 0;
BA_ "GenSigSendType" SG_ 1224 BCM_LHMfailsts 0;
BA_ "GenSigSendType" SG_ 1224 ReFogLiFaildSts 0;
BA_ "GenSigSendType" SG_ 1224 ReversinglampFaultSts 0;
BA_ "GenSigSendType" SG_ 1224 BrakelampFaultSts 0;
BA_ "GenSigSendType" SG_ 1224 FrntFogFaildSts 0;
BA_ "GenSigSendType" SG_ 1224 DRLFaildSts 0;
BA_ "GenSigSendType" SG_ 1224 BDM_21_RHTurnlightSts 0;
BA_ "GenSigSendType" SG_ 1224 BDM_21_LHTurnlightSts 0;
BA_ "GenSigSendType" SG_ 1224 ParkLiFaildSts 0;
BA_ "GenSigSendType" SG_ 1224 LoBeamFaildSts 0;
BA_ "GenSigSendType" SG_ 1224 HiBeamFaildSts 0;
BA_ "GenSigSendType" SG_ 1315 BCM_16_RHRTirePressure 0;
BA_ "GenSigSendType" SG_ 1315 BCM_16_LHRTirePressure 0;
BA_ "GenSigSendType" SG_ 1315 BCM_16_RHFTirePressure 0;
BA_ "GenSigSendType" SG_ 1315 BCM_16_LHFTirePressure 0;
BA_ "GenSigSendType" SG_ 1315 BCM_16_Reserved1 0;
BA_ "GenSigSendType" SG_ 1307 RHRTirePressure 0;
BA_ "GenSigSendType" SG_ 1307 LHRTirePressure 0;
BA_ "GenSigSendType" SG_ 1307 RHFTirePressure 0;
BA_ "GenSigSendType" SG_ 1307 LHFTirePressure 0;
BA_ "GenSigSendType" SG_ 1307 TireTemperature 0;
BA_ "GenSigSendType" SG_ 1307 TirePosition 0;
BA_ "GenSigSendType" SG_ 1307 TirePositionWarning_RHRTire 0;
BA_ "GenSigSendType" SG_ 1307 TirePositionWarning_LHRTire 0;
BA_ "GenSigSendType" SG_ 1307 TirePositionWarning_RHFTire 0;
BA_ "GenSigSendType" SG_ 1307 TirePositionWarning_LHFTire 0;
BA_ "GenSigSendType" SG_ 1307 TirePressureWarningLampSts 0;
BA_ "GenSigSendType" SG_ 1307 TirePressureSystemFailSts 0;
BA_ "GenSigSendType" SG_ 914 DRLModeSts 0;
BA_ "GenSigStartValue" SG_ 914 DRLModeSts 1;
BA_ "GenSigSendType" SG_ 914 HeadlampDelayLightSts 0;
BA_ "GenSigStartValue" SG_ 914 HeadlampDelayLightSts 1;
BA_ "GenSigSendType" SG_ 914 AutolockSts 0;
BA_ "GenSigSendType" SG_ 914 AutoFoldSts 0;
BA_ "GenSigSendType" SG_ 914 HeadlampHeightFeedbackSts 0;
BA_ "GenSigSendType" SG_ 914 RemoteLockFeedbackSts 0;
BA_ "GenSigSendType" SG_ 914 BCM_4_DriverDoorLockSts 0;
BA_ "GenSigStartValue" SG_ 914 BCM_4_DriverDoorLockSts 1;
BA_ "GenSigSendType" SG_ 914 DrvrDoorUnlckOnlySts 0;
BA_ "GenSigSendType" SG_ 914 FGHeat_Req_CmdFeedback 0;
BA_ "GenSigSendType" SG_ 914 RearFoglightFaultSts 0;
BA_ "GenSigSendType" SG_ 914 BCM_4_ChildSafetySts 0;
BA_ "GenSigSendType" SG_ 914 WiperSensitivitySWSts 0;
BA_ "GenSigSendType" SG_ 914 RainSensorFailSts 0;
BA_ "GenSigSendType" SG_ 914 ReversinglampFaultSts 0;
BA_ "GenSigSendType" SG_ 914 BCM_4_FrontFogLightSts 0;
BA_ "GenSigSendType" SG_ 914 BrakelampFaultSts 0;
BA_ "GenSigSendType" SG_ 914 BCM_4_ReverseGearSts 0;
BA_ "GenSigSendType" SG_ 914 BCM_4_RearFogLightSts 0;
BA_ "GenSigSendType" SG_ 914 BCM_4_TrunkSts 0;
BA_ "GenSigSendType" SG_ 914 BCM_4_LHRdoorSts 0;
BA_ "GenSigSendType" SG_ 914 BCM_4_RHRDoorSts 0;
BA_ "GenSigSendType" SG_ 914 BCM_4_HoodSts 0;
BA_ "GenSigSendType" SG_ 914 BCM_4_PsngrDoorSts 0;
BA_ "GenSigSendType" SG_ 914 BCM_4_DriverDoorSts 0;
BA_ "GenSigSendType" SG_ 914 FollowMeTimeSts 0;
BA_ "GenSigSendType" SG_ 914 RVSMode 0;
BA_ "GenSigSendType" SG_ 914 BCM_4_DirectionIndLeft 0;
BA_ "GenSigSendType" SG_ 914 BCM_4_DirectionIndRight 0;
BA_ "GenSigSendType" SG_ 914 BCM_4_DRLSts 0;
BA_ "GenSigSendType" SG_ 914 BCM_4_HighBeamSts 0;
BA_ "GenSigSendType" SG_ 914 BCM_4_ParkLightSts 0;
BA_ "GenSigSendType" SG_ 914 BCM_4_LHTurnlightSts 0;
BA_ "GenSigSendType" SG_ 914 BCM_4_RHTurnlightSts 0;
BA_ "GenSigSendType" SG_ 914 BCM_4_KeySts 0;
BA_ "GenSigSendType" SG_ 914 LightDetected 0;
BA_ "GenSigSendType" SG_ 914 KeyRemindWarning 0;
BA_ "GenSigSendType" SG_ 914 BCM_4_ArmingSts 0;
BA_ "GenSigSendType" SG_ 1059 LDWSensitivitySettingFeedback 0;
BA_ "GenSigStartValue" SG_ 1059 LDWSensitivitySettingFeedback 2;
BA_ "GenSigSendType" SG_ 1059 LDWSwitchStsFeedback 0;
BA_ "GenSigStartValue" SG_ 1059 LDWSwitchStsFeedback 1;
BA_ "GenSigSendType" SG_ 1059 LDWWorkingSts 0;
BA_ "GenSigSendType" SG_ 1059 LDWWarningSts 0;
BA_ "GenSigSendType" SG_ 1059 LDWLaneDetectionSts 0;
BA_ "GenSigSendType" SG_ 1088 RadarWorkSts 0;
BA_ "GenSigSendType" SG_ 1088 RadarDetectSts 0;
BA_ "GenSigSendType" SG_ 1088 AudibleBeepRate 0;
BA_ "GenSigSendType" SG_ 1088 LHMFRadarSensorDistance 0;
BA_ "GenSigStartValue" SG_ 1088 LHMFRadarSensorDistance 30;
BA_ "GenSigSendType" SG_ 1088 RHMFRadarSensorDistance 0;
BA_ "GenSigStartValue" SG_ 1088 RHMFRadarSensorDistance 30;
BA_ "GenSigSendType" SG_ 1088 RHFRadarSensorDistance 0;
BA_ "GenSigStartValue" SG_ 1088 RHFRadarSensorDistance 30;
BA_ "GenSigSendType" SG_ 1088 LHFRadarSensorDistance 0;
BA_ "GenSigStartValue" SG_ 1088 LHFRadarSensorDistance 30;
BA_ "GenSigSendType" SG_ 1088 RHRRadarSensorDistance 0;
BA_ "GenSigStartValue" SG_ 1088 RHRRadarSensorDistance 62;
BA_ "GenSigSendType" SG_ 1088 LHMRRadarSensorDistance 0;
BA_ "GenSigStartValue" SG_ 1088 LHMRRadarSensorDistance 62;
BA_ "GenSigSendType" SG_ 1088 RHMRRadarSensorDistance 0;
BA_ "GenSigStartValue" SG_ 1088 RHMRRadarSensorDistance 62;
BA_ "GenSigSendType" SG_ 1088 LHRRadarSensorDistance 0;
BA_ "GenSigStartValue" SG_ 1088 LHRRadarSensorDistance 62;
VAL_ 1443 BitBlinking_TCU 0 " No action" 3 " Invalid signal" 2 " 3Hz" 1 " 1Hz" ;
VAL_ 1443 BitStatus_TCU 3 " Invalid" 2 " Reserved" 1 " Reset" 0 " Set" ;
VAL_ 769 STAT_LeverModeDisp 7 " Invalid" 6 " Failure value" 5 " Display M" 4 " Display D" 3 " Display N" 2 " Display R" 1 " Display P" 0 " No Display" ;
VAL_ 769 GBPositoionDisplay 30 "Display M9-" 29 " Display M8-" 28 "Display M8+" 27 " Display M9" 26 " Display M8" 25 " Display M7-" 24 " Display M6-" 23 "Display M5-" 22 "Display M4-" 21 " Display M3-" 20 " Display M2-" 19 " Display M7+" 18 " Display M6+" 17 " Display M5+" 16 "Display M4+" 15 " Display M3+" 14 "Display M2+" 13 "Display M1+" 12 "Low" 11 "Display M7" 10 "Display M6" 9 "Display M5" 8 "Display M4" 7 "Display M3" 6 "Display M2" 5 "Display M1" 4 " Display D" 3 "Display N" 2 " Display R" 1 " Display P" 0 "NO Display" ;
VAL_ 769 GBFaultstatus 3 "Clutch over temperature" 2 "High oil over temperature" 1 "GB failure" 0 "No failure" ;
VAL_ 769 ClutchTemperature 3 " Not used" 2 " Super over" 1 " Over" 0 " Normal" ;
VAL_ 1203 RRCR_1_ObjTyp 3 " Not Used" 2 " Two wheels vehicle " 1 " Four wheels vehicle " 0 "  Invalid" ;
VAL_ 1203 RRCR_1_BlkSts 1 " Blockage" 0 " Not Blockage" ;
VAL_ 1203 RRCR_1_DOWWarn 3 " Not Used" 2 " Level2 Warning " 1 " Level1 Warning " 0 " No Warning" ;
VAL_ 1203 RRCR_1_RCTAWarn 1 " Warning" 0 " No Warning" ;
VAL_ 1203 RRCR_1_BSDWarn 3 " Not Used" 2 " Critical Warning" 1 " Standard Warning" 0 " No Warning" ;
VAL_ 1203 RRCR_1_SysSt 3 " System Error" 2 " Temporary Error" 1 " On" 0 " Off" ;
VAL_ 1201 RLCR_1_ObjTyp 3 " Not Used" 2 " Two wheels vehicle " 1 " Four wheels vehicle " 0 "  Invalid" ;
VAL_ 1201 RLCR_1_RCWWarn 3 " Not Used" 2 " Level2 Warning " 1 " Level1 Warning " 0 " No Warning" ;
VAL_ 1201 RLCR_1_DOWWarn 3 " Not Used" 2 " Level2 Warning " 1 " Level1 Warning " 0 " No Warning" ;
VAL_ 1201 RLCR_1_RCTAWarn 1 " Warning" 0 " No Warning" ;
VAL_ 1201 RLCR_1_BSDWarn 3 " Not Used" 2 " Critical Warning" 1 " Standard Warning" 0 " No Warning" ;
VAL_ 1201 RLCR_1_BlkSts 1 " Blockage" 0 " Not Blockage" ;
VAL_ 1201 RLCR_1_RAEBWarn 1 " Warning" 0 " No Warning" ;
VAL_ 1201 RLCR_1_RCTBWarn 1 " Warning" 0 " No Warning" ;
VAL_ 1201 RLCR_1_SysSt 3 " System Error" 2 " Temporary Error" 1 " On" 0 " Off" ;
VAL_ 1187 RHM_1_DRLFaildSts 1 " Failure" 0 " Normal" ;
VAL_ 1187 RHM_1_RHTurnLiFaildSts 1 " Failure" 0 " Normal" ;
VAL_ 1187 RHM_1_ParkLiFaildSts 1 " Failure" 0 " Normal" ;
VAL_ 1187 RHM_1_LoBeamFaildSts 1 " Failure" 0 " Normal" ;
VAL_ 1187 RHM_1_HiBeamFaildSts 1 " Failure" 0 " Normal" ;
VAL_ 1208 PPMISt 3 " External error" 2 " PPMI internal error" 1 " PPMI initialization" 0 " PPMI no error" ;
VAL_ 1208 PPMICounter 1 " Count is full" 0 " Count not full" ;
VAL_ 1218 LHM_1_DBL_FaultSts 1 " Fault" 0 " Not Fault" ;
VAL_ 1218 LHM_1_ADBSts 3 " Fault" 2 " Active" 1 " Standby" 0 " ADB Off" ;
VAL_ 1218 LHM_1_DRLFaildSts 1 " Failure" 0 " Normal" ;
VAL_ 1218 LHM_1_LHTurnLiFaildSts 1 " Failure" 0 " Normal" ;
VAL_ 1218 LHM_1_ParkLiFaildSts 1 " Failure" 0 " Normal" ;
VAL_ 1218 LHM_1_LoBeamFaildSts 1 " Failure" 0 " Normal" ;
VAL_ 1218 LHM_1_HiBeamFaildSts 1 " Failure" 0 " Normal" ;
VAL_ 1175 BrakesystemFailSts 1 "  Fail present" 0 "  Fail not present" ;
VAL_ 1175 TwofeetBrakeSts 1 "  Twofeet Brake Occur" 0 "  Normal" ;
VAL_ 1175 BrakeFluidSts 3 "  Not used" 2 "  Electric_error" 1 "  Empty" 0 "  Normal" ;
VAL_ 1175 FWAWarningSts 3 "  Not used" 2 "  BrakeSys High Temperature Leve2" 1 "  BrakeSys High Temperature Leve1" 0 "  No failure" ;
VAL_ 906 IDCU_12_RmninfoTrig 3 "Reserved" 2 "Reset" 1 "Set" 0 " Not active" ;
VAL_ 906 IDCU_12FCTAWarnRi 1 " Warning" 0 " No Warning" ;
VAL_ 906 IDCU_12FCTAWarnLe 1 " Warning" 0 " No Warning" ;
VAL_ 906 IDCU_12CPMod 15 " Reserved" 13 " Reserved" 12 " Reserved" 11 " Reserved" 10 " Failure mode" 9 " safe stop mode" 8 " NOC lateral override mode" 7 " CP lateral override mode" 6 " NOC Active-Control mode" 5 " NOC Reday mode" 4 " NOC cancel mode" 3 " CP Active-Control mode" 2 " CP Reday mode" 1 " CP cancel mode" 0 " No display mode" ;
VAL_ 906 IDCU_12Rmninfo 79 " Reserved" 78 " Reserved" 77 " Reserved" 76 " Reserved" 75 " Reserved" 74 " Reserved" 73 " Reserved" 72 " Reserved" 71 " Reserved" 70 " Reserved" 69 " Reserved" 68 " Reserved" 67 " Reserved" 66 " Reserved" 65 " Reserved" 64 " Reserved" 63 " Reserved" 62 " Reserved" 61 " Reserved" 60 " Reserved" 59 " Reserved" 58 " Reserved" 57 " Reserved" 56 " Reserved" 55 "Reserved" 54 " Reserved" 53 " Reserved" 52 "Reserved" 51 "Reserved" 50 "Reserved" 49 "Reserved" 48 "Reserved" 47 "DCLC is right condition not meeted to left" 46 "CP is active" 45 "ACC is active" 44 " Confirm to change to turn to right lane" 43 " Confirm to change to turn to left lane" 42 " Longitudinal override info" 41 " ELK is in error mode" 40 " LDP is in error mode" 39 " CP is in error mode" 38 " FCW is switched on" 37 " FCW is switched off " 36 " lateral override info" 35 " NOC is changing to turn to right lane" 34 " NOC is changing to turn to left lane" 33 " NOC is going to change to turn to Right lane" 32 " NOC is going to change to turn to left lane" 31 " NOC is going to entrance ramp" 30 " FCW is in error mode" 29 " ACC is in error mode" 28 " AEB is in error mode " 27 " AEB is switched on" 26 " AEB is switched off" 25 " LDW is in error mode" 24 " BSD is in error mode" 23 " Not take over after long time" 22 " Take over info Level3" 21 " Take over info Level1" 20 " Take over info Level1" 19 " NOC is going to exit soon" 18 " DCLC condition not meeted" 17 " Unable to change lane as vehicle speed limit" 16 " unable to active CP" 15 " CP is cancelled" 14 " Radar Error ADAS not available" 13 " Camera Error ADAS not available" 12 " ACC is stand-wait" 11 " Drive Away Info Active" 10 " FCW is active" 9 " Unable to active FCW" 8 " Radar is in error mode" 7 " Camera is in error mode" 6 " Camera is covered" 5 " Radar is covered" 4 "AEB is active" 3 " unable to active AEB" 2 " unable to active ACC" 1 "ACC is cancelled" 0 "No display" ;
VAL_ 903 FCM_FRM_6_AEBMode 3 " Failure mode" 2 " Active mode" 1 " On mode" 0 " OFF mode" ;
VAL_ 903 FCM_FRM_6_FCWMode 3 " Failure mode" 2 " Active mode" 1 " On mode" 0 " OFF mode" ;
VAL_ 903 FCM_FRM_6_TakeOverReq 1 " Requst" 0 " No Requst" ;
VAL_ 903 FCM_FRM_6_FCW_preWarning 1 " Warning" 0 " No warning" ;
VAL_ 903 FCM_FRM_6_DistanceWarning 1 " Warning" 0 " No warning" ;
VAL_ 903 FCM_FRM_6_DrvrCfmSCFDispFb 1 " confirmed" 0 " not confirmed" ;
VAL_ 903 FCM_FRM_6_SCF_SpdLimUnit 3 " Reserved" 2 " Reserved" 1 " MPH" 0 " KMH" ;
VAL_ 903 FCM_FRM_6_SCF_SpdLimSts 7 " Reserved" 6 " Reserved" 5 " Reserved" 4 " IREVERSIBLE_FAILURE" 3 " REVERSIBLE_FAILURE" 2 " ACTIVE" 1 " STANDBY" 0 " OFF" ;
VAL_ 903 FCM_FRM_6_SCF_PopoverReq 1 " Driver confirm Request" 0 " No Request" ;
VAL_ 903 FCM_FRM_6_TimeGapSetICM 7 " Reserved" 6 " Reserved" 5 " TauGap_5" 4 " TauGap_4" 3 " TauGap_3" 2 " TauGap_2" 1 " TauGap_1" 0 " No Display" ;
VAL_ 903 FCM_FRM_6_ACCMode 15 " Reserved" 14 " Reserved" 13 " Reserved" 12 " Reserved" 11 " Reserved" 10 " Reserved" 9 " Failure mode" 8 " Reserved" 7 " Override" 6 " Stand-wait" 5 " Stand-active" 4 "Brake-Only mode" 3 " Active-Control mode" 2 " Ready mode" 1 " Passive mode" 0 " Initial Mode" ;
VAL_ 903 FCM_FRM_6_TextinfoWarn 15 " Reserved" 14 " Reserved" 13 " Reserved" 12 " Reserved" 11 " Reserved" 10 " Reserved" 9 " Reserved" 8 " Reserved" 7 " Reserved" 6 " Radar is in error mode" 5 " FCW is in error mode" 4 " Radar is covered" 3 " AEB is in error mode " 2 " ACC is in error mode" 1 " Driver take over" 0 " No Display" ;
VAL_ 903 FCM_FRM_6_Textinfo_Info 15 " Reserved" 14 " Reserved" 13 " Reserved" 12 " FCW is active" 11 " Unable to active FCW" 10 " FCW is switched on" 9 " FCW is switched off " 8 " AEB is active" 7 " Unable to switched on AEB" 6 " AEB is switched on" 5 " AEB is switched off" 4 " Drive Away Information Active" 3 " ACC is stand-wait" 2 " Unable to active ACC" 1 " ACC is cancelled" 0 " No Display" ;
VAL_ 1020 FCM_10_ELKIntvMod 7 " Reserved" 6 " Reserved" 5 " Reserved" 4 " Reserved" 3 " ELK Overtaking" 2 " ELK Oncoming" 1 " ELK Road Edge or Solid Line" 0 " Not active" ;
VAL_ 1020 FCM_10_WarnModSts 3 " voice and shock" 2 " only shock " 1 " only voice" 0 " Not active" ;
VAL_ 1020 FCM_10_SLAONOFFSts 3 " Reserved" 2 " OFF" 1 " ON" 0 " Not active" ;
VAL_ 1020 FCM_10_TJAICAExitTextInfoSts 3 " Reserved" 2 " OFF" 1 " ON" 0 " Not active" ;
VAL_ 1020 FCM_10_LDPTJAELKTakeoverReq 3 " Suppressed" 2 " Take Over Safty" 1 " Take Over Warning" 0 " Not Active" ;
VAL_ 1020 FCM_10_TJAICAEnaRcmend 1 " Demand" 0 " No demand" ;
VAL_ 1020 FCM_10_TJAICATextinfo 7 " Reserved" 6 " TJA/ICA is exit reminder" 5 " TJA/ICA is in error mode" 4 " TJA/ICA is active" 3 " Unable to active TJA/ICA" 2 " TJA/ICA is switched on" 1 " TJA/ICA is switched off" 0 " No display" ;
VAL_ 1020 FCM_10_TSINoParkWarn 1 " Active" 0 " Not Active" ;
VAL_ 1020 FCM_10_ELKSysSts 7 " Reserved" 6 " Reserved" 5 " Reserved" 4 " Fault" 3 " Active_startup " 2 " Active_standby" 1 " Suppressed" 0 " OFF" ;
VAL_ 1020 FCM_10_LDWSysSts 7 " Reserved" 6 " Reserved" 5 " Reserved" 4 " Fault" 3 " Active_startup " 2 " Active_standby" 1 " Suppressed" 0 " OFF" ;
VAL_ 1020 FCM_10_LDPSysSts 7 " Reserved" 6 " Reserved" 5 " Reserved" 4 " Fault" 3 " Active_startup " 2 " Active_standby" 1 " Suppressed" 0 " OFF" ;
VAL_ 1020 FCM_10_TLITrfcLi 3 " Red" 2 " Yellow" 1 " Green" 0 " No Display" ;
VAL_ 1020 FCM_10_TSISgnLongStayDisp 15 " Reserved" 14 " Reserved" 13 " Reserved" 12 " Reserved" 11 " Reserved" 10 " Reserved" 9 " Reserved" 8 " Malaysia no overtaking" 7 " Australian No parking" 6 " Australian prohibiting standing and parking" 5 " Australian no overtaking" 4 " Prohibiting Standing And Parking" 3 " No Parking" 2 " End Of No Overtaking" 1 " No Overtaking" 0 " No Display" ;
VAL_ 1020 FCM_10_TSISgnForb 15 " Reserved" 14 " Reserved" 13 " Reserved" 12 " Reserved" 11 " Reserved" 10 " Reserved" 9 " Reserved" 8 " Australian prohibiting U-turning" 7 " Australian prohibiting turning right" 6 " Australian prohibiting turning left" 5 " No entry" 4 " Prohibiting Motor Vehicle Entering" 3 " Prohibiting U-turning" 2 " Prohibiting turning right" 1 " Prohibiting turning left" 0 " No Display" ;
VAL_ 1020 FCM_10_TSISgnGiWay 15 " Reserved" 14 " Reserved" 13 " Reserved" 12 " Reserved" 11 " Malaysia stop sign" 10 " Australian stop sign" 9 " Australian yield sign2" 8 " Australian yield sign1" 7 " Australian watch for pedestrians" 6 " Yield Sign" 5 " Stop Sign" 4 " Warn Merger" 3 " Warn Road Work" 2 " Warn Kids" 1 " Watch For Pedestrians " 0 " No Display" ;
VAL_ 1020 FCM_10_TLISysSts 3 " Fault" 2 " Active" 1 " Standby" 0 " OFF" ;
VAL_ 1020 FCM_10_TSISysSts 3 " Reserved" 2 " Fault" 1 " On" 0 " OFF" ;
VAL_ 1018 FCM_FRM_9_RiObjTyp 15 " Reserved" 14 " Reserved" 13 " Reserved" 12 " Reserved" 11 " Reserved" 10 " Reserved" 9 " Reserved" 8 " Reserved" 7 " Reserved" 6 " Bus" 5 " Cyclist" 4 " Pedestrian" 3 " Motorcycle" 2 " Truck" 1 " Car" 0 " No type" ;
VAL_ 1018 FCM_FRM_9_RiObjID 1 " Valid" 0 " Invalid" ;
VAL_ 1018 FCM_FRM_9_LeObjTyp 15 " Reserved" 14 " Reserved" 13 " Reserved" 12 " Reserved" 11 " Reserved" 10 " Reserved" 9 " Reserved" 8 " Reserved" 7 " Reserved" 6 " Bus" 5 " Cyclist" 4 " Pedestrian" 3 " Motorcycle" 2 " Truck" 1 " Car" 0 " No type" ;
VAL_ 1018 FCM_FRM_9_LeObjID 1 " Valid" 0 " Invalid" ;
VAL_ 1005 FCM_FRM_8_FrntFarObjTyp 15 " Reserved" 14 " Reserved" 13 " Reserved" 12 " Reserved" 11 " Reserved" 10 " Reserved" 9 " Reserved" 8 " Reserved" 7 " Reserved" 6 " Bus" 5 " Cyclist" 4 " Pedestrian" 3 " Motorcycle" 2 " Truck" 1 " Car" 0 " No type" ;
VAL_ 1005 FCM_FRM_8_FrntFarObjID 1 " Valid" 0 " Invalid" ;
VAL_ 1005 FCM_FRM_8_ACCObjTyp 15 " Reserved" 14 " Reserved" 13 " Reserved" 12 " Reserved" 11 " Reserved" 10 " Reserved" 9 " Reserved" 8 " Reserved" 7 " Reserved" 6 " Bus" 5 " Cyclist" 4 " Pedestrian" 3 " Motorcycle" 2 " Truck" 1 " Car" 0 " No type" ;
VAL_ 1005 FCM_FRM_8_ACCObjID 1 " Valid" 0 " Invalid" ;
VAL_ 990 FCM_7_NeborRiLineTyp 3 " Type_Dashed_Line" 2 " Type_Solid_Line" 1 " Type_Unknown" 0 " No display" ;
VAL_ 990 FCM_7_NeborRiLineColor 3 " Color_Yellow" 2 " Color_White" 1 " Color_Unknown" 0 " No display" ;
VAL_ 990 FCM_7_NeborRiLineID 1 " Valid" 0 " Invalid" ;
VAL_ 990 FCM_7_NeborLeLineTyp 3 " Type_Dashed_Line" 2 " Type_Solid_Line" 1 " Type_Unknown" 0 " No display" ;
VAL_ 990 FCM_7_NeborLeLineColor 3 " Color_Yellow" 2 " Color_White" 1 " Color_Unknown" 0 " No display" ;
VAL_ 990 FCM_7_NeborLeLineID 1 " Valid" 0 " Invalid" ;
VAL_ 988 FCM_6_EgoRiLineTyp 3 " Type_Dashed_Line" 2 " Type_Solid_Line" 1 " Type_Unknown" 0 " No display" ;
VAL_ 988 FCM_6_EgoRiLineColor 3 " Color_Yellow" 2 " Color_White" 1 " Color_Unknown" 0 " No display" ;
VAL_ 988 FCM_6_EgoRiLineID 1 " Valid" 0 " Invalid" ;
VAL_ 988 FCM_6_EgoLeLineTyp 3 " Type_Dashed_Line" 2 " Type_Solid_Line" 1 " Type_Unknown" 0 " No display" ;
VAL_ 988 FCM_6_EgoLeLineColor 3 " Color_Yellow" 2 " Color_White" 1 " Color_Unknown" 0 " No display" ;
VAL_ 988 FCM_6_EgoLeLineID 1 " Valid" 0 " Invalid" ;
VAL_ 775 FCM_2_SLASpdlimitUnits 3 " Reserved" 2 " MPH" 1 " KMH" 0 " Unknown" ;
VAL_ 775 TJA_ICA_mode 7 " Reserved" 6 " Reserved" 5 " Reserved" 4 " Reserved" 3 " Failure mode" 2 " Active mode" 1 " Standby mode" 0 " OFF mode" ;
VAL_ 775 Camera_textinfo 3 " Reserved" 2 " Camera blocked" 1 " Camera failure" 0 " Camera normal" ;
VAL_ 775 FCM_2_SpdLimtyp 3 " Reserved" 2 " National SpeedLimit" 1 " Conditional Unconfirmed" 0 " No Conditional" ;
VAL_ 775 SLASpdlimitWarning 1 " Active" 0 " Not Active" ;
VAL_ 775 SLASpdlimit 255 " Reserved" 254 " Reserved" 253 " Reserved" 252 " Reserved" 251 " Reserved" 250 " Reserved" 249 " Reserved" 248 " Reserved" 247 " Reserved" 246 " Reserved" 245 " Reserved" 244 " Reserved" 243 " Reserved" 242 " Reserved" 241 " Reserved" 240 " Reserved" 239 " Reserved" 238 " Reserved" 237 " Reserved" 236 " Reserved" 235 " Reserved" 234 " Reserved" 233 " Reserved" 232 " Reserved" 231 " Reserved" 230 " Reserved" 229 " Reserved" 228 " Reserved" 227 " Reserved" 226 " Reserved" 225 " Reserved" 224 " Reserved" 223 " Reserved" 222 " Reserved" 221 " Reserved" 220 " Reserved" 219 " Reserved" 218 " Reserved" 217 " Reserved" 216 " Reserved" 215 " Reserved" 214 " Reserved" 213 " Reserved" 212 " Reserved" 211 " Reserved" 210 " Reserved" 209 " Reserved" 208 " Reserved" 207 " Reserved" 206 " Reserved" 205 " Reserved" 204 " Reserved" 203 " Reserved" 202 " Reserved" 201 " Reserved" 200 " Reserved" 199 " Reserved" 198 " Reserved" 197 " Reserved" 196 " Reserved" 195 " Reserved" 194 " Reserved" 193 " Reserved" 192 " Reserved" 191 " Reserved" 190 " Reserved" 189 " Reserved" 188 " Reserved" 187 " Reserved" 186 " Reserved" 185 " Reserved" 184 " Reserved" 183 " Reserved" 182 " Reserved" 181 " Reserved" 180 " Reserved" 179 " Reserved" 178 " Reserved" 177 " Reserved" 176 " Reserved" 175 " Reserved" 174 " Reserved" 173 " Reserved" 172 " Reserved" 171 " Reserved" 170 " Reserved" 169 " Reserved" 168 " Reserved" 167 " Reserved" 166 " Reserved" 165 " Reserved" 164 " Reserved" 163 " Reserved" 162 " Reserved" 161 " Reserved" 160 " Reserved" 159 " Reserved" 158 " Reserved" 157 " Reserved" 156 " Reserved" 155 " Reserved" 154 " Reserved" 153 " Reserved" 152 " Reserved" 151 " Reserved" 150 " Reserved" 149 " Reserved" 148 " Reserved" 147 " Reserved" 146 " Reserved" 145 " Reserved" 144 " Reserved" 143 " Reserved" 142 " Reserved" 141 " Reserved" 140 " Reserved" 139 " Reserved" 138 " Reserved" 137 " Reserved" 136 " Reserved" 135 " Reserved" 134 " Reserved" 133 " Reserved" 132 " Reserved" 131 " Reserved" 130 " Reserved" 129 " Reserved" 128 " Reserved" 127 " Reserved" 126 " Reserved" 125 " Reserved" 124 " Reserved" 123 " Reserved" 122 " Reserved" 121 " Reserved" 120 " Reserved" 119 " Reserved" 118 " Reserved" 117 " Reserved" 116 " Reserved" 115 " Reserved" 114 " Reserved" 113 " Reserved" 112 " Reserved" 111 " Reserved" 110 " Reserved" 109 " Reserved" 108 " Reserved" 107 " Reserved" 106 " Reserved" 105 " Reserved" 104 " Reserved" 103 " Reserved" 102 " Reserved" 101 " Reserved" 100 " Reserved" 99 " Reserved" 98 " Reserved" 97 " Reserved" 96 " Reserved" 95 " Reserved" 94 " Reserved" 93 " Reserved" 92 " Reserved" 91 " Reserved" 90 " Reserved" 89 " Reserved" 88 " Reserved" 87 " Reserved" 86 " Reserved" 85 " Reserved" 84 " Reserved" 83 " Reserved" 82 " Reserved" 81 " Reserved" 80 " Reserved" 79 " Reserved" 78 " Reserved" 77 " Reserved" 76 " Reserved" 75 " Reserved" 74 " Reserved" 73 " Reserved" 72 " Reserved" 71 " Reserved" 70 " Reserved" 69 " Reserved" 68 " Reserved" 67 " Reserved" 66 " Reserved" 65 " Reserved" 64 " Reserved" 63 " Reserved" 62 " Reserved" 61 " Reserved" 60 " Reserved" 59 " Reserved" 58 " Reserved" 57 " Reserved" 56 " Reserved" 55 " Reserved" 54 " Reserved" 53 " Reserved" 52 " Reserved" 51 " Reserved" 50 " Reserved" 49 " Reserved" 48 " Reserved" 47 " Reserved" 46 " Reserved" 45 " Reserved" 44 " Reserved" 43 " Reserved" 42 " Reserved" 41 " Reserved" 40 " Reserved" 39 " Reserved" 38 " Reserved" 37 " Reserved" 36 " Reserved" 35 " Reserved" 34 " Reserved" 33 " Reserved" 32 " Reserved" 31 " Reserved" 30 " Reserved" 29 " Reserved" 28 " Reserved" 27 " SPL 130" 26 " SPL 125" 25 " SPL 120" 24 " SPL 115" 23 " SPL 110" 22 " SPL 105" 21 " SPL 100" 20 " SPL 95" 19 " SPL 90" 18 " SPL 85" 17 " SPL 80" 16 " SPL 75" 15 " SPL 70" 14 " SPL 65" 13 " SPL 60" 12 " SPL 55" 11 " SPL 50" 10 " SPL 45" 9 " SPL 40" 8 " SPL 35" 7 " SPL 30" 6 " SPL 25" 5 " SPL 20" 4 " SPL 15" 3 " SPL10" 2 " SPL 5" 1 " SPL Cancelled" 0 " No Display" ;
VAL_ 775 FCM_2_SCFSpdlimWarn 1 " Active" 0 " Not Active" ;
VAL_ 775 SLAState 7 " Reserved" 6 " Reserved" 5 " Reserved" 4 " Defect" 3 " Navigation only mode" 2 " Vision mode" 1 " Fusion mode" 0 " Off" ;
VAL_ 775 LDW_ELK_TJA_LDPRightVisuali 3 " Warning" 2 " Intervention" 1 " Line tracking" 0 " No display" ;
VAL_ 775 LDW_ELK_TJA_LDPLeftVisuali 3 " Warning" 2 " Intervention" 1 " Line tracking" 0 " No display" ;
VAL_ 775 HMA_HighbeamReq 1 " High beam request" 0 " No request" ;
VAL_ 775 HMA_Status 7 " Reserved" 6 " Reserved" 5 " Reserved" 4 " Reserved" 3 " Fault" 2 " Active" 1 " Standby" 0 " Off" ;
VAL_ 896 EPS_EOTLearning_Sts 1 " Not Learnt" 0 " Learnt" ;
VAL_ 896 EPSSteeringAngleCalibrationSts 1 " No calibration or no initialization" 0 " Calibration is fine" ;
VAL_ 896 EPSFailSts 1 " Fail present" 0 " Not present" ;
VAL_ 1270 Yellowwarning 3 " Not used" 2 " Lamp on" 1 " Lamp flash" 0 " Lamp off" ;
VAL_ 1270 Redwarning 3 " Not used" 2 " Lamp on" 1 " Lamp flash" 0 " Lamp off" ;
VAL_ 1270 RWUActive 1 " Active" 0 " Not Active" ;
VAL_ 1270 EPBStatus 7 " Not Used" 6 " Not Used" 5 " ErrorApplied" 4 " Unknown" 3 " Applying" 2 " Releasing" 1 " Applied" 0 " Released" ;
VAL_ 1270 EPBWarningMessage 7 " Not Used" 6 " Not Used" 5 " Not Used" 4 " Not Used" 3 " Large slope parking" 2 " Close the LHF door" 1 " Press the brake pedal first,then release the EPB button" 0 " Off" ;
VAL_ 640 EngineSts 0 " Not Run" 1 " Run" ;
VAL_ 640 GearReduceIndication 0 " Not active" 1 " Active" ;
VAL_ 640 GearRaiseIndication 0 " Not active" 1 " Active" ;
VAL_ 640 TargetGearPosition 7 " Invalid" 6 " 6th gear" 5 " 5th gear" 4 " 4th gear" 3 " 3rd gear" 2 " 2nd gear" 1 " 1st gear" ;
VAL_ 640 SSMStatus 6 " Auto Stopping" 5 " Operation" 4 " Engine Restart" 3 " Starter Restart" 2 " Stopped" 1 " Standby" 0 " Reset/Not Implemented" ;
VAL_ 640 EPCSts 0 " Off" 1 " Active" ;
VAL_ 640 EngineSpeedValidData 1 " Not valid" 0 " Valid" ;
VAL_ 640 FuelRollingCounterValidData 1 " Not valid" 0 " Valid" ;
VAL_ 640 ISS_Sts_GS 30 " Reserved" 29 " Reserved" 28 " Reserved" 27 " Reserved" 26 " Reserved" 25 " Reserved" 24 " Reserved" 23 " Reserved" 22 " Reserved" 21 " Reserved" 20 " Reserved" 19 " MHEV_AlarmFault " 18 " ISS_TurnOn" 17 " ISS_TurnOff " 16 " ISS_AlarmFault " 15 " ISS_AlarmStartByHand              " 14 " ISS_AlarmNeutral" 13 " ISS_ExitInfo2" 12 " ISS_ExitInfo" 11 " ISS_OnSeatCheck " 10 " ISS_NoStartBelt" 9 " ISS_AutoStart" 8 " ISS_NoStopBrake" 7 " ISS_NoStopHood " 6 " ISS_NoStopDoor" 5 " ISS_NoStopAC " 4 " ISS_NoStopBelt " 3 " ISS_AutoStop " 2 " ISS_StopEnable " 1 " ISS_EOL" 0 " ISS_DefaultOn                              " ;
VAL_ 640 CruiseControlStsForDisplay 3 " Cancel" 2 " Pre cruise (flash)" 1 " Inserted" 0 " Not inserted" ;
VAL_ 640 ECSControlSts 1 " Heating£¬lamp flash" 0 " No heating£¬lamp off" ;
VAL_ 640 EngineCoolantTempertureFailSts 1 " Fail Present" 0 " Fail Not Present" ;
VAL_ 640 MILSts 3 " Not used" 2 " Active" 1 " Not used" 0 " Off" ;
VAL_ 640 IEMSts 0 " Lamp Off" 1 " Lamp On" ;
VAL_ 640 GPFWarning 3 " Reserved" 2 " GPF Overlimited" 1 " GPF Full" 0 " No GPF warning" ;
VAL_ 1232 Energy_Flow_Sts 3 " EnFlow Discharge" 2 " EnFlow EngCharge" 1 " EnFlow RegCharge" 0 " EnFlow OFF" ;
VAL_ 1232 Battery_Sts 2 " Batt_Charge" 1 " Batt_Boost" 0 " Batt_Idle" ;
VAL_ 1232 Battery_Temp_Sts 2 " Batt_Relay Open" 1 " Batt_Over Hot" 0 " Batt_Normal" ;
VAL_ 1146 AllWarningInfo 7 " Reserved" 6 " Reserved" 5 " Reserved" 4 " Please check the position of the gear shift" 3 " Third grade failure of gear shift mechanism(Reserved)" 2 " Second grade failure of gear shift mechanism" 1 " First grade failure of gear shift mechanism" 0 " No error" ;
VAL_ 1158 AWDoutserviceDispRq 3 " Reserved" 2 " Permanent out service" 1 " Temporary out service" 0 " Not Active" ;
VAL_ 1095 AFS_FaultSts 1 " Fault" 0 " Not Fault" ;
VAL_ 704 CDPFailSts 0 " Fail not present" 1 " Fail present (lamp on)" ;
VAL_ 704 AVHFailSts 0 " Fail not present" 1 " Fail present (lamp on)" ;
VAL_ 704 AVHSts 3 " Not Used" 2 " Active" 1 " Standby" 0 " Off" ;
VAL_ 704 HDCFailSts 0 " Fail not present" 1 " Fail present (lamp on)" ;
VAL_ 704 HDCCtrlSts 3 " Not used" 2 " On active braking" 1 " flash not active braking" 0 " OFF" ;
VAL_ 704 DiagnosticSessionSts 0 " Not active" 1 " Active" ;
VAL_ 704 VehicleSpeedVSOSigValidData 1 " Not valid" 0 " Valid" ;
VAL_ 704 CDPActive 0 " Not active" 1 " Active" ;
VAL_ 704 ESPSwitchStatus 1 " Disable" 0 " On" ;
VAL_ 704 HHCFailSts 0 " Fail not present" 1 " Fail present (lamp on)" ;
VAL_ 704 VDCActive 0 " Not active" 1 " Active(blinking lamp)" ;
VAL_ 704 TCSActive 0 " Not active" 1 " Active(blinking lamp)" ;
VAL_ 704 VDCFailSts 0 " Fail not present" 1 " Fail present (lamp on)" ;
VAL_ 704 TCSFailSts 0 " Fail not present" 1 " Fail present (lamp on)" ;
VAL_ 704 EBDFailSts 0 " Fail not present" 1 " Fail present (lamp on)" ;
VAL_ 704 ABSFailSts 0 " Fail not present" 1 " Fail present (lamp on)" ;
VAL_ 704 AVHWarningMessage 1 " Fasten DriverSeatBelt and Close the LHF door" 0 " Off" ;
VAL_ 745 AEBdecAvailable 1 " Available" 0 " Not available" ;
VAL_ 745 AEBdecActive 1 " Active" 0 " Not active" ;
VAL_ 800 SecRowRBeltWarning 1 "Warning" 0 "No Warning" ;
VAL_ 800 SecRowMBeltWarning 1 "Warning" 0 "No Warning" ;
VAL_ 800 SecRowLBeltWarning 1 "Warning" 0 "No Warning" ;
VAL_ 800 ThdRowRBeltWarning 1 "Warning" 0 "No Warning" ;
VAL_ 800 ThdRowLBeltWarning 1 "Warning" 0 "No Warning" ;
VAL_ 800 PsngrSeatBeltWarning 3 " Not used" 2 " Warning" 1 " Reserve" 0 " Not warning" ;
VAL_ 800 AirBagFailSts 3 " Lamp on, but no warning information displaying on the LCD" 2 " Fail present, lamp on" 1 " Fail no present, lamp flashing" 0 " Fail no present, lamp off" ;
VAL_ 1556 ECUSPEC_AWAKE_ICM 1 " Active" 0 " Inactive" ;
VAL_ 1556 DIAGNOSTIC_AWAKE_ICM 1 " Active" 0 " Inactive" ;
VAL_ 1556 IGNITION_AWAKE_ICM 1 " Active" 0 " Inactive" ;
VAL_ 1556 NETWORK_AWAKE_ICM 1 " Active" 0 " Inactive" ;
VAL_ 1556 ECUSPEC_WAKEUP_ICM 1 " Active" 0 " Inactive" ;
VAL_ 1556 NETWORK_WAKEUP_ICM 1 " Active" 0 " Inactive" ;
VAL_ 1556 RESET_WAKEUP_ICM 1 " Active" 0 " Inactive" ;
VAL_ 1556 IGNITION_WAKEUP_ICM 1 " Active" 0 " Inactive" ;
VAL_ 1556 usrData0_ICM 254 " Not Used" 253 " Not Used" 252 " Not Used" 251 " Not Used" 250 " Not Used" 249 " Not Used" 248 " Not Used" 247 " Not Used" 246 " Not Used" 245 " Not Used" 244 " Not Used" 243 " Not Used" 242 " Not Used" 241 " Not Used" 240 " Not Used" 239 " Not Used" 238 " Not Used" 237 " Not Used" 236 " Not Used" 235 " Not Used" 234 " Not Used" 233 " Not Used" 232 " Not Used" 231 " Not Used" 230 " Not Used" 229 " Not Used" 228 " Not Used" 227 " Not Used" 226 " Not Used" 225 " Not Used" 224 " Not Used" 223 " Not Used" 222 " Not Used" 221 " Not Used" 220 " Not Used" 219 " Not Used" 218 " Not Used" 217 " Not Used" 216 " Not Used" 215 " Not Used" 214 " Not Used" 213 " Not Used" 212 " Not Used" 211 " Not Used" 210 " Not Used" 209 " Not Used" 208 " Not Used" 207 " Not Used" 206 " Not Used" 205 " Not Used" 204 " Not Used" 203 " Not Used" 202 " Not Used" 201 " Not Used" 200 " Not Used" 199 " Not Used" 198 " Not Used" 197 " Not Used" 196 " Not Used" 195 " Not Used" 194 " Not Used" 193 " Not Used" 192 " Not Used" 191 " Not Used" 190 " Not Used" 189 " Not Used" 188 " Not Used" 187 " Not Used" 186 " Not Used" 185 " Not Used" 184 " Not Used" 183 " Not Used" 182 " Not Used" 181 " Not Used" 180 " Not Used" 179 " Not Used" 178 " Not Used" 177 " Not Used" 176 " Not Used" 175 " Not Used" 174 " Not Used" 173 " Not Used" 172 " Not Used" 171 " Not Used" 170 " Not Used" 169 " Not Used" 168 " Not Used" 167 " Not Used" 166 " Not Used" 165 " Not Used" 164 " Not Used" 163 " Not Used" 162 " Not Used" 161 " Not Used" 160 " Not Used" 159 " Not Used" 158 " Not Used" 157 " Not Used" 156 " Not Used" 155 " Not Used" 154 " Not Used" 153 " Not Used" 152 " Not Used" 151 " Not Used" 150 " Not Used" 149 " Not Used" 148 " Not Used" 147 " Not Used" 146 " Not Used" 145 " Not Used" 144 " Not Used" 143 " Not Used" 142 " Not Used" 141 " Not Used" 140 " Not Used" 139 " Not Used" 138 " Not Used" 137 " Not Used" 136 " Not Used" 135 " Not Used" 134 " Not Used" 133 " Not Used" 132 " Not Used" 131 " Not Used" 130 " Not Used" 129 " Not Used" 128 " Not Used" 127 " Not Used" 126 " Not Used" 125 " Not Used" 124 " Not Used" 123 " Not Used" 122 " Not Used" 121 " Not Used" 120 " Not Used" 119 " Not Used" 118 " Not Used" 117 " Not Used" 116 " Not Used" 115 " Not Used" 114 " Not Used" 113 " Not Used" 112 " Not Used" 111 " Not Used" 110 " Not Used" 109 " Not Used" 108 " Not Used" 107 " Not Used" 106 " Not Used" 105 " Not Used" 104 " Not Used" 103 " Not Used" 102 " Not Used" 101 " Not Used" 100 " Not Used" 99 " Not Used" 98 " Not Used" 97 " Not Used" 96 " Not Used" 95 " Not Used" 94 " Not Used" 93 " Not Used" 92 " Not Used" 91 " Not Used" 90 " Not Used" 89 " Not Used" 88 " Not Used" 87 " Not Used" 86 " Not Used" 85 " Not Used" 84 " Not Used" 83 " Not Used" 82 " Not Used" 81 " Not Used" 80 " Not Used" 79 " Not Used" 78 " Not Used" 77 " Not Used" 76 " Not Used" 75 " Not Used" 74 " Not Used" 73 " Not Used" 72 " Not Used" 71 " Not Used" 70 " Not Used" 69 " Not Used" 68 " Not Used" 67 " Not Used" 66 " Not Used" 65 " Not Used" 64 " Not Used" 63 " Not Used" 62 " Not Used" 61 " Not Used" 60 " Not Used" 59 " Not Used" 58 " Not Used" 57 " Not Used" 56 " Not Used" 55 " Not Used" 54 " Not Used" 53 " Not Used" 52 " Not Used" 51 " Not Used" 50 " Not Used" 49 " Not Used" 48 " Not Used" 47 " Not Used" 46 " Not Used" 45 " Not Used" 44 " Not Used" 43 " Not Used" 42 " Not Used" 41 " Not Used" 40 " Not Used" 39 " Not Used" 38 " Not Used" 37 " Not Used" 36 " Not Used" 35 " Not Used" 34 " Not Used" 33 " Not Used" 32 " Not Used" 31 " Not Used" 30 " Not Used" 29 " Not Used" 28 " Not Used" 27 " Not Used" 26 " Not Used" 25 " Not Used" 24 " Not Used" 23 " Not Used" 22 " Not Used" 21 " Not Used" 20 " Not Used" 19 " Not Used" 18 " Not Used" 17 " Not Used" 16 " Not Used" 15 " Not Used" 14 " Not Used" 13 " Not Used" 12 " Not Used" 11 " Not Used" 10 " Not Used" 9 " Not Used" 8 " Not Used" 7 " Not Used" 6 " Not Used" 5 " Not Used" 4 " Not Used" 3 " Not Used" 2 " Not Used" 1 " Not Used" 255 " User data not used" 0 " User data for current vehicle" ;
VAL_ 1556 RMR_ICM 1 " Active" 0 " Inactive" ;
VAL_ 1152 RemoteStartSts 2 " Remote start mode" 1 " Normal start mode" 0 " No start" ;
VAL_ 1152 SmartSystemWarning4_3 1 " ACC switching OFF while Gear box not in P position" 0 " Normal" ;
VAL_ 1152 SmartSystemWarning2_0 1 " Engine start operation attempted when identifier has not been detected in the vehicle" 0 " Normal" ;
VAL_ 1152 SmartSystemWarning2_2 1 " Identifier is out of vehicle range when vehicle starts running" 0 " Normal" ;
VAL_ 1152 SmartSystemWarning1_0 1 " Driver Door opening while ACC is ON and IG is OFF" 0 " Normal" ;
VAL_ 1152 SmartSystemWarning1_1 1 " Identifier is out of vehicle (detection performed on driver door closing), in P range when IG = ON or ACC = ON" 0 " Normal" ;
VAL_ 1152 SmartSystemWarning1_3 1 " Lock (RKE or smart) performed while Identifier in the vehicle" 0 " Normal" ;
VAL_ 1152 SmartSystemWarning3_1 1 " Identifier low battery detected" 0 " Normal" ;
VAL_ 1152 SmartSystemWarning3_2 1 " Engine start not possible if gear box not in P or N position" 0 " Normal" ;
VAL_ 1152 SmartSystemWarning4_2 1 " Engine start attempted without pressing clutch/brake pedal" 0 " Normal " ;
VAL_ 1219 PAS_1_DriverDoorSIllSts 1 "  Active" 0 " Not Active" ;
VAL_ 1025 ESCLNotLocked 3 "Invalid" 2 "Reserved" 1 "Active" 0 "Not active" ;
VAL_ 1025 ESCLUnlockJamming 3 "Invalid" 2 "Reserved" 1 "Active" 0 "Not active" ;
VAL_ 1025 ESCLFunctionFailure 3 "Invalid" 2 "Reserved" 1 "Active" 0 "Not active" ;
VAL_ 1025 ESCLCriticalFailure 3 "Invalid" 2 "Reserved" 1 "Active" 0 "Not active" ;
VAL_ 533 ICM_8_FrntRadarSwt 1 " Active" 0 " Not Active" ;
VAL_ 533 ICM_ESPSwitchCmd 1 " Active" 0 " Not Active" ;
VAL_ 533 ICM_ISS_Switch 1 " Active" 0 " Not Active" ;
VAL_ 533 SetICMAlarm 63 " Reserved" 62 " Reserved" 61 " Reserved" 60 " Reserved" 59 " Reserved" 58 " Reserved" 57 " Reserved" 56 " Reserved" 55 " Reserved" 54 " Reserved" 53 " Reserved" 52 " Reserved" 51 " Reserved" 50 " Reserved" 49 " Reserved" 48 " Reserved" 41 " Reserved" 40 " Reserved" 39 " Reserved" 38 " Reserved" 37 " Reserved" 36 " Reserved" 35 " Reserved" 34 " Reserved" 33 " Reserved" 32 " Reserved" 31 " Reserved" 30 " Reserved" 29 " Reserved" 28 " Reserved" 27 " Reserved" 26 " Reserved" 25 " Reserved" 24 " Reserved" 23 " Reserved" 22 " Reserved" 21 " Reserved" 20 "CHIME OFF" 19 "BSD_L+R" 18 "BSD_R only" 17 "BSD_L only" 16 "PDC_all" 15 "PDC_FR+RL+RR" 14 "PDC_FL+RL+RR" 13 "PDC_FL+FR+RR" 12 "PDC_FL+FR+RL" 11 "PDC_RL+RR" 10 "PDC_FR+RR" 9 "PDC_FR+RL" 8 " PDC_FL+RR" 7 " PDC_FL+RL" 6 " PDC_FL+FR" 5 " PDC_RR only " 4 " PDC_RL only " 3 " PDC_FR only" 2 " PDC_FL only" 1 " other CHIME" 0 " Not Active" ;
VAL_ 1066 TotalOdometer_km_OBDValidData 1 " Not valid" 0 " Valid" ;
VAL_ 1066 TotODOMtrBkpEna 1 "Enable" 0 "Disable" ;
VAL_ 1066 DrivermodeReq 3 " Reserved" 2 " Sport" 1 " Normal" 0 " Eco" ;
VAL_ 647 ICM_DVDAudibleAlarmStyle 3 "Not Used" 2 "Cycle" 1 "Once" 0 "Not active" ;
VAL_ 647 ICM_DVDAudibleAlarm 15 "Reserved" 14 "Reserved" 13 "Reserved" 12 "Reserved" 11 "Key Tone" 10 "Door Open" 9 "ODO" 8 "Turn Tock    " 7 "Turn Tick                                                                  " 6 "Seatbelt" 5 "Safty" 4 "Warning" 3 "Info" 2 "FWC" 1 "PDC" 0 "Not active" ;
VAL_ 647 BrakeFluidWarning 1 " Warning" 0 " Not Warning" ;
VAL_ 647 ACC_Kilometre_Mile 1 " mile" 0 " kilometer" ;
VAL_ 647 DriverSeatBeltSwitchQbit 1 " invalid" 0 " valid" ;
VAL_ 647 ICM_5_DriverSeatBeltSwitch 1 " Unfasten" 0 " Fasten" ;
VAL_ 647 CTP_DriveModeSet 1 " Active" 0 " Not Active                                   " ;
VAL_ 647 ICM_5_AlrmVolCtrl 3 " Not Used" 2 " Down" 1 " UP" 0 " Not active" ;
VAL_ 647 ICM_5_BackLiBriAdjmt 3 " Not Used" 2 " Down" 1 " UP" 0 " Not active" ;
VAL_ 647 AverageFuelConsumption50 510 " Not Used" 509 " Not Used" 508 " Not Used" 507 " Not Used" 506 " Not Used" 505 " Not Used" 504 " Not Used" 503 " Not Used" 502 " Not Used" 501 " Not Used" ;
VAL_ 647 FuelValidData 1 "Not valid" 0 "Valid" ;
VAL_ 647 FuelOutOfRange 1 " Out Of Range" 0 " Fail Not Present " ;
VAL_ 647 FuelShortPower 1 " Short Power" 0 " Fail Not Present " ;
VAL_ 647 FuelShortGround 1 " Short Ground" 0 " Fail Not Present " ;
VAL_ 647 HandBrakeSystemStsValidData 1 "Not valid" 0 "Valid" ;
VAL_ 647 HandBrakeSystemSts 7 "Not Used" 6 "Not Used" 5 "ErrorApplied" 4 "Unknown" 3 "Applying" 2 "Releasing" 1 "Applied" 0 "Released" ;
VAL_ 1107 FatigureDrivingWarning 1 " Warning" 0 " Not Warning" ;
VAL_ 1107 ICM_BrightnessLevel 15 " Not Used" 14 " Not Used" 13 " Not Used" 12 " Not Used" 11 " Not Used" 10 " Level 10" 9 " Level 9" 8 " Level 8" 7 " Level 7" 6 " Level 6" 5 " Level 5" 4 " Level 4" 3 " Level 3" 2 " Level 2" 1 " Level 1 " 0 " Not Active" ;
VAL_ 1107 MaintainWarning 1 " Warning" 0 " Not Warning" ;
VAL_ 1107 LowFuleWarning 1 " Warning" 0 " Not Warning" ;
VAL_ 1107 FatigureDrivingTime 15 " Reserved" 14 " Reserved" 13 " Reserved" 12 " Reserved" 11 " Reserved" 10 " Reserved" 9 " Reserved" 8 " Reserved" 7 " 4 hours " 6 " 3.5 hours" 5 " 3 hours" 4 " 2.5 hours" 3 " 2 hours" 2 " 1.5 hours" 1 " 1 hour" 0 " Not Active" ;
VAL_ 1106 FrontSeatBeltAlarmLight 1 " Light ON" 0 " Light OFF" ;
VAL_ 1106 ICM_2_OverSpeedValue 42 " 170km/h" 41 " 165km/h" 40 " 160km/h" 39 " 155km/h" 38 " 150km/h" 37 " 145km/h" 36 " 140km/h" 35 " 135km/h" 34 " 80 mph" 33 " 75 mph" 32 " 70 mph" 31 " 65 mph" 30 " 60 mph" 29 " 55 mph" 28 " 50 mph" 27 " 45 mph" 26 " 40 mph" 25 " 35 mph" 24 " 30mph" 23 " 25mph" 22 " 20mph" 21 " 130km/h" 20 " 125km/h" 19 " 120km/h" 18 " 115km/h" 17 " 110km/h" 16 " 105km/h" 15 " 100km/h" 14 " 95km/h" 13 " 90km/h" 12 " 85km/h" 11 " 80km/h" 10 " 75km/h" 9 " 70km/h" 8 " 65km/h" 7 " 60km/h" 6 " 55km/h" 5 " 50km/h" 4 " 45km/h" 3 " 40km/h" 2 " 35km/h" 1 " 30km/h" 0 " Not Active" ;
VAL_ 1106 QDashACCFail 3 " not defined" 2 " irreversible error" 1 " reversible error" 0 " no error" ;
VAL_ 1106 DISFail 1 " error" 0 " no error" ;
VAL_ 1106 ICM_2_LoWshLqdWarn 1 " Warning" 0 " Not Warning" ;
VAL_ 1106 BackLightLevel 15 " Reserved" 14 " Reserved" 13 " Reserved" 12 " Reserved" 11 " Reserved" 10 " Reserved" 9 " Level 10 " 8 " Level 9" 7 " Level 8" 6 " Level 7" 5 " Level 6 " 4 " Level 5" 3 " Level 4" 2 " Level 3" 1 " Level 2" 0 " Level 1" ;
VAL_ 1106 TemperatureUnit_ICM 1 " Fahrenheit(¨H)" 0 " Centigrade(¡æ)" ;
VAL_ 1106 AirBagLampFailSts 3 " BLINKING-not used / fault present when lamp blinking function is ON" 2 " ON-Fail present when lamp is switched ON" 1 " OFF-Fail present when lamp is switched OFF" 0 " ON/OFF-No Fail of any kind" ;
VAL_ 1072 EngineCoolantTempertureHighWarn 1 " Active" 0 " Not active" ;
VAL_ 1072 Reserved_HandBrakeSts 1 " Off" 0 " On" ;
VAL_ 1072 FuelLevelFailSts 1 " Fail Present" 0 " Fail Not Present" ;
VAL_ 1072 EngineOilPressureLowWarn 1 " Active" 0 " Not active" ;
VAL_ 1072 DriverSeatBeltSwitch 1 " Unfasten" 0 " Fasten" ;
VAL_ 1072 ECOModeSWSts 1 " Active" 0 " Not active" ;
VAL_ 1072 ICM_1_HandBrakeSystemSts 7 " Not Used" 6 " Not Used" 5 " ErrorApplied" 4 " Unknown" 3 " Applying" 2 " Releasing" 1 " Applied" 0 " Released" ;
VAL_ 1275 DCM_1_PwrDoorErr 1 " Error" 0 " Normal" ;
VAL_ 1275 DCM_1_RHRStallSts 1 " Stall" 0 " No stall" ;
VAL_ 1275 DCM_1_LHRStallSts 1 " Stall" 0 " No stall" ;
VAL_ 1275 DCM_1_PassStallSts 1 " Stall" 0 " No stall" ;
VAL_ 1275 DCM_1_DrvrStallSts 1 " Stall" 0 " No stall" ;
VAL_ 1224 BCM_RRPLMfailsts 1 " Failure" 0 " Normal" ;
VAL_ 1224 BCM_RRFLMfailsts 1 " Failure" 0 " Normal" ;
VAL_ 1224 BCM_RLPLMfailsts 1 " Failure" 0 " Normal" ;
VAL_ 1224 BCM_RLFLMfailsts 1 " Failure" 0 " Normal" ;
VAL_ 1224 BCM_RHMfailsts 1 " Failure" 0 " Normal" ;
VAL_ 1224 BCM_LHMfailsts 1 " Failure" 0 " Normal" ;
VAL_ 1224 ReFogLiFaildSts 1 " Failure" 0 " Normal" ;
VAL_ 1224 ReversinglampFaultSts 1 " Failure" 0 " Normal" ;
VAL_ 1224 BrakelampFaultSts 1 " Failure" 0 " Normal" ;
VAL_ 1224 FrntFogFaildSts 1 " Failure" 0 " Normal" ;
VAL_ 1224 DRLFaildSts 1 " Failure" 0 " Normal" ;
VAL_ 1224 BDM_21_RHTurnlightSts 1 " Failure" 0 " Normal" ;
VAL_ 1224 BDM_21_LHTurnlightSts 1 " Failure" 0 " Normal" ;
VAL_ 1224 ParkLiFaildSts 1 " Failure" 0 " Normal" ;
VAL_ 1224 LoBeamFaildSts 1 " Failure" 0 " Normal" ;
VAL_ 1224 HiBeamFaildSts 1 " Failure" 0 " Normal" ;
VAL_ 1514 NavigationInformation 1 "Present" 0 "Not present" ;
VAL_ 1514 SecondIntervalMaintainMileage 3 "10000km" 2 "8000km" 1 "5000km" 0 "Not present" ;
VAL_ 1514 OverSpeedWarningFunction 3 " 120km/h(China,3 beeps)" 2 " 120km/h(GSO)" 1 " 30~130km/h" 0 " No" ;
VAL_ 1514 Language 15 " Reserved" 14 " Reserved" 13 " Reserved" 12 " Reserved" 11 " Reserved" 10 " Reserved" 9 " Reserved" 8 " Reserved" 7 " Reserved" 6 " Spanish" 5 " Persian" 4 " Portuguese" 3 " Arabic" 2 " Russian" 1 " English" 0 " Chinese" ;
VAL_ 1514 LDW 1 " Present" 0 " Not Present" ;
VAL_ 1514 EngineFuelType 3 "Flex" 2 "CNG" 1 "Diesel" 0 "Gasoline" ;
VAL_ 1514 Radar 1 " Not display" 0 " Display" ;
VAL_ 1514 FuelConsumptionCorrect 3 "Configuration4" 2 "Configuration3" 1 "Configuration2" 0 "Configuration1" ;
VAL_ 1514 MaintainMileage 1 "International" 0 "China International" ;
VAL_ 1514 FirstMaintain 1 "International" 0 "China International" ;
VAL_ 1307 TirePosition 3 " RHR" 2 " LHR" 1 " RHF" 0 " LHF" ;
VAL_ 1307 TirePositionWarning_RHRTire 7 " Not used(Reserved)" 6 " Error Mode" 5 " High Temperature" 4 " High Pressure(Reserved)" 2 " Low Pressure" 1 " Rapid Air Loss(Reserved) " 0 " Normal" ;
VAL_ 1307 TirePositionWarning_LHRTire 7 " Not used(Reserved)" 6 " Error Mode" 5 " High Temperature" 4 " High Pressure(Reserved)" 2 " Low Pressure" 1 " Rapid Air Loss(Reserved)" 0 " Normal" ;
VAL_ 1307 TirePositionWarning_RHFTire 7 " Not used(Reserved)" 6 " Error Mode" 5 " High Temperature" 4 " High Pressure(Reserved)" 2 " Low Pressure" 1 " Rapid Air Loss(Reserved)" 0 " Normal" ;
VAL_ 1307 TirePositionWarning_LHFTire 7 " Not used(Reserved)" 6 " Error Mode" 5 " High Temperature" 4 " High Pressure(Reserved)" 2 " Low Pressure" 1 " Rapid Air Loss(Reserved)" 0 " Normal" ;
VAL_ 1307 TirePressureWarningLampSts 3 " Not used" 2 " Lamp On" 1 " Lamp Flashing(Reserved)" 0 " Lamp Off" ;
VAL_ 1307 TirePressureSystemFailSts 1 " Fail Present" 0 " Fail Not Present" ;
VAL_ 914 RearFoglightFaultSts 1 " Failure" 0 " Normal" ;
VAL_ 914 BCM_4_ChildSafetySts 3 " Failure" 2 " Lock" 1 " Unlock" 0 " Not Used" ;
VAL_ 914 WiperSensitivitySWSts 7 " Not Used" 6 " Not Used" 5 " High Sens" 4 " Med High Sens" 3 " Med Sens" 2 " Med Low Sens" 1 " Low Sens" 0 " Not active" ;
VAL_ 914 RainSensorFailSts 1 " Fail Present" 0 " Fail Not Present" ;
VAL_ 914 ReversinglampFaultSts 1 " Failure" 0 " Normal" ;
VAL_ 914 BCM_4_FrontFogLightSts 1 " Active" 0 " Off" ;
VAL_ 914 BrakelampFaultSts 1 " Failure" 0 " Normal" ;
VAL_ 914 BCM_4_ReverseGearSts 1 " Active" 0 " Off" ;
VAL_ 914 BCM_4_RearFogLightSts 1 " Active" 0 " Off" ;
VAL_ 914 BCM_4_TrunkSts 1 " Open" 0 " Close" ;
VAL_ 914 BCM_4_LHRdoorSts 1 " Open" 0 " Close" ;
VAL_ 914 BCM_4_RHRDoorSts 1 " Open" 0 " Close" ;
VAL_ 914 BCM_4_HoodSts 1 " Open" 0 " Close" ;
VAL_ 914 BCM_4_PsngrDoorSts 1 " Open" 0 " Close" ;
VAL_ 914 BCM_4_DriverDoorSts 1 " Open" 0 " Close" ;
VAL_ 914 FollowMeTimeSts 8 " Eight times" 7 " Seven times" 6 " Six times" 5 " Five times" 4 " Four times" 3 " Three times" 2 " Two times" 1 " One time" 0 " Not active" ;
VAL_ 914 RVSMode 1 " Active" 0 " Not active" ;
VAL_ 914 BCM_4_DirectionIndLeft 1 " Active" 0 " Not active" ;
VAL_ 914 BCM_4_DirectionIndRight 1 " Active" 0 " Not active" ;
VAL_ 914 BCM_4_DRLSts 1 " Active" 0 " Off" ;
VAL_ 914 BCM_4_HighBeamSts 1 " Active" 0 " Off" ;
VAL_ 914 BCM_4_ParkLightSts 1 " Active" 0 " Off" ;
VAL_ 914 BCM_4_LHTurnlightSts 1 " Active" 0 " Off" ;
VAL_ 914 BCM_4_RHTurnlightSts 1 " Active" 0 " Off" ;
VAL_ 914 BCM_4_KeySts 3 " CRANK + ON" 2 " ON" 1 " ACC" 0 " OFF" ;
VAL_ 914 LightDetected 1 " Bright" 0 " Dark" ;
VAL_ 914 KeyRemindWarning 1 " Active" 0 " Off" ;
VAL_ 914 BCM_4_ArmingSts 3 " Invalid" 2 " Disarming successful" 1 " Arming successful" 0 " Not active" ;
VAL_ 1059 LDWWorkingSts 3 " Standby" 2 " Failure" 1 " On" 0 " Off" ;
VAL_ 1059 LDWWarningSts 3 " Not Used" 2 " Right Warning" 1 " Left Warning" 0 " Off" ;
VAL_ 1059 LDWLaneDetectionSts 3 " Both sides deteced" 2 " Only left lane deteced" 1 " Only right lane deteced" 0 " No detection of both sides" ;
VAL_ 1088 RadarWorkSts 1 " Active" 0 " Not active" ;
VAL_ 1088 RadarDetectSts 3 " Not used" 2 " Rear Radar detecting" 1 " Front Radar detecting" 0 " No detecting" ;
VAL_ 1088 AudibleBeepRate 7 " Not used" 6 " Not used" 5 " Not used" 4 " 1Hz" 3 " 2Hz" 2 " 4Hz" 1 " On" 0 " Off" ;
VAL_ 1088 LHMFRadarSensorDistance 29 " Not used" 28 " Not used" ;
VAL_ 1088 RHMFRadarSensorDistance 29 " Not used" 28 " Not used" ;
VAL_ 1088 RHFRadarSensorDistance 29 " Not used" 28 " Not used" ;
VAL_ 1088 LHFRadarSensorDistance 29 " Not used" 28 " Not used" ;
VAL_ 1088 RHRRadarSensorDistance 61 " Not used" 60 " Not used" 59 " Not used" 58 " Not used" 57 " Not used" 56 " Not used" 55 " Not used" 54 " Not used" 53 " Not used" 52 " Not used" 51 " Not used" 50 " Not used" 49 " Not used" 48 " Not used" 47 " Not used" 46 " Not used" 45 " Not used" 44 " Not used" 43 " Not used" 42 " Not used" 41 " Not used" 40 " Not used" 39 " Not used" 38 " Not used" 37 " Not used" 36 " Not used" 35 " Not used" 34 " Not used" 33 " Not used" 32 " Not used" ;
VAL_ 1088 LHMRRadarSensorDistance 61 " Not used" 60 " Not used" 59 " Not used" 58 " Not used" 57 " Not used" 56 " Not used" 55 " Not used" 54 " Not used" 53 " Not used" 52 " Not used" 51 " Not used" 50 " Not used" 49 " Not used" 48 " Not used" 47 " Not used" 46 " Not used" 45 " Not used" 44 " Not used" 43 " Not used" 42 " Not used" 41 " Not used" 40 " Not used" 39 " Not used" 38 " Not used" 37 " Not used" 36 " Not used" 35 " Not used" 34 " Not used" 33 " Not used" 32 " Not used" ;
VAL_ 1088 RHMRRadarSensorDistance 61 " Not used" 60 " Not used" 59 " Not used" 58 " Not used" 57 " Not used" 56 " Not used" 55 " Not used" 54 " Not used" 53 " Not used" 52 " Not used" 51 " Not used" 50 " Not used" 49 " Not used" 48 " Not used" 47 " Not used" 46 " Not used" 45 " Not used" 44 " Not used" 43 " Not used" 42 " Not used" 41 " Not used" 40 " Not used" 39 " Not used" 38 " Not used" 37 " Not used" 36 " Not used" 35 " Not used" 34 " Not used" 33 " Not used" 32 " Not used" ;
VAL_ 1088 LHRRadarSensorDistance 61 " Not used" 60 " Not used" 59 " Not used" 58 " Not used" 57 " Not used" 56 " Not used" 55 " Not used" 54 " Not used" 53 " Not used" 52 " Not used" 51 " Not used" 50 " Not used" 49 " Not used" 48 " Not used" 47 " Not used" 46 " Not used" 45 " Not used" 44 " Not used" 43 " Not used" 42 " Not used" 41 " Not used" 40 " Not used" 39 " Not used" 38 " Not used" 37 " Not used" 36 " Not used" 35 " Not used" 34 " Not used" 33 " Not used" 32 " Not used" ;
